VERSION ""

NS_ :

BS_:

BU_: BCM BSM DIAG_TEST ECM EPS IPC MTA ORC PAM

BO_ 2654339098 PDC_INFO_ORC: 3 ORC
 SG_ CurrentFailSts_ORC : 6|1@0+ (1,0) [0|1] ""  BCM
 SG_ DES_ORC : 4|1@0+ (1,0) [0|1] "" Vector__XXX
 SG_ EOL_ORC : 7|1@0+ (1,0) [0|1] "-"  BCM
 SG_ GenericFailSts_ORC : 5|1@0+ (1,0) [0|1] ""  BCM
 SG_ Reserved_for_PDC_ORC : 3|4@0+ (1,0) [0|0] "" Vector__XXX
 SG_ StayActiveSource_ORC_0 : 15|1@0+ (1,0) [0|1] "" Vector__XXX
 SG_ StayActiveSource_ORC_1 : 14|1@0+ (1,0) [0|1] "" Vector__XXX
 SG_ StayActiveSource_ORC_10 : 21|1@0+ (1,0) [0|1] "" Vector__XXX
 SG_ StayActiveSource_ORC_11 : 20|1@0+ (1,0) [0|1] "" Vector__XXX
 SG_ StayActiveSource_ORC_12 : 19|1@0+ (1,0) [0|1] "" Vector__XXX
 SG_ StayActiveSource_ORC_13 : 18|1@0+ (1,0) [0|1] "" Vector__XXX
 SG_ StayActiveSource_ORC_14 : 17|1@0+ (1,0) [0|1] "" Vector__XXX
 SG_ StayActiveSource_ORC_15 : 16|1@0+ (1,0) [0|1] "" Vector__XXX
 SG_ StayActiveSource_ORC_2 : 13|1@0+ (1,0) [0|1] "" Vector__XXX
 SG_ StayActiveSource_ORC_3 : 12|1@0+ (1,0) [0|1] "" Vector__XXX
 SG_ StayActiveSource_ORC_4 : 11|1@0+ (1,0) [0|1] "" Vector__XXX
 SG_ StayActiveSource_ORC_5 : 10|1@0+ (1,0) [0|1] "" Vector__XXX
 SG_ StayActiveSource_ORC_6 : 9|1@0+ (1,0) [0|1] "" Vector__XXX
 SG_ StayActiveSource_ORC_7 : 8|1@0+ (1,0) [0|1] "" Vector__XXX
 SG_ StayActiveSource_ORC_8 : 23|1@0+ (1,0) [0|1] "" Vector__XXX
 SG_ StayActiveSource_ORC_9 : 22|1@0+ (1,0) [0|1] "" Vector__XXX

BO_ 2654339096 PDC_INFO_PAM: 3 PAM
 SG_ CurrentFailSts_PAM : 6|1@0+ (1,0) [0|1] ""  BCM
 SG_ DES_PAM : 4|1@0+ (1,0) [0|1] "" Vector__XXX
 SG_ EOL_PAM : 7|1@0+ (1,0) [0|1] "-"  BCM
 SG_ GenericFailSts_PAM : 5|1@0+ (1,0) [0|1] ""  BCM
 SG_ Reserved_for_PDC_PAM : 3|4@0+ (1,0) [0|0] "" Vector__XXX
 SG_ StayActiveSource_PAM_0 : 15|1@0+ (1,0) [0|1] "" Vector__XXX
 SG_ StayActiveSource_PAM_1 : 14|1@0+ (1,0) [0|1] "" Vector__XXX
 SG_ StayActiveSource_PAM_10 : 21|1@0+ (1,0) [0|1] "" Vector__XXX
 SG_ StayActiveSource_PAM_11 : 20|1@0+ (1,0) [0|1] "" Vector__XXX
 SG_ StayActiveSource_PAM_12 : 19|1@0+ (1,0) [0|1] "" Vector__XXX
 SG_ StayActiveSource_PAM_13 : 18|1@0+ (1,0) [0|1] "" Vector__XXX
 SG_ StayActiveSource_PAM_14 : 17|1@0+ (1,0) [0|1] "" Vector__XXX
 SG_ StayActiveSource_PAM_15 : 16|1@0+ (1,0) [0|1] "" Vector__XXX
 SG_ StayActiveSource_PAM_2 : 13|1@0+ (1,0) [0|1] "" Vector__XXX
 SG_ StayActiveSource_PAM_3 : 12|1@0+ (1,0) [0|1] "" Vector__XXX
 SG_ StayActiveSource_PAM_4 : 11|1@0+ (1,0) [0|1] "" Vector__XXX
 SG_ StayActiveSource_PAM_5 : 10|1@0+ (1,0) [0|1] "" Vector__XXX
 SG_ StayActiveSource_PAM_6 : 9|1@0+ (1,0) [0|1] "" Vector__XXX
 SG_ StayActiveSource_PAM_7 : 8|1@0+ (1,0) [0|1] "" Vector__XXX
 SG_ StayActiveSource_PAM_8 : 23|1@0+ (1,0) [0|1] "" Vector__XXX
 SG_ StayActiveSource_PAM_9 : 22|1@0+ (1,0) [0|1] "" Vector__XXX

BO_ 2654339083 PDC_INFO_TRANSMISSION: 3 MTA
 SG_ CurrentFailSts_TRANSM : 6|1@0+ (1,0) [0|1] ""  BCM
 SG_ DES_TRANSM : 4|1@0+ (1,0) [0|1] "" Vector__XXX
 SG_ EOL_TRANSM : 7|1@0+ (1,0) [0|1] "-"  BCM
 SG_ GenericFailSts_TRANSM : 5|1@0+ (1,0) [0|1] ""  BCM
 SG_ Reserved_for_PDC_TRANSM : 3|4@0+ (1,0) [0|0] "" Vector__XXX
 SG_ StayActiveSource_TRANSM_0 : 15|1@0+ (1,0) [0|1] "" Vector__XXX
 SG_ StayActiveSource_TRANSM_1 : 14|1@0+ (1,0) [0|1] "" Vector__XXX
 SG_ StayActiveSource_TRANSM_10 : 21|1@0+ (1,0) [0|1] "" Vector__XXX
 SG_ StayActiveSource_TRANSM_11 : 20|1@0+ (1,0) [0|1] "" Vector__XXX
 SG_ StayActiveSource_TRANSM_12 : 19|1@0+ (1,0) [0|1] "" Vector__XXX
 SG_ StayActiveSource_TRANSM_13 : 18|1@0+ (1,0) [0|1] "" Vector__XXX
 SG_ StayActiveSource_TRANSM_14 : 17|1@0+ (1,0) [0|1] "" Vector__XXX
 SG_ StayActiveSource_TRANSM_15 : 16|1@0+ (1,0) [0|1] "" Vector__XXX
 SG_ StayActiveSource_TRANSM_2 : 13|1@0+ (1,0) [0|1] "" Vector__XXX
 SG_ StayActiveSource_TRANSM_3 : 12|1@0+ (1,0) [0|1] "" Vector__XXX
 SG_ StayActiveSource_TRANSM_4 : 11|1@0+ (1,0) [0|1] "" Vector__XXX
 SG_ StayActiveSource_TRANSM_5 : 10|1@0+ (1,0) [0|1] "" Vector__XXX
 SG_ StayActiveSource_TRANSM_6 : 9|1@0+ (1,0) [0|1] "" Vector__XXX
 SG_ StayActiveSource_TRANSM_7 : 8|1@0+ (1,0) [0|1] "" Vector__XXX
 SG_ StayActiveSource_TRANSM_8 : 23|1@0+ (1,0) [0|1] "" Vector__XXX
 SG_ StayActiveSource_TRANSM_9 : 22|1@0+ (1,0) [0|1] "" Vector__XXX

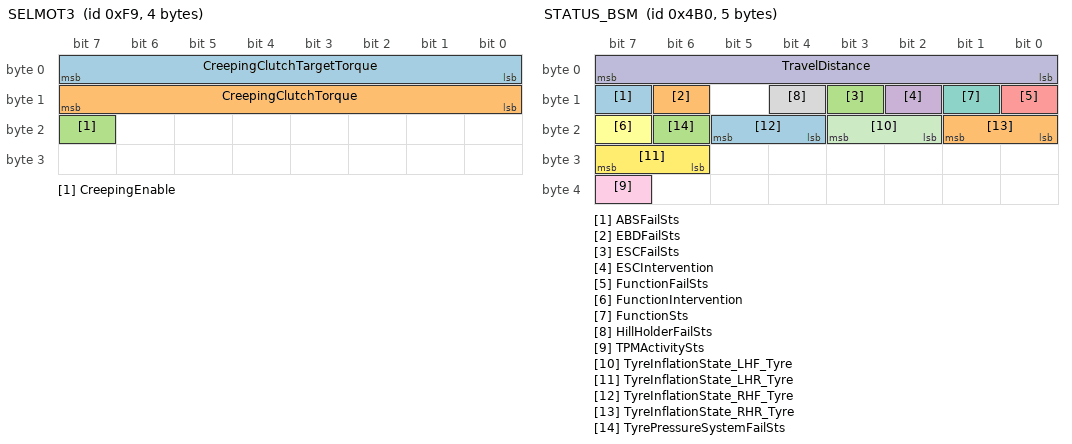
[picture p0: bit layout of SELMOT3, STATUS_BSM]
BO_ 249 SELMOT3: 4 MTA
 SG_ CreepingClutchTargetTorque : 7|8@0+ (1,0) [0|255] "Nm"  ECM
 SG_ CreepingClutchTorque : 15|8@0+ (1,0) [0|255] "Nm"  ECM
 SG_ CreepingEnable : 23|1@0+ (1,0) [0|1] ""  ECM

BO_ 1200 STATUS_BSM: 5 BSM
 SG_ ABSFailSts : 15|1@0+ (1,0) [0|1] "-"  IPC,MTA
 SG_ EBDFailSts : 14|1@0+ (1,0) [0|1] "-"  IPC
 SG_ ESCFailSts : 11|1@0+ (1,0) [0|1] "-"  IPC,MTA
 SG_ ESCIntervention : 10|1@0+ (1,0) [0|1] "-"  IPC,MTA
 SG_ FunctionFailSts : 8|1@0+ (1,0) [0|1] "-" Vector__XXX
 SG_ FunctionIntervention : 23|1@0+ (1,0) [0|1] "-" Vector__XXX
 SG_ FunctionSts : 9|1@0+ (1,0) [0|1] "-"  IPC
 SG_ HillHolderFailSts : 12|1@0+ (1,0) [0|1] "-"  ECM,IPC,MTA
 SG_ TPMActivitySts : 39|1@0+ (1,0) [0|1] ""  IPC
 SG_ TravelDistance : 7|8@0+ (9.8,0) [0|2489.2] "m"  BCM,ECM,IPC
 SG_ TyreInflationState_LHF_Tyre : 19|2@0+ (1,0) [0|3] ""  IPC
 SG_ TyreInflationState_LHR_Tyre : 31|2@0+ (1,0) [0|3] ""  IPC
 SG_ TyreInflationState_RHF_Tyre : 21|2@0+ (1,0) [0|3] ""  IPC
 SG_ TyreInflationState_RHR_Tyre : 17|2@0+ (1,0) [0|3] ""  IPC
 SG_ TyrePressureSystemFailSts : 22|1@0+ (1,0) [0|1] ""  IPC

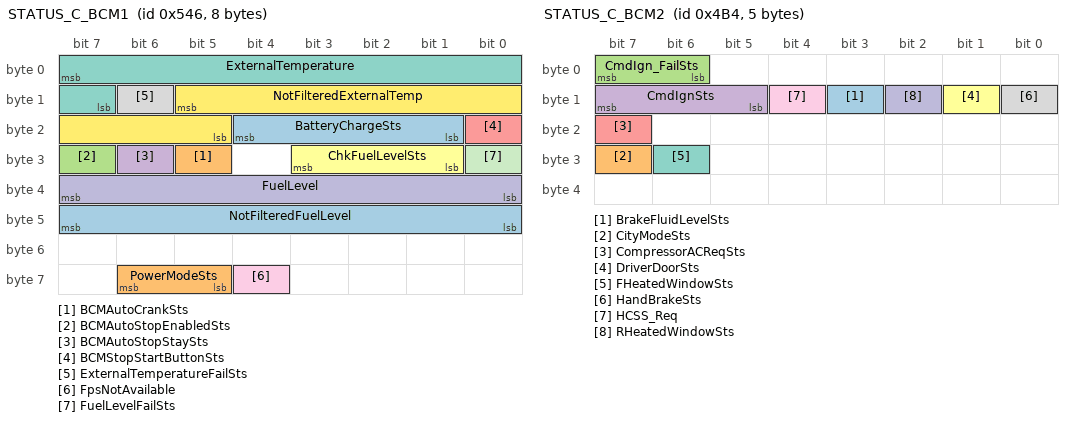
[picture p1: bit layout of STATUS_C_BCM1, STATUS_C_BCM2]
BO_ 1350 STATUS_C_BCM1: 8 BCM
 SG_ BatteryChargeSts : 20|4@0+ (5,40) [40|110] "%"  ECM
 SG_ BCMAutoCrankSts : 29|1@0+ (1,0) [0|1] "-"  ECM
 SG_ BCMAutoStopEnabledSts : 31|1@0+ (1,0) [0|1] "-"  ECM
 SG_ BCMAutoStopStaySts : 30|1@0+ (1,0) [0|1] "-"  ECM
 SG_ BCMStopStartButtonSts : 16|1@0+ (1,0) [0|1] "-"  ECM
 SG_ ChkFuelLevelSts : 27|3@0+ (1,0) [0|7] "-" Vector__XXX
 SG_ ExternalTemperature : 7|9@0+ (0.5,-85) [-85|170] "°C"  BSM,ECM,MTA
 SG_ ExternalTemperatureFailSts : 14|1@0+ (1,0) [0|1] ""  BSM,ECM,MTA
 SG_ FpsNotAvailable : 60|1@0+ (1,0) [0|1] ""  IPC
 SG_ FuelLevel : 39|8@0+ (1,0) [0|255] "%"  ECM,IPC
 SG_ FuelLevelFailSts : 24|1@0+ (1,0) [0|1] ""  ECM,IPC
 SG_ NotFilteredExternalTemp : 13|9@0+ (0.5,-85) [-85|170] "°C" Vector__XXX
 SG_ NotFilteredFuelLevel : 47|8@0+ (2,0) [0|508] "Ohm"  ECM
 SG_ PowerModeSts : 62|2@0+ (1,0) [0|3] "-"  IPC

BO_ 1204 STATUS_C_BCM2: 5 BCM
 SG_ BrakeFluidLevelSts : 11|1@0+ (1,0) [0|1] ""  IPC
 SG_ CityModeSts : 31|1@0+ (1,0) [0|1] "-"  EPS,IPC
 SG_ CmdIgn_FailSts : 7|2@0+ (1,0) [0|3] ""  BSM,ECM,EPS,IPC,MTA,PAM
 SG_ CmdIgnSts : 15|3@0+ (1,0) [0|7] ""  BSM,ECM,EPS,IPC,MTA,ORC,PAM
 SG_ CompressorACReqSts : 23|1@0+ (1,0) [0|1] "-"  ECM
 SG_ DriverDoorSts : 9|1@0+ (1,0) [0|1] ""  MTA
 SG_ FHeatedWindowSts : 30|1@0+ (1,0) [0|1] ""  ECM
 SG_ HandBrakeSts : 8|1@0+ (1,0) [0|1] "-"  BSM,ECM,IPC,MTA
 SG_ HCSS_Req : 12|1@0+ (1,0) [0|1] ""  ECM
 SG_ RHeatedWindowSts : 10|1@0+ (1,0) [0|1] "" Vector__XXX

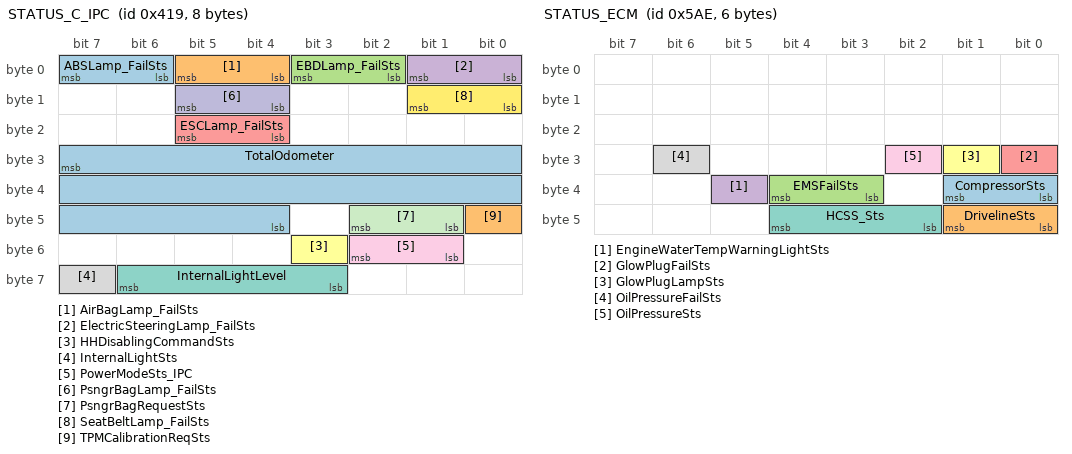
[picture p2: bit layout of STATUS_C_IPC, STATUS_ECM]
BO_ 1049 STATUS_C_IPC: 8 IPC
 SG_ ABSLamp_FailSts : 7|2@0+ (1,0) [0|3] "-"  BSM
 SG_ AirBagLamp_FailSts : 5|2@0+ (1,0) [0|3] "-"  ORC
 SG_ EBDLamp_FailSts : 3|2@0+ (1,0) [0|3] "-"  BSM
 SG_ ElectricSteeringLamp_FailSts : 1|2@0+ (1,0) [0|3] "-"  EPS
 SG_ ESCLamp_FailSts : 21|2@0+ (1,0) [0|0] "-"  BSM
 SG_ HHDisablingCommandSts : 51|1@0+ (1,0) [0|1] ""  BSM
 SG_ InternalLightLevel : 62|4@0+ (1,0) [0|15] "" Vector__XXX
 SG_ InternalLightSts : 63|1@0+ (1,0) [0|1] ""  BCM
 SG_ PowerModeSts_IPC : 50|2@0+ (1,0) [0|3] ""  BCM
 SG_ PsngrBagLamp_FailSts : 13|2@0+ (1,0) [0|3] "-"  ORC
 SG_ PsngrBagRequestSts : 42|2@0+ (1,0) [0|3] "-"  ORC
 SG_ SeatBeltLamp_FailSts : 9|2@0+ (1,0) [0|3] "-"  ORC
 SG_ TotalOdometer : 31|20@0+ (1,0) [0|1048575] "km"  EPS,BSM,ECM,MTA,ORC,PAM
 SG_ TPMCalibrationReqSts : 40|1@0+ (1,0) [0|1] ""  BSM

BO_ 1454 STATUS_ECM: 6 ECM
 SG_ CompressorSts : 33|2@0+ (1,0) [0|3] "-"  BCM,MTA
 SG_ DrivelineSts : 41|2@0+ (1,0) [0|3] ""  IPC
 SG_ EMSFailSts : 36|2@0+ (1,0) [0|3] "-"  IPC
 SG_ EngineWaterTempWarningLightSts : 37|1@0+ (1,0) [0|1] "-"  IPC
 SG_ GlowPlugFailSts : 24|1@0+ (1,0) [0|1] "-"  IPC
 SG_ GlowPlugLampSts : 25|1@0+ (1,0) [0|1] "-"  IPC
 SG_ HCSS_Sts : 44|3@0+ (1,0) [0|7] "-"  BCM
 SG_ OilPressureFailSts : 30|1@0+ (1,0) [0|1] "-"  IPC
 SG_ OilPressureSts : 26|1@0+ (1,0) [0|1] "-"  IPC

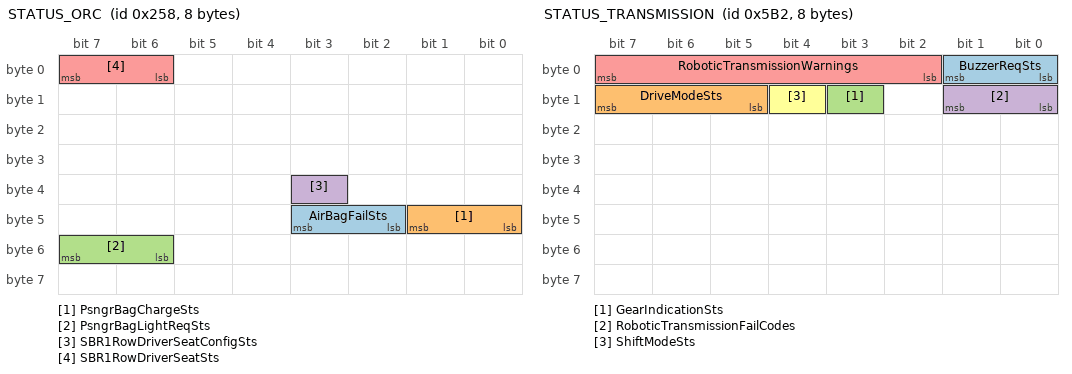
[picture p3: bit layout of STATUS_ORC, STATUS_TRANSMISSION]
BO_ 600 STATUS_ORC: 8 ORC
 SG_ AirBagFailSts : 43|2@0+ (1,0) [0|3] "-"  IPC
 SG_ PsngrBagChargeSts : 41|2@0+ (1,0) [0|3] "-"  IPC
 SG_ PsngrBagLightReqSts : 55|2@0+ (1,0) [0|3] ""  IPC
 SG_ SBR1RowDriverSeatConfigSts : 35|1@0+ (1,0) [0|1] "-"  IPC
 SG_ SBR1RowDriverSeatSts : 7|2@0+ (1,0) [0|3] "-"  BCM,IPC

BO_ 1354 STATUS_PAM: 4 PAM
 SG_ PAMSystemFault : 13|2@0+ (1,0) [0|3] "-"  IPC
 SG_ PAMSystemSts : 9|2@0+ (1,0) [0|3] ""  IPC

BO_ 1458 STATUS_TRANSMISSION: 8 MTA
 SG_ BuzzerReqSts : 1|2@0+ (1,0) [0|2] "-"  IPC
 SG_ DriveModeSts : 15|3@0+ (1,0) [0|4] "-"  ECM,IPC
 SG_ GearIndicationSts : 11|1@0+ (1,0) [0|1] "-"  IPC
 SG_ RoboticTransmissionFailCodes : 9|2@0+ (1,0) [0|3] "-"  IPC
 SG_ RoboticTransmissionWarnings : 7|6@0+ (1,0) [0|10] "-"  IPC
 SG_ ShiftModeSts : 12|1@0+ (1,0) [0|1] "-"  BCM,IPC

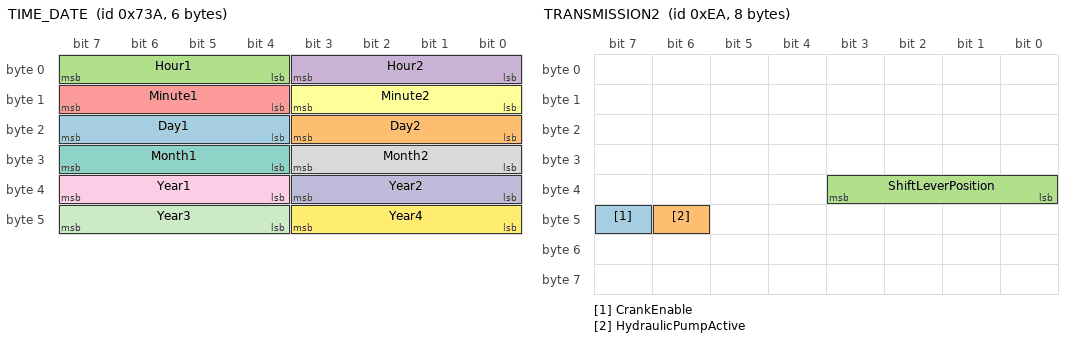
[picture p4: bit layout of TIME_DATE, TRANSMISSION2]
BO_ 1850 TIME_DATE: 6 IPC
 SG_ Day1 : 23|4@0+ (1,0) [0|9] "-"  BSM,ECM
 SG_ Day2 : 19|4@0+ (1,0) [0|9] "-"  BSM,ECM
 SG_ Hour1 : 7|4@0+ (1,0) [0|9] "-"  BSM,ECM
 SG_ Hour2 : 3|4@0+ (1,0) [0|9] "-"  BSM,ECM
 SG_ Minute1 : 15|4@0+ (1,0) [0|9] "-"  BSM,ECM
 SG_ Minute2 : 11|4@0+ (1,0) [0|9] "-"  BSM,ECM
 SG_ Month1 : 31|4@0+ (1,0) [0|9] "-"  BSM,ECM
 SG_ Month2 : 27|4@0+ (1,0) [0|9] "-"  BSM,ECM
 SG_ Year1 : 39|4@0+ (1,0) [0|9] "-"  BSM,ECM
 SG_ Year2 : 35|4@0+ (1,0) [0|9] "-"  BSM,ECM
 SG_ Year3 : 47|4@0+ (1,0) [0|9] "-"  BSM,ECM
 SG_ Year4 : 43|4@0+ (1,0) [0|9] "-"  BSM,ECM

BO_ 1000 TPM_CAL: 1 BSM
 SG_ CalibrationAck : 5|2@0+ (1,0) [0|3] "-"  IPC

BO_ 246 TRANSMISSION1: 8 MTA
 SG_ ClutchEngaged : 7|2@0+ (1,0) [0|3] "-"  ECM
 SG_ CRC_T1 : 63|8@0+ (1,0) [0|255] "-"  ECM
 SG_ DriveOff : 5|1@0+ (1,0) [0|1] "-"  ECM
 SG_ EngineStopSignal : 4|1@0+ (1,0) [0|1] "-"  ECM
 SG_ GearBoxAutomaticMode : 15|1@0+ (1,0) [0|1] "-"  ECM
 SG_ GearEngaged : 3|4@0+ (1,0) [0|15] "-"  BSM,ECM,IPC
 SG_ LeverPosition : 35|4@0+ (1,0) [0|15] "-"  ECM
 SG_ LimpHomeSts : 14|1@0+ (1,0) [0|1] "-"  ECM
 SG_ MessageCounter_T1 : 51|4@0+ (1,0) [0|15] ""  ECM
 SG_ ReqTorqueValue : 47|11@0+ (1,-500) [-500|1547] "Nm"  ECM
 SG_ ReqTorqueValueCost : 11|1@0+ (1,0) [0|1] "-"  ECM
 SG_ ReqTorqueValueDown : 10|1@0+ (1,0) [0|1] "-"  ECM
 SG_ ReqTorqueValueUp : 9|1@0+ (1,0) [0|1] "-"  ECM
 SG_ TakeOffModeReq : 13|2@0+ (1,0) [0|3] "-"  ECM
 SG_ TakeOffRPMValueReq : 31|10@0+ (10,0) [0|0] "rpm"  ECM
 SG_ TorqueControl : 8|1@0+ (1,0) [0|1] "-"  ECM
 SG_ UpDownShiftSel : 37|1@0+ (1,0) [0|1] "-"  ECM

BO_ 234 TRANSMISSION2: 8 MTA
 SG_ CrankEnable : 47|1@0+ (1,0) [0|1] ""  BCM,ECM
 SG_ HydraulicPumpActive : 46|1@0+ (1,0) [0|1] ""  ECM
 SG_ ShiftLeverPosition : 35|4@0+ (1,0) [0|15] "-"  BCM,BSM,ECM

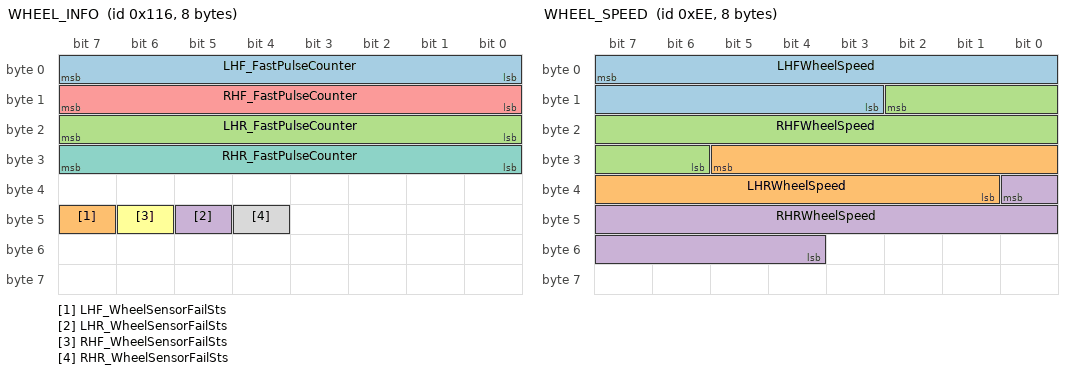
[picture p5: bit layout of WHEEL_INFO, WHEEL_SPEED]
BO_ 278 WHEEL_INFO: 8 BSM
 SG_ LHF_FastPulseCounter : 7|8@0+ (1,0) [0|255] "pulse"  BCM
 SG_ LHF_WheelSensorFailSts : 47|1@0+ (1,0) [0|1] "-"  BCM
 SG_ LHR_FastPulseCounter : 23|8@0+ (1,0) [0|255] "pulse"  BCM
 SG_ LHR_WheelSensorFailSts : 45|1@0+ (1,0) [0|1] "-"  BCM
 SG_ RHF_FastPulseCounter : 15|8@0+ (1,0) [0|255] "pulse"  BCM
 SG_ RHF_WheelSensorFailSts : 46|1@0+ (1,0) [0|1] "-"  BCM
 SG_ RHR_FastPulseCounter : 31|8@0+ (1,0) [0|255] "pulse"  BCM
 SG_ RHR_WheelSensorFailSts : 44|1@0+ (1,0) [0|1] "-"  BCM

BO_ 238 WHEEL_SPEED: 8 BSM
 SG_ LHFWheelSpeed : 7|13@0+ (0.0625,0) [0|512] "Km/h"  ECM,MTA
 SG_ LHRWheelSpeed : 29|13@0+ (0.0625,0) [0|512] "Km/h"  ECM,MTA
 SG_ RHFWheelSpeed : 10|13@0+ (0.0625,0) [0|512] "Km/h"  ECM,MTA
 SG_ RHRWheelSpeed : 32|13@0+ (0.0625,0) [0|512] "Km/h"  ECM,MTA

CM_ SG_ 249 CreepingClutchTargetTorque "Clutch torque reference in creeping phase";
CM_ SG_ 249 CreepingClutchTorque "Clutch torque saturation actuted in creeping phase";
CM_ SG_ 249 CreepingEnable "TCU Creeping phase active";
CM_ SG_ 1200 ABSFailSts "This signal indicates when ABS functionality is in fail";
CM_ SG_ 1200 EBDFailSts "This signal indicates when EBD functionality is in fail";
CM_ SG_ 1200 ESCFailSts "This signal indicates when ESC functionality is in fail.";
CM_ SG_ 1200 ESCIntervention "This signal indicates when the ESC functionality is acting.";
CM_ SG_ 1200 FunctionFailSts "This signal indicates when ASR/TC functionality is in fail.";
CM_ SG_ 1200 FunctionIntervention "This signal indicates when the TC or ASR or ELD (where present) functionality are acting.";
CM_ SG_ 1200 FunctionSts "This signal is set to ?Pressed? when the BSM Button is pressed for the first time inside an ignition cycle . This signal is available only on ESC variants with BSM Button.";
CM_ SG_ 1200 HillHolderFailSts "This signal indicates when Hill Holder functionality is in fail";
CM_ SG_ 1200 TPMActivitySts "It indicates if the module is enabled or disabled.";
CM_ SG_ 1200 TravelDistance "This signal indicates the travel distance value.";
CM_ SG_ 1200 TyreInflationState_LHF_Tyre "It indicates the inflation state of the tyre.";
CM_ SG_ 1200 TyreInflationState_LHR_Tyre "It indicates the inflation state of the tyre.";
CM_ SG_ 1200 TyreInflationState_RHF_Tyre "It indicates the inflation state of the tyre.";
CM_ SG_ 1200 TyreInflationState_RHR_Tyre "It indicates the inflation state of the tyre.";
CM_ SG_ 1200 TyrePressureSystemFailSts "It indicates the presence of the failure.";
CM_ SG_ 1350 BatteryChargeSts "Signal the battery state of charge, as measured by the battery sensor";
CM_ SG_ 1350 BCMAutoCrankSts "This signal indicates to ECM the possibility for ECM, when the engine is in automatic stop, to allow an automatic engine recranking or to allow a recranking of the engine only by a transition keyoff/keyon.";
CM_ SG_ 1350 BCMAutoStopEnabledSts "This signal indicates to the ECM the conditions managed by BCM needed for enabling the automatic stop.";
CM_ SG_ 1350 BCMAutoStopStaySts "This signal indicates the possibility for the ECM, when the engine is in automatic stop, to remain in Automatic Engine Stop condition or automatically recrank the engine.";
CM_ SG_ 1350 BCMStopStartButtonSts "BCM request to the ECM for the Stop&Start management";
CM_ SG_ 1350 ChkFuelLevelSts "This signal gives indication about diagnostic of CILC.";
CM_ SG_ 1350 ExternalTemperature "The ExternalTemperature signal is a External Temperature value acquired by the External Temperature Sensor. This value is \"filtered\" with the purpose to return reliable values.";
CM_ SG_ 1350 ExternalTemperatureFailSts "The ExternalTemperatureFailSts signal is a Fail Status Bit for the ExternalTemperature signal.";
CM_ SG_ 1350 FpsNotAvailable "It's used by BCM to inform IPC that Safety Fuel Shut Off function is not available";
CM_ SG_ 1350 FuelLevel "The signal represents fuel level and it is expressed in percentage with respect to the tank nominal capacity.";
CM_ SG_ 1350 FuelLevelFailSts "It is the Fail Status bit of FuelLevel signal.";
CM_ SG_ 1350 NotFilteredExternalTemp "This signal represents External Temperature value measured by related sensor. Its value is not filtered by BCM internal strategies.";
CM_ SG_ 1350 NotFilteredFuelLevel "This signal represents Fuel Level value measured by related sensor. Its value is not filtered by BCM internal strategies.";
CM_ SG_ 1350 PowerModeSts "This signal indicates if the vehicle is in Logistic Mode status or in Standard Mode status.";
CM_ SG_ 1204 BrakeFluidLevelSts "This signal indicates when the brake fluid level is low or normal.";
CM_ SG_ 1204 CityModeSts "It is the information about city/eco/power/sport mode";
CM_ SG_ 1204 CmdIgnSts "Used to give information about the key selector position";
CM_ SG_ 1204 CompressorACReqSts "This signal is sent from BCM to ECM to inform of Compressor AC activation request";
CM_ SG_ 1204 DriverDoorSts "This signal indicates the driver door status";
CM_ SG_ 1204 FHeatedWindowSts "The signal indicates the effective activation of heated front window.";
CM_ SG_ 1204 HandBrakeSts "This signal indicates the hand brake status (inserted or not).";
CM_ SG_ 1204 HCSS_Req "The signal is used to request the HCSS activation.";
CM_ SG_ 1204 RHeatedWindowSts "The signal indicates the effective activation of heated rear window.";
CM_ SG_ 1049 ABSLamp_FailSts "This signal communicates the status of the related lamp.";
CM_ SG_ 1049 AirBagLamp_FailSts "This signal is used to inform about the airbag warning light status";
CM_ SG_ 1049 EBDLamp_FailSts "This signal communicates the status of the related lamp.";
CM_ SG_ 1049 ElectricSteeringLamp_FailSts "This signal communicates the status of the related lamp.";
CM_ SG_ 1049 ESCLamp_FailSts "This signal communicates the status of the related lamp.";
CM_ SG_ 1049 HHDisablingCommandSts "This signal requires the disabling of Hill Holder functionality.";
CM_ SG_ 1049 InternalLightLevel "This signal is used to modulate the Internal Light Level";
CM_ SG_ 1049 InternalLightSts "This signal is used to manage the Internal Lights";
CM_ SG_ 1049 PsngrBagLamp_FailSts "This signal communicates the status of the related lamp.";
CM_ SG_ 1049 PsngrBagRequestSts "This signal is used by IPC to send the request of the customer to change the current status of Front Passenger Protection";
CM_ SG_ 1049 SeatBeltLamp_FailSts "This signal is used to inform about the SBR main lamp status";
CM_ SG_ 1049 TPMCalibrationReqSts "It indicates that the user requires to start the calibration procedure of TPI";
CM_ SG_ 1454 CompressorSts "This signal gives information about the present status of A/C external request and actual A/C activation by ECM.";
CM_ SG_ 1454 DrivelineSts "Gives the status of the driveline, based on clutch and/or neutral sensors";
CM_ SG_ 1454 EMSFailSts "This signal is used  to switch on and off the engine control system warning lamp (called MI for EOBD applications)";
CM_ SG_ 1454 EngineWaterTempWarningLightSts "It is the information about water overtemperature light status.";
CM_ SG_ 1454 GlowPlugFailSts "It is the information that a fault is detected by glow plug control unit.";
CM_ SG_ 1454 GlowPlugLampSts "It is the glow plug light command.";
CM_ SG_ 1454 HCSS_Sts "The signal indicates the HCSS phase.";
CM_ SG_ 1454 OilPressureFailSts "It is the Fail Status bit of OilPressure signal.";
CM_ SG_ 1454 OilPressureSts "This signal  indicates oil pressure status (High or low).";
CM_ SG_ 600 AirBagFailSts "This signal is used to require the activation/deactivation of airbag warning light";
CM_ SG_ 600 PsngrBagChargeSts "This signal is used to communicate the status of Front Passenger Protection Pyrotechnical charges";
CM_ SG_ 600 PsngrBagLightReqSts "This signal indicates the status of the Front Passenger Airbag Warning Lamp";
CM_ SG_ 600 SBR1RowDriverSeatConfigSts "Signal used to show if the first row driver seatbelt is under check";
CM_ SG_ 600 SBR1RowDriverSeatSts "First row driver seatbelt switch status";
CM_ SG_ 1354 PAMSystemFault "This signal indicates if the PAM is in a faulted condition";
CM_ SG_ 1354 PAMSystemSts "This signal indicates the activation state of the PAM";
CM_ SG_ 1458 BuzzerReqSts "It is used to activate the acoustic indicator.";
CM_ SG_ 1458 DriveModeSts "This signal indicates the mode selector switch condition selected by driver (Normal, Economy, Sport, Ice,...).";
CM_ SG_ 1458 GearIndicationSts "This signal is related to the displayed gear indication (if it is blinking or not)";
CM_ SG_ 1458 RoboticTransmissionFailCodes "This signal indicates if the MTA currently detects the failure or not (for MTA)";
CM_ SG_ 1458 RoboticTransmissionWarnings "This signal gives some instruction to the driver in case of malfunctioning (for MTA)";
CM_ SG_ 1458 ShiftModeSts "This signal indicates the gear selector modality selected by driver (Manual or Automatic).";
CM_ SG_ 1850 Day1 "It is the first digit of the day for the date visualization";
CM_ SG_ 1850 Day2 "It is the second digit of the day for the date visualization";
CM_ SG_ 1850 Hour1 "It is the first digit of the hours for the clock visualization";
CM_ SG_ 1850 Hour2 "It is the second digit of the hours for the clock visualization";
CM_ SG_ 1850 Minute1 "It is  the first digit of the minutes for the clock visualization";
CM_ SG_ 1850 Minute2 "It is the second digit of the minutes for the clock visualization";
CM_ SG_ 1850 Month1 "It is the first digit of the month for the date visualization";
CM_ SG_ 1850 Month2 "It is the second digit of the month for the date visualization";
CM_ SG_ 1850 Year1 "It is the first digit of the year for the date visualization";
CM_ SG_ 1850 Year2 "It is the second digit of the year for the date visualization";
CM_ SG_ 1850 Year3 "It is the third digit of the year for the date visualization";
CM_ SG_ 1850 Year4 "It is the fourth digit of the year for the date visualization";
CM_ SG_ 1000 CalibrationAck "It indicates the acknoledgment of calibration procedure request.";
CM_ SG_ 246 ClutchEngaged "It can be used to prevent engine stall by improving the idle condition entering strategy, in case of sudden engine speed drops (due, for instance, to hard braking action)";
CM_ SG_ 246 CRC_T1 "CRC according to SAE J1850 standard that has to be calculated from bit 63 to bit 8 at each frame transmission.";
CM_ SG_ 246 DriveOff "When the bit is switching from ON to OFF, the clutch is engaging and the vehicle is driving away from stop condition.";
CM_ SG_ 246 EngineStopSignal "This signal is used to stop the engine, when very critical failures occur to the gearbox.";
CM_ SG_ 246 GearBoxAutomaticMode "It indicates the gearbox operating mode (this is automatic when the signal value is 'Active' ).";
CM_ SG_ 246 GearEngaged "Current engaged gear.";
CM_ SG_ 246 LeverPosition "This signal indicates the position of the lever.";
CM_ SG_ 246 LimpHomeSts "This signal is used in case of those gearbox faults that limit the higher usable gear.";
CM_ SG_ 246 MessageCounter_T1 "This signal is a counter used for safety checks strategies. This counter is incremented of 1 (one) unit at each frame transmission.";
CM_ SG_ 246 ReqTorqueValue "This is the total indicated torque target requested from the gearbox  during gear shifts.";
CM_ SG_ 246 ReqTorqueValueCost "It indicates the 2nd phase of the torque request from the gearbox , i.e.: it is 'Active'  during the 2nd phase of a gear shift.
In this phase (new gear engagement) the clutch is open.";
CM_ SG_ 246 ReqTorqueValueDown "It indicates the 1st phase of the torque request from the gearbox , i.e.: it is 'Active' during the 1st phase of a gear shift.
In this phase (engine disconnection) the gearbox  is disengaging the clutch.";
CM_ SG_ 246 ReqTorqueValueUp "It indicates the 3rd phase of the torque request from the gearbox , i.e.: it is 'Active' during the 3rd phase of a gear shift.
In this phase (engine re-connection) the gearbox is re-engaging the clutch.";
CM_ SG_ 246 TakeOffModeReq "This signal indicates if either the torque control request or the torque/rpm control request are active during the take-off phase";
CM_ SG_ 246 TakeOffRPMValueReq "RPM set-point requested by gearbox during take-off phase. This signal is required and managed on Turbo Gasoline Engines only.";
CM_ SG_ 246 TorqueControl "It indicates a torque request from the gearbox , i.e.: it is 'Active' during all the three phases of a gear shift.";
CM_ SG_ 246 UpDownShiftSel "It is mainly foreseen for gasoline applications. This bit is set to ' Up'  during an up-shift and to ' Down'  during a down-shift.";
CM_ SG_ 234 CrankEnable "This signal is used to enable the cranking in safety condition";
CM_ SG_ 234 HydraulicPumpActive "This bit is  'Active'  when the electro-hydraulic pump is ON.
It can be used for engine idle control.";
CM_ SG_ 234 ShiftLeverPosition "This signal indicates the executed shift lever position.";
CM_ SG_ 278 LHF_FastPulseCounter "This signal is the left front wheel pulse counter.";
CM_ SG_ 278 LHF_WheelSensorFailSts "This signal indicates the fail status of LHF sensor";
CM_ SG_ 278 LHR_FastPulseCounter "This signal is the left rear wheel pulse counter.";
CM_ SG_ 278 LHR_WheelSensorFailSts "This signal indicates the fail status of LHR sensor";
CM_ SG_ 278 RHF_FastPulseCounter "This signal is the right front wheel pulse counter.";
CM_ SG_ 278 RHF_WheelSensorFailSts "This signal indicates the fail status of RHF sensor";
CM_ SG_ 278 RHR_FastPulseCounter "This signal is the right rear wheel pulse counter.";
CM_ SG_ 278 RHR_WheelSensorFailSts "This signal indicates the fail status of RHR sensor";
CM_ SG_ 238 LHFWheelSpeed "This is the value of the left front wheel speed";
CM_ SG_ 238 LHRWheelSpeed "This is the value of the left rear wheel speed";
CM_ SG_ 238 RHFWheelSpeed "This is the value of the right front wheel speed";
CM_ SG_ 238 RHRWheelSpeed "This is the value of the right rear wheel speed";
BA_DEF_ SG_  "GenSigStartValue" INT 0 2147483647;
BA_DEF_ SG_  "GenSigInactiveValue" INT 0 2147483647;
BA_DEF_ SG_  "GenSigSendType" ENUM  "NotUsed","OnWrite","OnWriteWithRepetition","OnChange","OnChangeWithRepetition","IfActive","IfActiveWithRepetition","NoSigSendType";
BA_DEF_ SG_  "GenSigTimeoutTime_BCM" INT 0 65535;
BA_DEF_ SG_  "GenSigTimeoutTime_BSM" INT 0 65535;
BA_DEF_ SG_  "GenSigTimeoutTime_DIAG_TEST" INT 0 65535;
BA_DEF_ SG_  "GenSigTimeoutTime_ECM" INT 0 65535;
BA_DEF_ SG_  "GenSigTimeoutTime_EPS" INT 0 65535;
BA_DEF_ SG_  "GenSigTimeoutTime_IPC" INT 0 65535;
BA_DEF_ SG_  "GenSigTimeoutTime_MTA" INT 0 65535;
BA_DEF_ SG_  "GenSigTimeoutTime_ORC" INT 0 65535;
BA_DEF_ SG_  "GenSigTimeoutTime_PAM" INT 0 65535;
BA_DEF_ BO_  "DiagRequest" ENUM  "No","Yes";
BA_DEF_ BO_  "Type" ENUM  "P","C","PE","COC","PE_Cntrl","E","E_Cntrl","OC","S","BAF","DC","EM","MM","-";
BA_DEF_ BO_  "DiagResponse" ENUM  "No","Yes";
BA_DEF_ BO_  "NmMessage" ENUM  "No","Yes";
BA_DEF_ BO_  "GenMsgSendType" ENUM  "Cyclic","NotUsed","NotUsed","NotUsed","NotUsed","NotUsed","NotUsed","NotUsed","NoMsgSendType";
BA_DEF_ BO_  "GenMsgNrOfRepetition" INT 0 255;
BA_DEF_ BO_  "GenMsgILSupport" ENUM  "No","Yes";
BA_DEF_ BO_  "GenMsgStartDelayTime" INT 0 65535;
BA_DEF_ BO_  "GenMsgCycleTimeFast" INT 0 65535;
BA_DEF_ BO_  "GenMsgCycleTime" INT 0 65535;
BA_DEF_ BO_  "GenMsgDelayTime" INT 0 65535;
BA_DEF_ BO_  "NmAsrMessage" ENUM  "No","Yes";
BA_DEF_ BO_  "DiagState" ENUM  "No","Yes";
BA_DEF_ BO_  "DiagConnection" HEX 0 65535;
BA_DEF_DEF_  "GenSigStartValue" 0;
BA_DEF_DEF_  "GenSigInactiveValue" 0;
BA_DEF_DEF_  "GenSigSendType" "NoSigSendType";
BA_DEF_DEF_  "GenSigTimeoutTime_BCM" 2500;
BA_DEF_DEF_  "GenSigTimeoutTime_BSM" 2500;
BA_DEF_DEF_  "GenSigTimeoutTime_DIAG_TEST" 2500;
BA_DEF_DEF_  "GenSigTimeoutTime_ECM" 2500;
BA_DEF_DEF_  "GenSigTimeoutTime_EPS" 2500;
BA_DEF_DEF_  "GenSigTimeoutTime_IPC" 2500;
BA_DEF_DEF_  "GenSigTimeoutTime_MTA" 2500;
BA_DEF_DEF_  "GenSigTimeoutTime_ORC" 2500;
BA_DEF_DEF_  "GenSigTimeoutTime_PAM" 2500;
BA_DEF_DEF_  "DiagRequest" "No";
BA_DEF_DEF_  "Type" "-";
BA_DEF_DEF_  "DiagResponse" "No";
BA_DEF_DEF_  "NmMessage" "No";
BA_DEF_DEF_  "GenMsgSendType" "NoMsgSendType";
BA_DEF_DEF_  "GenMsgNrOfRepetition" 0;
BA_DEF_DEF_  "GenMsgILSupport" "No";
BA_DEF_DEF_  "GenMsgStartDelayTime" 0;
BA_DEF_DEF_  "GenMsgCycleTimeFast" 0;
BA_DEF_DEF_  "GenMsgCycleTime" 0;
BA_DEF_DEF_  "GenMsgDelayTime" 0;
BA_DEF_DEF_  "NmAsrMessage" "No";
BA_DEF_DEF_  "DiagState" "No";
BA_DEF_DEF_  "DiagConnection" 0;
BA_ "Type" BO_ 2654339098 1;
BA_ "GenMsgSendType" BO_ 2654339098 0;
BA_ "GenMsgILSupport" BO_ 2654339098 1;
BA_ "GenMsgStartDelayTime" BO_ 2654339098 460;
BA_ "GenMsgCycleTime" BO_ 2654339098 1000;
BA_ "Type" BO_ 2654339096 1;
BA_ "GenMsgSendType" BO_ 2654339096 0;
BA_ "GenMsgILSupport" BO_ 2654339096 1;
BA_ "GenMsgStartDelayTime" BO_ 2654339096 440;
BA_ "GenMsgCycleTime" BO_ 2654339096 1000;
BA_ "Type" BO_ 2654339083 1;
BA_ "GenMsgSendType" BO_ 2654339083 0;
BA_ "GenMsgILSupport" BO_ 2654339083 1;
BA_ "GenMsgStartDelayTime" BO_ 2654339083 270;
BA_ "GenMsgCycleTime" BO_ 2654339083 1000;
BA_ "Type" BO_ 249 1;
BA_ "GenMsgSendType" BO_ 249 0;
BA_ "GenMsgILSupport" BO_ 249 1;
BA_ "GenMsgStartDelayTime" BO_ 249 8;
BA_ "GenMsgCycleTime" BO_ 249 10;
BA_ "Type" BO_ 1200 3;
BA_ "GenMsgSendType" BO_ 1200 0;
BA_ "GenMsgNrOfRepetition" BO_ 1200 2;
BA_ "GenMsgILSupport" BO_ 1200 1;
BA_ "GenMsgStartDelayTime" BO_ 1200 255;
BA_ "GenMsgCycleTimeFast" BO_ 1200 10;
BA_ "GenMsgCycleTime" BO_ 1200 500;
BA_ "GenMsgDelayTime" BO_ 1200 10;
BA_ "Type" BO_ 1350 1;
BA_ "GenMsgSendType" BO_ 1350 0;
BA_ "GenMsgILSupport" BO_ 1350 1;
BA_ "GenMsgStartDelayTime" BO_ 1350 125;
BA_ "GenMsgCycleTime" BO_ 1350 250;
BA_ "Type" BO_ 1204 3;
BA_ "GenMsgSendType" BO_ 1204 0;
BA_ "GenMsgNrOfRepetition" BO_ 1204 2;
BA_ "GenMsgILSupport" BO_ 1204 1;
BA_ "GenMsgStartDelayTime" BO_ 1204 250;
BA_ "GenMsgCycleTimeFast" BO_ 1204 10;
BA_ "GenMsgCycleTime" BO_ 1204 500;
BA_ "GenMsgDelayTime" BO_ 1204 10;
BA_ "Type" BO_ 1049 3;
BA_ "GenMsgSendType" BO_ 1049 0;
BA_ "GenMsgILSupport" BO_ 1049 1;
BA_ "GenMsgStartDelayTime" BO_ 1049 55;
BA_ "GenMsgCycleTime" BO_ 1049 100;
BA_ "GenMsgDelayTime" BO_ 1049 10;
BA_ "Type" BO_ 1454 3;
BA_ "GenMsgSendType" BO_ 1454 0;
BA_ "GenMsgNrOfRepetition" BO_ 1454 2;
BA_ "GenMsgILSupport" BO_ 1454 1;
BA_ "GenMsgStartDelayTime" BO_ 1454 760;
BA_ "GenMsgCycleTimeFast" BO_ 1454 10;
BA_ "GenMsgCycleTime" BO_ 1454 1000;
BA_ "GenMsgDelayTime" BO_ 1454 10;
BA_ "Type" BO_ 600 3;
BA_ "GenMsgSendType" BO_ 600 0;
BA_ "GenMsgNrOfRepetition" BO_ 600 2;
BA_ "GenMsgILSupport" BO_ 600 1;
BA_ "GenMsgCycleTimeFast" BO_ 600 10;
BA_ "GenMsgCycleTime" BO_ 600 100;
BA_ "GenMsgDelayTime" BO_ 600 10;
BA_ "Type" BO_ 1354 1;
BA_ "GenMsgSendType" BO_ 1354 0;
BA_ "GenMsgILSupport" BO_ 1354 1;
BA_ "GenMsgStartDelayTime" BO_ 1354 110;
BA_ "GenMsgCycleTime" BO_ 1354 250;
BA_ "Type" BO_ 1458 3;
BA_ "GenMsgSendType" BO_ 1458 0;
BA_ "GenMsgNrOfRepetition" BO_ 1458 2;
BA_ "GenMsgILSupport" BO_ 1458 1;
BA_ "GenMsgStartDelayTime" BO_ 1458 770;
BA_ "GenMsgCycleTimeFast" BO_ 1458 10;
BA_ "GenMsgCycleTime" BO_ 1458 1000;
BA_ "GenMsgDelayTime" BO_ 1458 10;
BA_ "Type" BO_ 1850 1;
BA_ "GenMsgSendType" BO_ 1850 0;
BA_ "GenMsgILSupport" BO_ 1850 1;
BA_ "GenMsgStartDelayTime" BO_ 1850 765;
BA_ "GenMsgCycleTime" BO_ 1850 1000;
BA_ "Type" BO_ 1000 9;
BA_ "GenMsgNrOfRepetition" BO_ 1000 3;
BA_ "GenMsgILSupport" BO_ 1000 1;
BA_ "GenMsgCycleTimeFast" BO_ 1000 500;
BA_ "Type" BO_ 246 1;
BA_ "GenMsgSendType" BO_ 246 0;
BA_ "GenMsgILSupport" BO_ 246 1;
BA_ "GenMsgStartDelayTime" BO_ 246 6;
BA_ "GenMsgCycleTime" BO_ 246 10;
BA_ "Type" BO_ 234 1;
BA_ "GenMsgSendType" BO_ 234 0;
BA_ "GenMsgILSupport" BO_ 234 1;
BA_ "GenMsgStartDelayTime" BO_ 234 2;
BA_ "GenMsgCycleTime" BO_ 234 10;
BA_ "Type" BO_ 278 1;
BA_ "GenMsgSendType" BO_ 278 0;
BA_ "GenMsgILSupport" BO_ 278 1;
BA_ "GenMsgCycleTime" BO_ 278 10;
BA_ "Type" BO_ 238 1;
BA_ "GenMsgSendType" BO_ 238 0;
BA_ "GenMsgILSupport" BO_ 238 1;
BA_ "GenMsgCycleTime" BO_ 238 10;
BA_ "GenSigTimeoutTime_BSM" SG_ 2654339098 CurrentFailSts_ORC 0;
BA_ "GenSigTimeoutTime_DIAG_TEST" SG_ 2654339098 CurrentFailSts_ORC 0;
BA_ "GenSigTimeoutTime_ECM" SG_ 2654339098 CurrentFailSts_ORC 0;
BA_ "GenSigTimeoutTime_EPS" SG_ 2654339098 CurrentFailSts_ORC 0;
BA_ "GenSigTimeoutTime_IPC" SG_ 2654339098 CurrentFailSts_ORC 0;
BA_ "GenSigTimeoutTime_MTA" SG_ 2654339098 CurrentFailSts_ORC 0;
BA_ "GenSigTimeoutTime_ORC" SG_ 2654339098 CurrentFailSts_ORC 0;
BA_ "GenSigTimeoutTime_PAM" SG_ 2654339098 CurrentFailSts_ORC 0;
BA_ "GenSigTimeoutTime_BCM" SG_ 2654339098 DES_ORC 0;
BA_ "GenSigTimeoutTime_BSM" SG_ 2654339098 DES_ORC 0;
BA_ "GenSigTimeoutTime_DIAG_TEST" SG_ 2654339098 DES_ORC 0;
BA_ "GenSigTimeoutTime_ECM" SG_ 2654339098 DES_ORC 0;
BA_ "GenSigTimeoutTime_EPS" SG_ 2654339098 DES_ORC 0;
BA_ "GenSigTimeoutTime_IPC" SG_ 2654339098 DES_ORC 0;
BA_ "GenSigTimeoutTime_MTA" SG_ 2654339098 DES_ORC 0;
BA_ "GenSigTimeoutTime_ORC" SG_ 2654339098 DES_ORC 0;
BA_ "GenSigTimeoutTime_PAM" SG_ 2654339098 DES_ORC 0;
BA_ "GenSigTimeoutTime_BSM" SG_ 2654339098 EOL_ORC 0;
BA_ "GenSigTimeoutTime_DIAG_TEST" SG_ 2654339098 EOL_ORC 0;
BA_ "GenSigTimeoutTime_ECM" SG_ 2654339098 EOL_ORC 0;
BA_ "GenSigTimeoutTime_EPS" SG_ 2654339098 EOL_ORC 0;
BA_ "GenSigTimeoutTime_IPC" SG_ 2654339098 EOL_ORC 0;
BA_ "GenSigTimeoutTime_MTA" SG_ 2654339098 EOL_ORC 0;
BA_ "GenSigTimeoutTime_ORC" SG_ 2654339098 EOL_ORC 0;
BA_ "GenSigTimeoutTime_PAM" SG_ 2654339098 EOL_ORC 0;
BA_ "GenSigTimeoutTime_BSM" SG_ 2654339098 GenericFailSts_ORC 0;
BA_ "GenSigTimeoutTime_DIAG_TEST" SG_ 2654339098 GenericFailSts_ORC 0;
BA_ "GenSigTimeoutTime_ECM" SG_ 2654339098 GenericFailSts_ORC 0;
BA_ "GenSigTimeoutTime_EPS" SG_ 2654339098 GenericFailSts_ORC 0;
BA_ "GenSigTimeoutTime_IPC" SG_ 2654339098 GenericFailSts_ORC 0;
BA_ "GenSigTimeoutTime_MTA" SG_ 2654339098 GenericFailSts_ORC 0;
BA_ "GenSigTimeoutTime_ORC" SG_ 2654339098 GenericFailSts_ORC 0;
BA_ "GenSigTimeoutTime_PAM" SG_ 2654339098 GenericFailSts_ORC 0;
BA_ "GenSigTimeoutTime_BCM" SG_ 2654339098 Reserved_for_PDC_ORC 0;
BA_ "GenSigTimeoutTime_BSM" SG_ 2654339098 Reserved_for_PDC_ORC 0;
BA_ "GenSigTimeoutTime_DIAG_TEST" SG_ 2654339098 Reserved_for_PDC_ORC 0;
BA_ "GenSigTimeoutTime_ECM" SG_ 2654339098 Reserved_for_PDC_ORC 0;
BA_ "GenSigTimeoutTime_EPS" SG_ 2654339098 Reserved_for_PDC_ORC 0;
BA_ "GenSigTimeoutTime_IPC" SG_ 2654339098 Reserved_for_PDC_ORC 0;
BA_ "GenSigTimeoutTime_MTA" SG_ 2654339098 Reserved_for_PDC_ORC 0;
BA_ "GenSigTimeoutTime_ORC" SG_ 2654339098 Reserved_for_PDC_ORC 0;
BA_ "GenSigTimeoutTime_PAM" SG_ 2654339098 Reserved_for_PDC_ORC 0;
BA_ "GenSigTimeoutTime_BCM" SG_ 2654339098 StayActiveSource_ORC_0 0;
BA_ "GenSigTimeoutTime_BSM" SG_ 2654339098 StayActiveSource_ORC_0 0;
BA_ "GenSigTimeoutTime_DIAG_TEST" SG_ 2654339098 StayActiveSource_ORC_0 0;
BA_ "GenSigTimeoutTime_ECM" SG_ 2654339098 StayActiveSource_ORC_0 0;
BA_ "GenSigTimeoutTime_EPS" SG_ 2654339098 StayActiveSource_ORC_0 0;
BA_ "GenSigTimeoutTime_IPC" SG_ 2654339098 StayActiveSource_ORC_0 0;
BA_ "GenSigTimeoutTime_MTA" SG_ 2654339098 StayActiveSource_ORC_0 0;
BA_ "GenSigTimeoutTime_ORC" SG_ 2654339098 StayActiveSource_ORC_0 0;
BA_ "GenSigTimeoutTime_PAM" SG_ 2654339098 StayActiveSource_ORC_0 0;
BA_ "GenSigTimeoutTime_BCM" SG_ 2654339098 StayActiveSource_ORC_1 0;
BA_ "GenSigTimeoutTime_BSM" SG_ 2654339098 StayActiveSource_ORC_1 0;
BA_ "GenSigTimeoutTime_DIAG_TEST" SG_ 2654339098 StayActiveSource_ORC_1 0;
BA_ "GenSigTimeoutTime_ECM" SG_ 2654339098 StayActiveSource_ORC_1 0;
BA_ "GenSigTimeoutTime_EPS" SG_ 2654339098 StayActiveSource_ORC_1 0;
BA_ "GenSigTimeoutTime_IPC" SG_ 2654339098 StayActiveSource_ORC_1 0;
BA_ "GenSigTimeoutTime_MTA" SG_ 2654339098 StayActiveSource_ORC_1 0;
BA_ "GenSigTimeoutTime_ORC" SG_ 2654339098 StayActiveSource_ORC_1 0;
BA_ "GenSigTimeoutTime_PAM" SG_ 2654339098 StayActiveSource_ORC_1 0;
BA_ "GenSigTimeoutTime_BCM" SG_ 2654339098 StayActiveSource_ORC_10 0;
BA_ "GenSigTimeoutTime_BSM" SG_ 2654339098 StayActiveSource_ORC_10 0;
BA_ "GenSigTimeoutTime_DIAG_TEST" SG_ 2654339098 StayActiveSource_ORC_10 0;
BA_ "GenSigTimeoutTime_ECM" SG_ 2654339098 StayActiveSource_ORC_10 0;
BA_ "GenSigTimeoutTime_EPS" SG_ 2654339098 StayActiveSource_ORC_10 0;
BA_ "GenSigTimeoutTime_IPC" SG_ 2654339098 StayActiveSource_ORC_10 0;
BA_ "GenSigTimeoutTime_MTA" SG_ 2654339098 StayActiveSource_ORC_10 0;
BA_ "GenSigTimeoutTime_ORC" SG_ 2654339098 StayActiveSource_ORC_10 0;
BA_ "GenSigTimeoutTime_PAM" SG_ 2654339098 StayActiveSource_ORC_10 0;
BA_ "GenSigTimeoutTime_BCM" SG_ 2654339098 StayActiveSource_ORC_11 0;
BA_ "GenSigTimeoutTime_BSM" SG_ 2654339098 StayActiveSource_ORC_11 0;
BA_ "GenSigTimeoutTime_DIAG_TEST" SG_ 2654339098 StayActiveSource_ORC_11 0;
BA_ "GenSigTimeoutTime_ECM" SG_ 2654339098 StayActiveSource_ORC_11 0;
BA_ "GenSigTimeoutTime_EPS" SG_ 2654339098 StayActiveSource_ORC_11 0;
BA_ "GenSigTimeoutTime_IPC" SG_ 2654339098 StayActiveSource_ORC_11 0;
BA_ "GenSigTimeoutTime_MTA" SG_ 2654339098 StayActiveSource_ORC_11 0;
BA_ "GenSigTimeoutTime_ORC" SG_ 2654339098 StayActiveSource_ORC_11 0;
BA_ "GenSigTimeoutTime_PAM" SG_ 2654339098 StayActiveSource_ORC_11 0;
BA_ "GenSigTimeoutTime_BCM" SG_ 2654339098 StayActiveSource_ORC_12 0;
BA_ "GenSigTimeoutTime_BSM" SG_ 2654339098 StayActiveSource_ORC_12 0;
BA_ "GenSigTimeoutTime_DIAG_TEST" SG_ 2654339098 StayActiveSource_ORC_12 0;
BA_ "GenSigTimeoutTime_ECM" SG_ 2654339098 StayActiveSource_ORC_12 0;
BA_ "GenSigTimeoutTime_EPS" SG_ 2654339098 StayActiveSource_ORC_12 0;
BA_ "GenSigTimeoutTime_IPC" SG_ 2654339098 StayActiveSource_ORC_12 0;
BA_ "GenSigTimeoutTime_MTA" SG_ 2654339098 StayActiveSource_ORC_12 0;
BA_ "GenSigTimeoutTime_ORC" SG_ 2654339098 StayActiveSource_ORC_12 0;
BA_ "GenSigTimeoutTime_PAM" SG_ 2654339098 StayActiveSource_ORC_12 0;
BA_ "GenSigTimeoutTime_BCM" SG_ 2654339098 StayActiveSource_ORC_13 0;
BA_ "GenSigTimeoutTime_BSM" SG_ 2654339098 StayActiveSource_ORC_13 0;
BA_ "GenSigTimeoutTime_DIAG_TEST" SG_ 2654339098 StayActiveSource_ORC_13 0;
BA_ "GenSigTimeoutTime_ECM" SG_ 2654339098 StayActiveSource_ORC_13 0;
BA_ "GenSigTimeoutTime_EPS" SG_ 2654339098 StayActiveSource_ORC_13 0;
BA_ "GenSigTimeoutTime_IPC" SG_ 2654339098 StayActiveSource_ORC_13 0;
BA_ "GenSigTimeoutTime_MTA" SG_ 2654339098 StayActiveSource_ORC_13 0;
BA_ "GenSigTimeoutTime_ORC" SG_ 2654339098 StayActiveSource_ORC_13 0;
BA_ "GenSigTimeoutTime_PAM" SG_ 2654339098 StayActiveSource_ORC_13 0;
BA_ "GenSigTimeoutTime_BCM" SG_ 2654339098 StayActiveSource_ORC_14 0;
BA_ "GenSigTimeoutTime_BSM" SG_ 2654339098 StayActiveSource_ORC_14 0;
BA_ "GenSigTimeoutTime_DIAG_TEST" SG_ 2654339098 StayActiveSource_ORC_14 0;
BA_ "GenSigTimeoutTime_ECM" SG_ 2654339098 StayActiveSource_ORC_14 0;
BA_ "GenSigTimeoutTime_EPS" SG_ 2654339098 StayActiveSource_ORC_14 0;
BA_ "GenSigTimeoutTime_IPC" SG_ 2654339098 StayActiveSource_ORC_14 0;
BA_ "GenSigTimeoutTime_MTA" SG_ 2654339098 StayActiveSource_ORC_14 0;
BA_ "GenSigTimeoutTime_ORC" SG_ 2654339098 StayActiveSource_ORC_14 0;
BA_ "GenSigTimeoutTime_PAM" SG_ 2654339098 StayActiveSource_ORC_14 0;
BA_ "GenSigTimeoutTime_BCM" SG_ 2654339098 StayActiveSource_ORC_15 0;
BA_ "GenSigTimeoutTime_BSM" SG_ 2654339098 StayActiveSource_ORC_15 0;
BA_ "GenSigTimeoutTime_DIAG_TEST" SG_ 2654339098 StayActiveSource_ORC_15 0;
BA_ "GenSigTimeoutTime_ECM" SG_ 2654339098 StayActiveSource_ORC_15 0;
BA_ "GenSigTimeoutTime_EPS" SG_ 2654339098 StayActiveSource_ORC_15 0;
BA_ "GenSigTimeoutTime_IPC" SG_ 2654339098 StayActiveSource_ORC_15 0;
BA_ "GenSigTimeoutTime_MTA" SG_ 2654339098 StayActiveSource_ORC_15 0;
BA_ "GenSigTimeoutTime_ORC" SG_ 2654339098 StayActiveSource_ORC_15 0;
BA_ "GenSigTimeoutTime_PAM" SG_ 2654339098 StayActiveSource_ORC_15 0;
BA_ "GenSigTimeoutTime_BCM" SG_ 2654339098 StayActiveSource_ORC_2 0;
BA_ "GenSigTimeoutTime_BSM" SG_ 2654339098 StayActiveSource_ORC_2 0;
BA_ "GenSigTimeoutTime_DIAG_TEST" SG_ 2654339098 StayActiveSource_ORC_2 0;
BA_ "GenSigTimeoutTime_ECM" SG_ 2654339098 StayActiveSource_ORC_2 0;
BA_ "GenSigTimeoutTime_EPS" SG_ 2654339098 StayActiveSource_ORC_2 0;
BA_ "GenSigTimeoutTime_IPC" SG_ 2654339098 StayActiveSource_ORC_2 0;
BA_ "GenSigTimeoutTime_MTA" SG_ 2654339098 StayActiveSource_ORC_2 0;
BA_ "GenSigTimeoutTime_ORC" SG_ 2654339098 StayActiveSource_ORC_2 0;
BA_ "GenSigTimeoutTime_PAM" SG_ 2654339098 StayActiveSource_ORC_2 0;
BA_ "GenSigTimeoutTime_BCM" SG_ 2654339098 StayActiveSource_ORC_3 0;
BA_ "GenSigTimeoutTime_BSM" SG_ 2654339098 StayActiveSource_ORC_3 0;
BA_ "GenSigTimeoutTime_DIAG_TEST" SG_ 2654339098 StayActiveSource_ORC_3 0;
BA_ "GenSigTimeoutTime_ECM" SG_ 2654339098 StayActiveSource_ORC_3 0;
BA_ "GenSigTimeoutTime_EPS" SG_ 2654339098 StayActiveSource_ORC_3 0;
BA_ "GenSigTimeoutTime_IPC" SG_ 2654339098 StayActiveSource_ORC_3 0;
BA_ "GenSigTimeoutTime_MTA" SG_ 2654339098 StayActiveSource_ORC_3 0;
BA_ "GenSigTimeoutTime_ORC" SG_ 2654339098 StayActiveSource_ORC_3 0;
BA_ "GenSigTimeoutTime_PAM" SG_ 2654339098 StayActiveSource_ORC_3 0;
BA_ "GenSigTimeoutTime_BCM" SG_ 2654339098 StayActiveSource_ORC_4 0;
BA_ "GenSigTimeoutTime_BSM" SG_ 2654339098 StayActiveSource_ORC_4 0;
BA_ "GenSigTimeoutTime_DIAG_TEST" SG_ 2654339098 StayActiveSource_ORC_4 0;
BA_ "GenSigTimeoutTime_ECM" SG_ 2654339098 StayActiveSource_ORC_4 0;
BA_ "GenSigTimeoutTime_EPS" SG_ 2654339098 StayActiveSource_ORC_4 0;
BA_ "GenSigTimeoutTime_IPC" SG_ 2654339098 StayActiveSource_ORC_4 0;
BA_ "GenSigTimeoutTime_MTA" SG_ 2654339098 StayActiveSource_ORC_4 0;
BA_ "GenSigTimeoutTime_ORC" SG_ 2654339098 StayActiveSource_ORC_4 0;
BA_ "GenSigTimeoutTime_PAM" SG_ 2654339098 StayActiveSource_ORC_4 0;
BA_ "GenSigTimeoutTime_BCM" SG_ 2654339098 StayActiveSource_ORC_5 0;
BA_ "GenSigTimeoutTime_BSM" SG_ 2654339098 StayActiveSource_ORC_5 0;
BA_ "GenSigTimeoutTime_DIAG_TEST" SG_ 2654339098 StayActiveSource_ORC_5 0;
BA_ "GenSigTimeoutTime_ECM" SG_ 2654339098 StayActiveSource_ORC_5 0;
BA_ "GenSigTimeoutTime_EPS" SG_ 2654339098 StayActiveSource_ORC_5 0;
BA_ "GenSigTimeoutTime_IPC" SG_ 2654339098 StayActiveSource_ORC_5 0;
BA_ "GenSigTimeoutTime_MTA" SG_ 2654339098 StayActiveSource_ORC_5 0;
BA_ "GenSigTimeoutTime_ORC" SG_ 2654339098 StayActiveSource_ORC_5 0;
BA_ "GenSigTimeoutTime_PAM" SG_ 2654339098 StayActiveSource_ORC_5 0;
BA_ "GenSigTimeoutTime_BCM" SG_ 2654339098 StayActiveSource_ORC_6 0;
BA_ "GenSigTimeoutTime_BSM" SG_ 2654339098 StayActiveSource_ORC_6 0;
BA_ "GenSigTimeoutTime_DIAG_TEST" SG_ 2654339098 StayActiveSource_ORC_6 0;
BA_ "GenSigTimeoutTime_ECM" SG_ 2654339098 StayActiveSource_ORC_6 0;
BA_ "GenSigTimeoutTime_EPS" SG_ 2654339098 StayActiveSource_ORC_6 0;
BA_ "GenSigTimeoutTime_IPC" SG_ 2654339098 StayActiveSource_ORC_6 0;
BA_ "GenSigTimeoutTime_MTA" SG_ 2654339098 StayActiveSource_ORC_6 0;
BA_ "GenSigTimeoutTime_ORC" SG_ 2654339098 StayActiveSource_ORC_6 0;
BA_ "GenSigTimeoutTime_PAM" SG_ 2654339098 StayActiveSource_ORC_6 0;
BA_ "GenSigTimeoutTime_BCM" SG_ 2654339098 StayActiveSource_ORC_7 0;
BA_ "GenSigTimeoutTime_BSM" SG_ 2654339098 StayActiveSource_ORC_7 0;
BA_ "GenSigTimeoutTime_DIAG_TEST" SG_ 2654339098 StayActiveSource_ORC_7 0;
BA_ "GenSigTimeoutTime_ECM" SG_ 2654339098 StayActiveSource_ORC_7 0;
BA_ "GenSigTimeoutTime_EPS" SG_ 2654339098 StayActiveSource_ORC_7 0;
BA_ "GenSigTimeoutTime_IPC" SG_ 2654339098 StayActiveSource_ORC_7 0;
BA_ "GenSigTimeoutTime_MTA" SG_ 2654339098 StayActiveSource_ORC_7 0;
BA_ "GenSigTimeoutTime_ORC" SG_ 2654339098 StayActiveSource_ORC_7 0;
BA_ "GenSigTimeoutTime_PAM" SG_ 2654339098 StayActiveSource_ORC_7 0;
BA_ "GenSigTimeoutTime_BCM" SG_ 2654339098 StayActiveSource_ORC_8 0;
BA_ "GenSigTimeoutTime_BSM" SG_ 2654339098 StayActiveSource_ORC_8 0;
BA_ "GenSigTimeoutTime_DIAG_TEST" SG_ 2654339098 StayActiveSource_ORC_8 0;
BA_ "GenSigTimeoutTime_ECM" SG_ 2654339098 StayActiveSource_ORC_8 0;
BA_ "GenSigTimeoutTime_EPS" SG_ 2654339098 StayActiveSource_ORC_8 0;
BA_ "GenSigTimeoutTime_IPC" SG_ 2654339098 StayActiveSource_ORC_8 0;
BA_ "GenSigTimeoutTime_MTA" SG_ 2654339098 StayActiveSource_ORC_8 0;
BA_ "GenSigTimeoutTime_ORC" SG_ 2654339098 StayActiveSource_ORC_8 0;
BA_ "GenSigTimeoutTime_PAM" SG_ 2654339098 StayActiveSource_ORC_8 0;
BA_ "GenSigTimeoutTime_BCM" SG_ 2654339098 StayActiveSource_ORC_9 0;
BA_ "GenSigTimeoutTime_BSM" SG_ 2654339098 StayActiveSource_ORC_9 0;
BA_ "GenSigTimeoutTime_DIAG_TEST" SG_ 2654339098 StayActiveSource_ORC_9 0;
BA_ "GenSigTimeoutTime_ECM" SG_ 2654339098 StayActiveSource_ORC_9 0;
BA_ "GenSigTimeoutTime_EPS" SG_ 2654339098 StayActiveSource_ORC_9 0;
BA_ "GenSigTimeoutTime_IPC" SG_ 2654339098 StayActiveSource_ORC_9 0;
BA_ "GenSigTimeoutTime_MTA" SG_ 2654339098 StayActiveSource_ORC_9 0;
BA_ "GenSigTimeoutTime_ORC" SG_ 2654339098 StayActiveSource_ORC_9 0;
BA_ "GenSigTimeoutTime_PAM" SG_ 2654339098 StayActiveSource_ORC_9 0;
BA_ "GenSigTimeoutTime_BSM" SG_ 2654339096 CurrentFailSts_PAM 0;
BA_ "GenSigTimeoutTime_DIAG_TEST" SG_ 2654339096 CurrentFailSts_PAM 0;
BA_ "GenSigTimeoutTime_ECM" SG_ 2654339096 CurrentFailSts_PAM 0;
BA_ "GenSigTimeoutTime_EPS" SG_ 2654339096 CurrentFailSts_PAM 0;
BA_ "GenSigTimeoutTime_IPC" SG_ 2654339096 CurrentFailSts_PAM 0;
BA_ "GenSigTimeoutTime_MTA" SG_ 2654339096 CurrentFailSts_PAM 0;
BA_ "GenSigTimeoutTime_ORC" SG_ 2654339096 CurrentFailSts_PAM 0;
BA_ "GenSigTimeoutTime_PAM" SG_ 2654339096 CurrentFailSts_PAM 0;
BA_ "GenSigTimeoutTime_BCM" SG_ 2654339096 DES_PAM 0;
BA_ "GenSigTimeoutTime_BSM" SG_ 2654339096 DES_PAM 0;
BA_ "GenSigTimeoutTime_DIAG_TEST" SG_ 2654339096 DES_PAM 0;
BA_ "GenSigTimeoutTime_ECM" SG_ 2654339096 DES_PAM 0;
BA_ "GenSigTimeoutTime_EPS" SG_ 2654339096 DES_PAM 0;
BA_ "GenSigTimeoutTime_IPC" SG_ 2654339096 DES_PAM 0;
BA_ "GenSigTimeoutTime_MTA" SG_ 2654339096 DES_PAM 0;
BA_ "GenSigTimeoutTime_ORC" SG_ 2654339096 DES_PAM 0;
BA_ "GenSigTimeoutTime_PAM" SG_ 2654339096 DES_PAM 0;
BA_ "GenSigTimeoutTime_BSM" SG_ 2654339096 EOL_PAM 0;
BA_ "GenSigTimeoutTime_DIAG_TEST" SG_ 2654339096 EOL_PAM 0;
BA_ "GenSigTimeoutTime_ECM" SG_ 2654339096 EOL_PAM 0;
BA_ "GenSigTimeoutTime_EPS" SG_ 2654339096 EOL_PAM 0;
BA_ "GenSigTimeoutTime_IPC" SG_ 2654339096 EOL_PAM 0;
BA_ "GenSigTimeoutTime_MTA" SG_ 2654339096 EOL_PAM 0;
BA_ "GenSigTimeoutTime_ORC" SG_ 2654339096 EOL_PAM 0;
BA_ "GenSigTimeoutTime_PAM" SG_ 2654339096 EOL_PAM 0;
BA_ "GenSigTimeoutTime_BSM" SG_ 2654339096 GenericFailSts_PAM 0;
BA_ "GenSigTimeoutTime_DIAG_TEST" SG_ 2654339096 GenericFailSts_PAM 0;
BA_ "GenSigTimeoutTime_ECM" SG_ 2654339096 GenericFailSts_PAM 0;
BA_ "GenSigTimeoutTime_EPS" SG_ 2654339096 GenericFailSts_PAM 0;
BA_ "GenSigTimeoutTime_IPC" SG_ 2654339096 GenericFailSts_PAM 0;
BA_ "GenSigTimeoutTime_MTA" SG_ 2654339096 GenericFailSts_PAM 0;
BA_ "GenSigTimeoutTime_ORC" SG_ 2654339096 GenericFailSts_PAM 0;
BA_ "GenSigTimeoutTime_PAM" SG_ 2654339096 GenericFailSts_PAM 0;
BA_ "GenSigTimeoutTime_BCM" SG_ 2654339096 Reserved_for_PDC_PAM 0;
BA_ "GenSigTimeoutTime_BSM" SG_ 2654339096 Reserved_for_PDC_PAM 0;
BA_ "GenSigTimeoutTime_DIAG_TEST" SG_ 2654339096 Reserved_for_PDC_PAM 0;
BA_ "GenSigTimeoutTime_ECM" SG_ 2654339096 Reserved_for_PDC_PAM 0;
BA_ "GenSigTimeoutTime_EPS" SG_ 2654339096 Reserved_for_PDC_PAM 0;
BA_ "GenSigTimeoutTime_IPC" SG_ 2654339096 Reserved_for_PDC_PAM 0;
BA_ "GenSigTimeoutTime_MTA" SG_ 2654339096 Reserved_for_PDC_PAM 0;
BA_ "GenSigTimeoutTime_ORC" SG_ 2654339096 Reserved_for_PDC_PAM 0;
BA_ "GenSigTimeoutTime_PAM" SG_ 2654339096 Reserved_for_PDC_PAM 0;
BA_ "GenSigTimeoutTime_BCM" SG_ 2654339096 StayActiveSource_PAM_0 0;
BA_ "GenSigTimeoutTime_BSM" SG_ 2654339096 StayActiveSource_PAM_0 0;
BA_ "GenSigTimeoutTime_DIAG_TEST" SG_ 2654339096 StayActiveSource_PAM_0 0;
BA_ "GenSigTimeoutTime_ECM" SG_ 2654339096 StayActiveSource_PAM_0 0;
BA_ "GenSigTimeoutTime_EPS" SG_ 2654339096 StayActiveSource_PAM_0 0;
BA_ "GenSigTimeoutTime_IPC" SG_ 2654339096 StayActiveSource_PAM_0 0;
BA_ "GenSigTimeoutTime_MTA" SG_ 2654339096 StayActiveSource_PAM_0 0;
BA_ "GenSigTimeoutTime_ORC" SG_ 2654339096 StayActiveSource_PAM_0 0;
BA_ "GenSigTimeoutTime_PAM" SG_ 2654339096 StayActiveSource_PAM_0 0;
BA_ "GenSigTimeoutTime_BCM" SG_ 2654339096 StayActiveSource_PAM_1 0;
BA_ "GenSigTimeoutTime_BSM" SG_ 2654339096 StayActiveSource_PAM_1 0;
BA_ "GenSigTimeoutTime_DIAG_TEST" SG_ 2654339096 StayActiveSource_PAM_1 0;
BA_ "GenSigTimeoutTime_ECM" SG_ 2654339096 StayActiveSource_PAM_1 0;
BA_ "GenSigTimeoutTime_EPS" SG_ 2654339096 StayActiveSource_PAM_1 0;
BA_ "GenSigTimeoutTime_IPC" SG_ 2654339096 StayActiveSource_PAM_1 0;
BA_ "GenSigTimeoutTime_MTA" SG_ 2654339096 StayActiveSource_PAM_1 0;
BA_ "GenSigTimeoutTime_ORC" SG_ 2654339096 StayActiveSource_PAM_1 0;
BA_ "GenSigTimeoutTime_PAM" SG_ 2654339096 StayActiveSource_PAM_1 0;
BA_ "GenSigTimeoutTime_BCM" SG_ 2654339096 StayActiveSource_PAM_10 0;
BA_ "GenSigTimeoutTime_BSM" SG_ 2654339096 StayActiveSource_PAM_10 0;
BA_ "GenSigTimeoutTime_DIAG_TEST" SG_ 2654339096 StayActiveSource_PAM_10 0;
BA_ "GenSigTimeoutTime_ECM" SG_ 2654339096 StayActiveSource_PAM_10 0;
BA_ "GenSigTimeoutTime_EPS" SG_ 2654339096 StayActiveSource_PAM_10 0;
BA_ "GenSigTimeoutTime_IPC" SG_ 2654339096 StayActiveSource_PAM_10 0;
BA_ "GenSigTimeoutTime_MTA" SG_ 2654339096 StayActiveSource_PAM_10 0;
BA_ "GenSigTimeoutTime_ORC" SG_ 2654339096 StayActiveSource_PAM_10 0;
BA_ "GenSigTimeoutTime_PAM" SG_ 2654339096 StayActiveSource_PAM_10 0;
BA_ "GenSigTimeoutTime_BCM" SG_ 2654339096 StayActiveSource_PAM_11 0;
BA_ "GenSigTimeoutTime_BSM" SG_ 2654339096 StayActiveSource_PAM_11 0;
BA_ "GenSigTimeoutTime_DIAG_TEST" SG_ 2654339096 StayActiveSource_PAM_11 0;
BA_ "GenSigTimeoutTime_ECM" SG_ 2654339096 StayActiveSource_PAM_11 0;
BA_ "GenSigTimeoutTime_EPS" SG_ 2654339096 StayActiveSource_PAM_11 0;
BA_ "GenSigTimeoutTime_IPC" SG_ 2654339096 StayActiveSource_PAM_11 0;
BA_ "GenSigTimeoutTime_MTA" SG_ 2654339096 StayActiveSource_PAM_11 0;
BA_ "GenSigTimeoutTime_ORC" SG_ 2654339096 StayActiveSource_PAM_11 0;
BA_ "GenSigTimeoutTime_PAM" SG_ 2654339096 StayActiveSource_PAM_11 0;
BA_ "GenSigTimeoutTime_BCM" SG_ 2654339096 StayActiveSource_PAM_12 0;
BA_ "GenSigTimeoutTime_BSM" SG_ 2654339096 StayActiveSource_PAM_12 0;
BA_ "GenSigTimeoutTime_DIAG_TEST" SG_ 2654339096 StayActiveSource_PAM_12 0;
BA_ "GenSigTimeoutTime_ECM" SG_ 2654339096 StayActiveSource_PAM_12 0;
BA_ "GenSigTimeoutTime_EPS" SG_ 2654339096 StayActiveSource_PAM_12 0;
BA_ "GenSigTimeoutTime_IPC" SG_ 2654339096 StayActiveSource_PAM_12 0;
BA_ "GenSigTimeoutTime_MTA" SG_ 2654339096 StayActiveSource_PAM_12 0;
BA_ "GenSigTimeoutTime_ORC" SG_ 2654339096 StayActiveSource_PAM_12 0;
BA_ "GenSigTimeoutTime_PAM" SG_ 2654339096 StayActiveSource_PAM_12 0;
BA_ "GenSigTimeoutTime_BCM" SG_ 2654339096 StayActiveSource_PAM_13 0;
BA_ "GenSigTimeoutTime_BSM" SG_ 2654339096 StayActiveSource_PAM_13 0;
BA_ "GenSigTimeoutTime_DIAG_TEST" SG_ 2654339096 StayActiveSource_PAM_13 0;
BA_ "GenSigTimeoutTime_ECM" SG_ 2654339096 StayActiveSource_PAM_13 0;
BA_ "GenSigTimeoutTime_EPS" SG_ 2654339096 StayActiveSource_PAM_13 0;
BA_ "GenSigTimeoutTime_IPC" SG_ 2654339096 StayActiveSource_PAM_13 0;
BA_ "GenSigTimeoutTime_MTA" SG_ 2654339096 StayActiveSource_PAM_13 0;
BA_ "GenSigTimeoutTime_ORC" SG_ 2654339096 StayActiveSource_PAM_13 0;
BA_ "GenSigTimeoutTime_PAM" SG_ 2654339096 StayActiveSource_PAM_13 0;
BA_ "GenSigTimeoutTime_BCM" SG_ 2654339096 StayActiveSource_PAM_14 0;
BA_ "GenSigTimeoutTime_BSM" SG_ 2654339096 StayActiveSource_PAM_14 0;
BA_ "GenSigTimeoutTime_DIAG_TEST" SG_ 2654339096 StayActiveSource_PAM_14 0;
BA_ "GenSigTimeoutTime_ECM" SG_ 2654339096 StayActiveSource_PAM_14 0;
BA_ "GenSigTimeoutTime_EPS" SG_ 2654339096 StayActiveSource_PAM_14 0;
BA_ "GenSigTimeoutTime_IPC" SG_ 2654339096 StayActiveSource_PAM_14 0;
BA_ "GenSigTimeoutTime_MTA" SG_ 2654339096 StayActiveSource_PAM_14 0;
BA_ "GenSigTimeoutTime_ORC" SG_ 2654339096 StayActiveSource_PAM_14 0;
BA_ "GenSigTimeoutTime_PAM" SG_ 2654339096 StayActiveSource_PAM_14 0;
BA_ "GenSigTimeoutTime_BCM" SG_ 2654339096 StayActiveSource_PAM_15 0;
BA_ "GenSigTimeoutTime_BSM" SG_ 2654339096 StayActiveSource_PAM_15 0;
BA_ "GenSigTimeoutTime_DIAG_TEST" SG_ 2654339096 StayActiveSource_PAM_15 0;
BA_ "GenSigTimeoutTime_ECM" SG_ 2654339096 StayActiveSource_PAM_15 0;
BA_ "GenSigTimeoutTime_EPS" SG_ 2654339096 StayActiveSource_PAM_15 0;
BA_ "GenSigTimeoutTime_IPC" SG_ 2654339096 StayActiveSource_PAM_15 0;
BA_ "GenSigTimeoutTime_MTA" SG_ 2654339096 StayActiveSource_PAM_15 0;
BA_ "GenSigTimeoutTime_ORC" SG_ 2654339096 StayActiveSource_PAM_15 0;
BA_ "GenSigTimeoutTime_PAM" SG_ 2654339096 StayActiveSource_PAM_15 0;
BA_ "GenSigTimeoutTime_BCM" SG_ 2654339096 StayActiveSource_PAM_2 0;
BA_ "GenSigTimeoutTime_BSM" SG_ 2654339096 StayActiveSource_PAM_2 0;
BA_ "GenSigTimeoutTime_DIAG_TEST" SG_ 2654339096 StayActiveSource_PAM_2 0;
BA_ "GenSigTimeoutTime_ECM" SG_ 2654339096 StayActiveSource_PAM_2 0;
BA_ "GenSigTimeoutTime_EPS" SG_ 2654339096 StayActiveSource_PAM_2 0;
BA_ "GenSigTimeoutTime_IPC" SG_ 2654339096 StayActiveSource_PAM_2 0;
BA_ "GenSigTimeoutTime_MTA" SG_ 2654339096 StayActiveSource_PAM_2 0;
BA_ "GenSigTimeoutTime_ORC" SG_ 2654339096 StayActiveSource_PAM_2 0;
BA_ "GenSigTimeoutTime_PAM" SG_ 2654339096 StayActiveSource_PAM_2 0;
BA_ "GenSigTimeoutTime_BCM" SG_ 2654339096 StayActiveSource_PAM_3 0;
BA_ "GenSigTimeoutTime_BSM" SG_ 2654339096 StayActiveSource_PAM_3 0;
BA_ "GenSigTimeoutTime_DIAG_TEST" SG_ 2654339096 StayActiveSource_PAM_3 0;
BA_ "GenSigTimeoutTime_ECM" SG_ 2654339096 StayActiveSource_PAM_3 0;
BA_ "GenSigTimeoutTime_EPS" SG_ 2654339096 StayActiveSource_PAM_3 0;
BA_ "GenSigTimeoutTime_IPC" SG_ 2654339096 StayActiveSource_PAM_3 0;
BA_ "GenSigTimeoutTime_MTA" SG_ 2654339096 StayActiveSource_PAM_3 0;
BA_ "GenSigTimeoutTime_ORC" SG_ 2654339096 StayActiveSource_PAM_3 0;
BA_ "GenSigTimeoutTime_PAM" SG_ 2654339096 StayActiveSource_PAM_3 0;
BA_ "GenSigTimeoutTime_BCM" SG_ 2654339096 StayActiveSource_PAM_4 0;
BA_ "GenSigTimeoutTime_BSM" SG_ 2654339096 StayActiveSource_PAM_4 0;
BA_ "GenSigTimeoutTime_DIAG_TEST" SG_ 2654339096 StayActiveSource_PAM_4 0;
BA_ "GenSigTimeoutTime_ECM" SG_ 2654339096 StayActiveSource_PAM_4 0;
BA_ "GenSigTimeoutTime_EPS" SG_ 2654339096 StayActiveSource_PAM_4 0;
BA_ "GenSigTimeoutTime_IPC" SG_ 2654339096 StayActiveSource_PAM_4 0;
BA_ "GenSigTimeoutTime_MTA" SG_ 2654339096 StayActiveSource_PAM_4 0;
BA_ "GenSigTimeoutTime_ORC" SG_ 2654339096 StayActiveSource_PAM_4 0;
BA_ "GenSigTimeoutTime_PAM" SG_ 2654339096 StayActiveSource_PAM_4 0;
BA_ "GenSigTimeoutTime_BCM" SG_ 2654339096 StayActiveSource_PAM_5 0;
BA_ "GenSigTimeoutTime_BSM" SG_ 2654339096 StayActiveSource_PAM_5 0;
BA_ "GenSigTimeoutTime_DIAG_TEST" SG_ 2654339096 StayActiveSource_PAM_5 0;
BA_ "GenSigTimeoutTime_ECM" SG_ 2654339096 StayActiveSource_PAM_5 0;
BA_ "GenSigTimeoutTime_EPS" SG_ 2654339096 StayActiveSource_PAM_5 0;
BA_ "GenSigTimeoutTime_IPC" SG_ 2654339096 StayActiveSource_PAM_5 0;
BA_ "GenSigTimeoutTime_MTA" SG_ 2654339096 StayActiveSource_PAM_5 0;
BA_ "GenSigTimeoutTime_ORC" SG_ 2654339096 StayActiveSource_PAM_5 0;
BA_ "GenSigTimeoutTime_PAM" SG_ 2654339096 StayActiveSource_PAM_5 0;
BA_ "GenSigTimeoutTime_BCM" SG_ 2654339096 StayActiveSource_PAM_6 0;
BA_ "GenSigTimeoutTime_BSM" SG_ 2654339096 StayActiveSource_PAM_6 0;
BA_ "GenSigTimeoutTime_DIAG_TEST" SG_ 2654339096 StayActiveSource_PAM_6 0;
BA_ "GenSigTimeoutTime_ECM" SG_ 2654339096 StayActiveSource_PAM_6 0;
BA_ "GenSigTimeoutTime_EPS" SG_ 2654339096 StayActiveSource_PAM_6 0;
BA_ "GenSigTimeoutTime_IPC" SG_ 2654339096 StayActiveSource_PAM_6 0;
BA_ "GenSigTimeoutTime_MTA" SG_ 2654339096 StayActiveSource_PAM_6 0;
BA_ "GenSigTimeoutTime_ORC" SG_ 2654339096 StayActiveSource_PAM_6 0;
BA_ "GenSigTimeoutTime_PAM" SG_ 2654339096 StayActiveSource_PAM_6 0;
BA_ "GenSigTimeoutTime_BCM" SG_ 2654339096 StayActiveSource_PAM_7 0;
BA_ "GenSigTimeoutTime_BSM" SG_ 2654339096 StayActiveSource_PAM_7 0;
BA_ "GenSigTimeoutTime_DIAG_TEST" SG_ 2654339096 StayActiveSource_PAM_7 0;
BA_ "GenSigTimeoutTime_ECM" SG_ 2654339096 StayActiveSource_PAM_7 0;
BA_ "GenSigTimeoutTime_EPS" SG_ 2654339096 StayActiveSource_PAM_7 0;
BA_ "GenSigTimeoutTime_IPC" SG_ 2654339096 StayActiveSource_PAM_7 0;
BA_ "GenSigTimeoutTime_MTA" SG_ 2654339096 StayActiveSource_PAM_7 0;
BA_ "GenSigTimeoutTime_ORC" SG_ 2654339096 StayActiveSource_PAM_7 0;
BA_ "GenSigTimeoutTime_PAM" SG_ 2654339096 StayActiveSource_PAM_7 0;
BA_ "GenSigTimeoutTime_BCM" SG_ 2654339096 StayActiveSource_PAM_8 0;
BA_ "GenSigTimeoutTime_BSM" SG_ 2654339096 StayActiveSource_PAM_8 0;
BA_ "GenSigTimeoutTime_DIAG_TEST" SG_ 2654339096 StayActiveSource_PAM_8 0;
BA_ "GenSigTimeoutTime_ECM" SG_ 2654339096 StayActiveSource_PAM_8 0;
BA_ "GenSigTimeoutTime_EPS" SG_ 2654339096 StayActiveSource_PAM_8 0;
BA_ "GenSigTimeoutTime_IPC" SG_ 2654339096 StayActiveSource_PAM_8 0;
BA_ "GenSigTimeoutTime_MTA" SG_ 2654339096 StayActiveSource_PAM_8 0;
BA_ "GenSigTimeoutTime_ORC" SG_ 2654339096 StayActiveSource_PAM_8 0;
BA_ "GenSigTimeoutTime_PAM" SG_ 2654339096 StayActiveSource_PAM_8 0;
BA_ "GenSigTimeoutTime_BCM" SG_ 2654339096 StayActiveSource_PAM_9 0;
BA_ "GenSigTimeoutTime_BSM" SG_ 2654339096 StayActiveSource_PAM_9 0;
BA_ "GenSigTimeoutTime_DIAG_TEST" SG_ 2654339096 StayActiveSource_PAM_9 0;
BA_ "GenSigTimeoutTime_ECM" SG_ 2654339096 StayActiveSource_PAM_9 0;
BA_ "GenSigTimeoutTime_EPS" SG_ 2654339096 StayActiveSource_PAM_9 0;
BA_ "GenSigTimeoutTime_IPC" SG_ 2654339096 StayActiveSource_PAM_9 0;
BA_ "GenSigTimeoutTime_MTA" SG_ 2654339096 StayActiveSource_PAM_9 0;
BA_ "GenSigTimeoutTime_ORC" SG_ 2654339096 StayActiveSource_PAM_9 0;
BA_ "GenSigTimeoutTime_PAM" SG_ 2654339096 StayActiveSource_PAM_9 0;
BA_ "GenSigTimeoutTime_BSM" SG_ 2654339083 CurrentFailSts_TRANSM 0;
BA_ "GenSigTimeoutTime_DIAG_TEST" SG_ 2654339083 CurrentFailSts_TRANSM 0;
BA_ "GenSigTimeoutTime_ECM" SG_ 2654339083 CurrentFailSts_TRANSM 0;
BA_ "GenSigTimeoutTime_EPS" SG_ 2654339083 CurrentFailSts_TRANSM 0;
BA_ "GenSigTimeoutTime_IPC" SG_ 2654339083 CurrentFailSts_TRANSM 0;
BA_ "GenSigTimeoutTime_MTA" SG_ 2654339083 CurrentFailSts_TRANSM 0;
BA_ "GenSigTimeoutTime_ORC" SG_ 2654339083 CurrentFailSts_TRANSM 0;
BA_ "GenSigTimeoutTime_PAM" SG_ 2654339083 CurrentFailSts_TRANSM 0;
BA_ "GenSigTimeoutTime_BCM" SG_ 2654339083 DES_TRANSM 0;
BA_ "GenSigTimeoutTime_BSM" SG_ 2654339083 DES_TRANSM 0;
BA_ "GenSigTimeoutTime_DIAG_TEST" SG_ 2654339083 DES_TRANSM 0;
BA_ "GenSigTimeoutTime_ECM" SG_ 2654339083 DES_TRANSM 0;
BA_ "GenSigTimeoutTime_EPS" SG_ 2654339083 DES_TRANSM 0;
BA_ "GenSigTimeoutTime_IPC" SG_ 2654339083 DES_TRANSM 0;
BA_ "GenSigTimeoutTime_MTA" SG_ 2654339083 DES_TRANSM 0;
BA_ "GenSigTimeoutTime_ORC" SG_ 2654339083 DES_TRANSM 0;
BA_ "GenSigTimeoutTime_PAM" SG_ 2654339083 DES_TRANSM 0;
BA_ "GenSigTimeoutTime_BSM" SG_ 2654339083 EOL_TRANSM 0;
BA_ "GenSigTimeoutTime_DIAG_TEST" SG_ 2654339083 EOL_TRANSM 0;
BA_ "GenSigTimeoutTime_ECM" SG_ 2654339083 EOL_TRANSM 0;
BA_ "GenSigTimeoutTime_EPS" SG_ 2654339083 EOL_TRANSM 0;
BA_ "GenSigTimeoutTime_IPC" SG_ 2654339083 EOL_TRANSM 0;
BA_ "GenSigTimeoutTime_MTA" SG_ 2654339083 EOL_TRANSM 0;
BA_ "GenSigTimeoutTime_ORC" SG_ 2654339083 EOL_TRANSM 0;
BA_ "GenSigTimeoutTime_PAM" SG_ 2654339083 EOL_TRANSM 0;
BA_ "GenSigTimeoutTime_BSM" SG_ 2654339083 GenericFailSts_TRANSM 0;
BA_ "GenSigTimeoutTime_DIAG_TEST" SG_ 2654339083 GenericFailSts_TRANSM 0;
BA_ "GenSigTimeoutTime_ECM" SG_ 2654339083 GenericFailSts_TRANSM 0;
BA_ "GenSigTimeoutTime_EPS" SG_ 2654339083 GenericFailSts_TRANSM 0;
BA_ "GenSigTimeoutTime_IPC" SG_ 2654339083 GenericFailSts_TRANSM 0;
BA_ "GenSigTimeoutTime_MTA" SG_ 2654339083 GenericFailSts_TRANSM 0;
BA_ "GenSigTimeoutTime_ORC" SG_ 2654339083 GenericFailSts_TRANSM 0;
BA_ "GenSigTimeoutTime_PAM" SG_ 2654339083 GenericFailSts_TRANSM 0;
BA_ "GenSigTimeoutTime_BCM" SG_ 2654339083 Reserved_for_PDC_TRANSM 0;
BA_ "GenSigTimeoutTime_BSM" SG_ 2654339083 Reserved_for_PDC_TRANSM 0;
BA_ "GenSigTimeoutTime_DIAG_TEST" SG_ 2654339083 Reserved_for_PDC_TRANSM 0;
BA_ "GenSigTimeoutTime_ECM" SG_ 2654339083 Reserved_for_PDC_TRANSM 0;
BA_ "GenSigTimeoutTime_EPS" SG_ 2654339083 Reserved_for_PDC_TRANSM 0;
BA_ "GenSigTimeoutTime_IPC" SG_ 2654339083 Reserved_for_PDC_TRANSM 0;
BA_ "GenSigTimeoutTime_MTA" SG_ 2654339083 Reserved_for_PDC_TRANSM 0;
BA_ "GenSigTimeoutTime_ORC" SG_ 2654339083 Reserved_for_PDC_TRANSM 0;
BA_ "GenSigTimeoutTime_PAM" SG_ 2654339083 Reserved_for_PDC_TRANSM 0;
BA_ "GenSigTimeoutTime_BCM" SG_ 2654339083 StayActiveSource_TRANSM_0 0;
BA_ "GenSigTimeoutTime_BSM" SG_ 2654339083 StayActiveSource_TRANSM_0 0;
BA_ "GenSigTimeoutTime_DIAG_TEST" SG_ 2654339083 StayActiveSource_TRANSM_0 0;
BA_ "GenSigTimeoutTime_ECM" SG_ 2654339083 StayActiveSource_TRANSM_0 0;
BA_ "GenSigTimeoutTime_EPS" SG_ 2654339083 StayActiveSource_TRANSM_0 0;
BA_ "GenSigTimeoutTime_IPC" SG_ 2654339083 StayActiveSource_TRANSM_0 0;
BA_ "GenSigTimeoutTime_MTA" SG_ 2654339083 StayActiveSource_TRANSM_0 0;
BA_ "GenSigTimeoutTime_ORC" SG_ 2654339083 StayActiveSource_TRANSM_0 0;
BA_ "GenSigTimeoutTime_PAM" SG_ 2654339083 StayActiveSource_TRANSM_0 0;
BA_ "GenSigTimeoutTime_BCM" SG_ 2654339083 StayActiveSource_TRANSM_1 0;
BA_ "GenSigTimeoutTime_BSM" SG_ 2654339083 StayActiveSource_TRANSM_1 0;
BA_ "GenSigTimeoutTime_DIAG_TEST" SG_ 2654339083 StayActiveSource_TRANSM_1 0;
BA_ "GenSigTimeoutTime_ECM" SG_ 2654339083 StayActiveSource_TRANSM_1 0;
BA_ "GenSigTimeoutTime_EPS" SG_ 2654339083 StayActiveSource_TRANSM_1 0;
BA_ "GenSigTimeoutTime_IPC" SG_ 2654339083 StayActiveSource_TRANSM_1 0;
BA_ "GenSigTimeoutTime_MTA" SG_ 2654339083 StayActiveSource_TRANSM_1 0;
BA_ "GenSigTimeoutTime_ORC" SG_ 2654339083 StayActiveSource_TRANSM_1 0;
BA_ "GenSigTimeoutTime_PAM" SG_ 2654339083 StayActiveSource_TRANSM_1 0;
BA_ "GenSigTimeoutTime_BCM" SG_ 2654339083 StayActiveSource_TRANSM_10 0;
BA_ "GenSigTimeoutTime_BSM" SG_ 2654339083 StayActiveSource_TRANSM_10 0;
BA_ "GenSigTimeoutTime_DIAG_TEST" SG_ 2654339083 StayActiveSource_TRANSM_10 0;
BA_ "GenSigTimeoutTime_ECM" SG_ 2654339083 StayActiveSource_TRANSM_10 0;
BA_ "GenSigTimeoutTime_EPS" SG_ 2654339083 StayActiveSource_TRANSM_10 0;
BA_ "GenSigTimeoutTime_IPC" SG_ 2654339083 StayActiveSource_TRANSM_10 0;
BA_ "GenSigTimeoutTime_MTA" SG_ 2654339083 StayActiveSource_TRANSM_10 0;
BA_ "GenSigTimeoutTime_ORC" SG_ 2654339083 StayActiveSource_TRANSM_10 0;
BA_ "GenSigTimeoutTime_PAM" SG_ 2654339083 StayActiveSource_TRANSM_10 0;
BA_ "GenSigTimeoutTime_BCM" SG_ 2654339083 StayActiveSource_TRANSM_11 0;
BA_ "GenSigTimeoutTime_BSM" SG_ 2654339083 StayActiveSource_TRANSM_11 0;
BA_ "GenSigTimeoutTime_DIAG_TEST" SG_ 2654339083 StayActiveSource_TRANSM_11 0;
BA_ "GenSigTimeoutTime_ECM" SG_ 2654339083 StayActiveSource_TRANSM_11 0;
BA_ "GenSigTimeoutTime_EPS" SG_ 2654339083 StayActiveSource_TRANSM_11 0;
BA_ "GenSigTimeoutTime_IPC" SG_ 2654339083 StayActiveSource_TRANSM_11 0;
BA_ "GenSigTimeoutTime_MTA" SG_ 2654339083 StayActiveSource_TRANSM_11 0;
BA_ "GenSigTimeoutTime_ORC" SG_ 2654339083 StayActiveSource_TRANSM_11 0;
BA_ "GenSigTimeoutTime_PAM" SG_ 2654339083 StayActiveSource_TRANSM_11 0;
BA_ "GenSigTimeoutTime_BCM" SG_ 2654339083 StayActiveSource_TRANSM_12 0;
BA_ "GenSigTimeoutTime_BSM" SG_ 2654339083 StayActiveSource_TRANSM_12 0;
BA_ "GenSigTimeoutTime_DIAG_TEST" SG_ 2654339083 StayActiveSource_TRANSM_12 0;
BA_ "GenSigTimeoutTime_ECM" SG_ 2654339083 StayActiveSource_TRANSM_12 0;
BA_ "GenSigTimeoutTime_EPS" SG_ 2654339083 StayActiveSource_TRANSM_12 0;
BA_ "GenSigTimeoutTime_IPC" SG_ 2654339083 StayActiveSource_TRANSM_12 0;
BA_ "GenSigTimeoutTime_MTA" SG_ 2654339083 StayActiveSource_TRANSM_12 0;
BA_ "GenSigTimeoutTime_ORC" SG_ 2654339083 StayActiveSource_TRANSM_12 0;
BA_ "GenSigTimeoutTime_PAM" SG_ 2654339083 StayActiveSource_TRANSM_12 0;
BA_ "GenSigTimeoutTime_BCM" SG_ 2654339083 StayActiveSource_TRANSM_13 0;
BA_ "GenSigTimeoutTime_BSM" SG_ 2654339083 StayActiveSource_TRANSM_13 0;
BA_ "GenSigTimeoutTime_DIAG_TEST" SG_ 2654339083 StayActiveSource_TRANSM_13 0;
BA_ "GenSigTimeoutTime_ECM" SG_ 2654339083 StayActiveSource_TRANSM_13 0;
BA_ "GenSigTimeoutTime_EPS" SG_ 2654339083 StayActiveSource_TRANSM_13 0;
BA_ "GenSigTimeoutTime_IPC" SG_ 2654339083 StayActiveSource_TRANSM_13 0;
BA_ "GenSigTimeoutTime_MTA" SG_ 2654339083 StayActiveSource_TRANSM_13 0;
BA_ "GenSigTimeoutTime_ORC" SG_ 2654339083 StayActiveSource_TRANSM_13 0;
BA_ "GenSigTimeoutTime_PAM" SG_ 2654339083 StayActiveSource_TRANSM_13 0;
BA_ "GenSigTimeoutTime_BCM" SG_ 2654339083 StayActiveSource_TRANSM_14 0;
BA_ "GenSigTimeoutTime_BSM" SG_ 2654339083 StayActiveSource_TRANSM_14 0;
BA_ "GenSigTimeoutTime_DIAG_TEST" SG_ 2654339083 StayActiveSource_TRANSM_14 0;
BA_ "GenSigTimeoutTime_ECM" SG_ 2654339083 StayActiveSource_TRANSM_14 0;
BA_ "GenSigTimeoutTime_EPS" SG_ 2654339083 StayActiveSource_TRANSM_14 0;
BA_ "GenSigTimeoutTime_IPC" SG_ 2654339083 StayActiveSource_TRANSM_14 0;
BA_ "GenSigTimeoutTime_MTA" SG_ 2654339083 StayActiveSource_TRANSM_14 0;
BA_ "GenSigTimeoutTime_ORC" SG_ 2654339083 StayActiveSource_TRANSM_14 0;
BA_ "GenSigTimeoutTime_PAM" SG_ 2654339083 StayActiveSource_TRANSM_14 0;
BA_ "GenSigTimeoutTime_BCM" SG_ 2654339083 StayActiveSource_TRANSM_15 0;
BA_ "GenSigTimeoutTime_BSM" SG_ 2654339083 StayActiveSource_TRANSM_15 0;
BA_ "GenSigTimeoutTime_DIAG_TEST" SG_ 2654339083 StayActiveSource_TRANSM_15 0;
BA_ "GenSigTimeoutTime_ECM" SG_ 2654339083 StayActiveSource_TRANSM_15 0;
BA_ "GenSigTimeoutTime_EPS" SG_ 2654339083 StayActiveSource_TRANSM_15 0;
BA_ "GenSigTimeoutTime_IPC" SG_ 2654339083 StayActiveSource_TRANSM_15 0;
BA_ "GenSigTimeoutTime_MTA" SG_ 2654339083 StayActiveSource_TRANSM_15 0;
BA_ "GenSigTimeoutTime_ORC" SG_ 2654339083 StayActiveSource_TRANSM_15 0;
BA_ "GenSigTimeoutTime_PAM" SG_ 2654339083 StayActiveSource_TRANSM_15 0;
BA_ "GenSigTimeoutTime_BCM" SG_ 2654339083 StayActiveSource_TRANSM_2 0;
BA_ "GenSigTimeoutTime_BSM" SG_ 2654339083 StayActiveSource_TRANSM_2 0;
BA_ "GenSigTimeoutTime_DIAG_TEST" SG_ 2654339083 StayActiveSource_TRANSM_2 0;
BA_ "GenSigTimeoutTime_ECM" SG_ 2654339083 StayActiveSource_TRANSM_2 0;
BA_ "GenSigTimeoutTime_EPS" SG_ 2654339083 StayActiveSource_TRANSM_2 0;
BA_ "GenSigTimeoutTime_IPC" SG_ 2654339083 StayActiveSource_TRANSM_2 0;
BA_ "GenSigTimeoutTime_MTA" SG_ 2654339083 StayActiveSource_TRANSM_2 0;
BA_ "GenSigTimeoutTime_ORC" SG_ 2654339083 StayActiveSource_TRANSM_2 0;
BA_ "GenSigTimeoutTime_PAM" SG_ 2654339083 StayActiveSource_TRANSM_2 0;
BA_ "GenSigTimeoutTime_BCM" SG_ 2654339083 StayActiveSource_TRANSM_3 0;
BA_ "GenSigTimeoutTime_BSM" SG_ 2654339083 StayActiveSource_TRANSM_3 0;
BA_ "GenSigTimeoutTime_DIAG_TEST" SG_ 2654339083 StayActiveSource_TRANSM_3 0;
BA_ "GenSigTimeoutTime_ECM" SG_ 2654339083 StayActiveSource_TRANSM_3 0;
BA_ "GenSigTimeoutTime_EPS" SG_ 2654339083 StayActiveSource_TRANSM_3 0;
BA_ "GenSigTimeoutTime_IPC" SG_ 2654339083 StayActiveSource_TRANSM_3 0;
BA_ "GenSigTimeoutTime_MTA" SG_ 2654339083 StayActiveSource_TRANSM_3 0;
BA_ "GenSigTimeoutTime_ORC" SG_ 2654339083 StayActiveSource_TRANSM_3 0;
BA_ "GenSigTimeoutTime_PAM" SG_ 2654339083 StayActiveSource_TRANSM_3 0;
BA_ "GenSigTimeoutTime_BCM" SG_ 2654339083 StayActiveSource_TRANSM_4 0;
BA_ "GenSigTimeoutTime_BSM" SG_ 2654339083 StayActiveSource_TRANSM_4 0;
BA_ "GenSigTimeoutTime_DIAG_TEST" SG_ 2654339083 StayActiveSource_TRANSM_4 0;
BA_ "GenSigTimeoutTime_ECM" SG_ 2654339083 StayActiveSource_TRANSM_4 0;
BA_ "GenSigTimeoutTime_EPS" SG_ 2654339083 StayActiveSource_TRANSM_4 0;
BA_ "GenSigTimeoutTime_IPC" SG_ 2654339083 StayActiveSource_TRANSM_4 0;
BA_ "GenSigTimeoutTime_MTA" SG_ 2654339083 StayActiveSource_TRANSM_4 0;
BA_ "GenSigTimeoutTime_ORC" SG_ 2654339083 StayActiveSource_TRANSM_4 0;
BA_ "GenSigTimeoutTime_PAM" SG_ 2654339083 StayActiveSource_TRANSM_4 0;
BA_ "GenSigTimeoutTime_BCM" SG_ 2654339083 StayActiveSource_TRANSM_5 0;
BA_ "GenSigTimeoutTime_BSM" SG_ 2654339083 StayActiveSource_TRANSM_5 0;
BA_ "GenSigTimeoutTime_DIAG_TEST" SG_ 2654339083 StayActiveSource_TRANSM_5 0;
BA_ "GenSigTimeoutTime_ECM" SG_ 2654339083 StayActiveSource_TRANSM_5 0;
BA_ "GenSigTimeoutTime_EPS" SG_ 2654339083 StayActiveSource_TRANSM_5 0;
BA_ "GenSigTimeoutTime_IPC" SG_ 2654339083 StayActiveSource_TRANSM_5 0;
BA_ "GenSigTimeoutTime_MTA" SG_ 2654339083 StayActiveSource_TRANSM_5 0;
BA_ "GenSigTimeoutTime_ORC" SG_ 2654339083 StayActiveSource_TRANSM_5 0;
BA_ "GenSigTimeoutTime_PAM" SG_ 2654339083 StayActiveSource_TRANSM_5 0;
BA_ "GenSigTimeoutTime_BCM" SG_ 2654339083 StayActiveSource_TRANSM_6 0;
BA_ "GenSigTimeoutTime_BSM" SG_ 2654339083 StayActiveSource_TRANSM_6 0;
BA_ "GenSigTimeoutTime_DIAG_TEST" SG_ 2654339083 StayActiveSource_TRANSM_6 0;
BA_ "GenSigTimeoutTime_ECM" SG_ 2654339083 StayActiveSource_TRANSM_6 0;
BA_ "GenSigTimeoutTime_EPS" SG_ 2654339083 StayActiveSource_TRANSM_6 0;
BA_ "GenSigTimeoutTime_IPC" SG_ 2654339083 StayActiveSource_TRANSM_6 0;
BA_ "GenSigTimeoutTime_MTA" SG_ 2654339083 StayActiveSource_TRANSM_6 0;
BA_ "GenSigTimeoutTime_ORC" SG_ 2654339083 StayActiveSource_TRANSM_6 0;
BA_ "GenSigTimeoutTime_PAM" SG_ 2654339083 StayActiveSource_TRANSM_6 0;
BA_ "GenSigTimeoutTime_BCM" SG_ 2654339083 StayActiveSource_TRANSM_7 0;
BA_ "GenSigTimeoutTime_BSM" SG_ 2654339083 StayActiveSource_TRANSM_7 0;
BA_ "GenSigTimeoutTime_DIAG_TEST" SG_ 2654339083 StayActiveSource_TRANSM_7 0;
BA_ "GenSigTimeoutTime_ECM" SG_ 2654339083 StayActiveSource_TRANSM_7 0;
BA_ "GenSigTimeoutTime_EPS" SG_ 2654339083 StayActiveSource_TRANSM_7 0;
BA_ "GenSigTimeoutTime_IPC" SG_ 2654339083 StayActiveSource_TRANSM_7 0;
BA_ "GenSigTimeoutTime_MTA" SG_ 2654339083 StayActiveSource_TRANSM_7 0;
BA_ "GenSigTimeoutTime_ORC" SG_ 2654339083 StayActiveSource_TRANSM_7 0;
BA_ "GenSigTimeoutTime_PAM" SG_ 2654339083 StayActiveSource_TRANSM_7 0;
BA_ "GenSigTimeoutTime_BCM" SG_ 2654339083 StayActiveSource_TRANSM_8 0;
BA_ "GenSigTimeoutTime_BSM" SG_ 2654339083 StayActiveSource_TRANSM_8 0;
BA_ "GenSigTimeoutTime_DIAG_TEST" SG_ 2654339083 StayActiveSource_TRANSM_8 0;
BA_ "GenSigTimeoutTime_ECM" SG_ 2654339083 StayActiveSource_TRANSM_8 0;
BA_ "GenSigTimeoutTime_EPS" SG_ 2654339083 StayActiveSource_TRANSM_8 0;
BA_ "GenSigTimeoutTime_IPC" SG_ 2654339083 StayActiveSource_TRANSM_8 0;
BA_ "GenSigTimeoutTime_MTA" SG_ 2654339083 StayActiveSource_TRANSM_8 0;
BA_ "GenSigTimeoutTime_ORC" SG_ 2654339083 StayActiveSource_TRANSM_8 0;
BA_ "GenSigTimeoutTime_PAM" SG_ 2654339083 StayActiveSource_TRANSM_8 0;
BA_ "GenSigTimeoutTime_BCM" SG_ 2654339083 StayActiveSource_TRANSM_9 0;
BA_ "GenSigTimeoutTime_BSM" SG_ 2654339083 StayActiveSource_TRANSM_9 0;
BA_ "GenSigTimeoutTime_DIAG_TEST" SG_ 2654339083 StayActiveSource_TRANSM_9 0;
BA_ "GenSigTimeoutTime_ECM" SG_ 2654339083 StayActiveSource_TRANSM_9 0;
BA_ "GenSigTimeoutTime_EPS" SG_ 2654339083 StayActiveSource_TRANSM_9 0;
BA_ "GenSigTimeoutTime_IPC" SG_ 2654339083 StayActiveSource_TRANSM_9 0;
BA_ "GenSigTimeoutTime_MTA" SG_ 2654339083 StayActiveSource_TRANSM_9 0;
BA_ "GenSigTimeoutTime_ORC" SG_ 2654339083 StayActiveSource_TRANSM_9 0;
BA_ "GenSigTimeoutTime_PAM" SG_ 2654339083 StayActiveSource_TRANSM_9 0;
BA_ "GenSigTimeoutTime_BCM" SG_ 249 CreepingClutchTargetTorque 0;
BA_ "GenSigTimeoutTime_BSM" SG_ 249 CreepingClutchTargetTorque 0;
BA_ "GenSigTimeoutTime_DIAG_TEST" SG_ 249 CreepingClutchTargetTorque 0;
BA_ "GenSigTimeoutTime_EPS" SG_ 249 CreepingClutchTargetTorque 0;
BA_ "GenSigTimeoutTime_IPC" SG_ 249 CreepingClutchTargetTorque 0;
BA_ "GenSigTimeoutTime_MTA" SG_ 249 CreepingClutchTargetTorque 0;
BA_ "GenSigTimeoutTime_ORC" SG_ 249 CreepingClutchTargetTorque 0;
BA_ "GenSigTimeoutTime_PAM" SG_ 249 CreepingClutchTargetTorque 0;
BA_ "GenSigTimeoutTime_BCM" SG_ 249 CreepingClutchTorque 0;
BA_ "GenSigTimeoutTime_BSM" SG_ 249 CreepingClutchTorque 0;
BA_ "GenSigTimeoutTime_DIAG_TEST" SG_ 249 CreepingClutchTorque 0;
BA_ "GenSigTimeoutTime_EPS" SG_ 249 CreepingClutchTorque 0;
BA_ "GenSigTimeoutTime_IPC" SG_ 249 CreepingClutchTorque 0;
BA_ "GenSigTimeoutTime_MTA" SG_ 249 CreepingClutchTorque 0;
BA_ "GenSigTimeoutTime_ORC" SG_ 249 CreepingClutchTorque 0;
BA_ "GenSigTimeoutTime_PAM" SG_ 249 CreepingClutchTorque 0;
BA_ "GenSigTimeoutTime_BCM" SG_ 249 CreepingEnable 0;
BA_ "GenSigTimeoutTime_BSM" SG_ 249 CreepingEnable 0;
BA_ "GenSigTimeoutTime_DIAG_TEST" SG_ 249 CreepingEnable 0;
BA_ "GenSigTimeoutTime_EPS" SG_ 249 CreepingEnable 0;
BA_ "GenSigTimeoutTime_IPC" SG_ 249 CreepingEnable 0;
BA_ "GenSigTimeoutTime_MTA" SG_ 249 CreepingEnable 0;
BA_ "GenSigTimeoutTime_ORC" SG_ 249 CreepingEnable 0;
BA_ "GenSigTimeoutTime_PAM" SG_ 249 CreepingEnable 0;
BA_ "GenSigSendType" SG_ 1200 ABSFailSts 3;
BA_ "GenSigTimeoutTime_BCM" SG_ 1200 ABSFailSts 0;
BA_ "GenSigTimeoutTime_BSM" SG_ 1200 ABSFailSts 0;
BA_ "GenSigTimeoutTime_DIAG_TEST" SG_ 1200 ABSFailSts 0;
BA_ "GenSigTimeoutTime_ECM" SG_ 1200 ABSFailSts 0;
BA_ "GenSigTimeoutTime_EPS" SG_ 1200 ABSFailSts 0;
BA_ "GenSigTimeoutTime_ORC" SG_ 1200 ABSFailSts 0;
BA_ "GenSigTimeoutTime_PAM" SG_ 1200 ABSFailSts 0;
BA_ "GenSigSendType" SG_ 1200 EBDFailSts 3;
BA_ "GenSigTimeoutTime_BCM" SG_ 1200 EBDFailSts 0;
BA_ "GenSigTimeoutTime_BSM" SG_ 1200 EBDFailSts 0;
BA_ "GenSigTimeoutTime_DIAG_TEST" SG_ 1200 EBDFailSts 0;
BA_ "GenSigTimeoutTime_ECM" SG_ 1200 EBDFailSts 0;
BA_ "GenSigTimeoutTime_EPS" SG_ 1200 EBDFailSts 0;
BA_ "GenSigTimeoutTime_MTA" SG_ 1200 EBDFailSts 0;
BA_ "GenSigTimeoutTime_ORC" SG_ 1200 EBDFailSts 0;
BA_ "GenSigTimeoutTime_PAM" SG_ 1200 EBDFailSts 0;
BA_ "GenSigSendType" SG_ 1200 ESCFailSts 3;
BA_ "GenSigTimeoutTime_BCM" SG_ 1200 ESCFailSts 0;
BA_ "GenSigTimeoutTime_BSM" SG_ 1200 ESCFailSts 0;
BA_ "GenSigTimeoutTime_DIAG_TEST" SG_ 1200 ESCFailSts 0;
BA_ "GenSigTimeoutTime_ECM" SG_ 1200 ESCFailSts 0;
BA_ "GenSigTimeoutTime_EPS" SG_ 1200 ESCFailSts 0;
BA_ "GenSigTimeoutTime_ORC" SG_ 1200 ESCFailSts 0;
BA_ "GenSigTimeoutTime_PAM" SG_ 1200 ESCFailSts 0;
BA_ "GenSigSendType" SG_ 1200 ESCIntervention 3;
BA_ "GenSigTimeoutTime_BCM" SG_ 1200 ESCIntervention 0;
BA_ "GenSigTimeoutTime_BSM" SG_ 1200 ESCIntervention 0;
BA_ "GenSigTimeoutTime_DIAG_TEST" SG_ 1200 ESCIntervention 0;
BA_ "GenSigTimeoutTime_ECM" SG_ 1200 ESCIntervention 0;
BA_ "GenSigTimeoutTime_EPS" SG_ 1200 ESCIntervention 0;
BA_ "GenSigTimeoutTime_ORC" SG_ 1200 ESCIntervention 0;
BA_ "GenSigTimeoutTime_PAM" SG_ 1200 ESCIntervention 0;
BA_ "GenSigSendType" SG_ 1200 FunctionFailSts 3;
BA_ "GenSigTimeoutTime_BCM" SG_ 1200 FunctionFailSts 0;
BA_ "GenSigTimeoutTime_BSM" SG_ 1200 FunctionFailSts 0;
BA_ "GenSigTimeoutTime_DIAG_TEST" SG_ 1200 FunctionFailSts 0;
BA_ "GenSigTimeoutTime_ECM" SG_ 1200 FunctionFailSts 0;
BA_ "GenSigTimeoutTime_EPS" SG_ 1200 FunctionFailSts 0;
BA_ "GenSigTimeoutTime_IPC" SG_ 1200 FunctionFailSts 0;
BA_ "GenSigTimeoutTime_MTA" SG_ 1200 FunctionFailSts 0;
BA_ "GenSigTimeoutTime_ORC" SG_ 1200 FunctionFailSts 0;
BA_ "GenSigTimeoutTime_PAM" SG_ 1200 FunctionFailSts 0;
BA_ "GenSigSendType" SG_ 1200 FunctionIntervention 3;
BA_ "GenSigTimeoutTime_BCM" SG_ 1200 FunctionIntervention 0;
BA_ "GenSigTimeoutTime_BSM" SG_ 1200 FunctionIntervention 0;
BA_ "GenSigTimeoutTime_DIAG_TEST" SG_ 1200 FunctionIntervention 0;
BA_ "GenSigTimeoutTime_ECM" SG_ 1200 FunctionIntervention 0;
BA_ "GenSigTimeoutTime_EPS" SG_ 1200 FunctionIntervention 0;
BA_ "GenSigTimeoutTime_IPC" SG_ 1200 FunctionIntervention 0;
BA_ "GenSigTimeoutTime_MTA" SG_ 1200 FunctionIntervention 0;
BA_ "GenSigTimeoutTime_ORC" SG_ 1200 FunctionIntervention 0;
BA_ "GenSigTimeoutTime_PAM" SG_ 1200 FunctionIntervention 0;
BA_ "GenSigSendType" SG_ 1200 FunctionSts 3;
BA_ "GenSigTimeoutTime_BCM" SG_ 1200 FunctionSts 0;
BA_ "GenSigTimeoutTime_BSM" SG_ 1200 FunctionSts 0;
BA_ "GenSigTimeoutTime_DIAG_TEST" SG_ 1200 FunctionSts 0;
BA_ "GenSigTimeoutTime_ECM" SG_ 1200 FunctionSts 0;
BA_ "GenSigTimeoutTime_EPS" SG_ 1200 FunctionSts 0;
BA_ "GenSigTimeoutTime_MTA" SG_ 1200 FunctionSts 0;
BA_ "GenSigTimeoutTime_ORC" SG_ 1200 FunctionSts 0;
BA_ "GenSigTimeoutTime_PAM" SG_ 1200 FunctionSts 0;
BA_ "GenSigSendType" SG_ 1200 HillHolderFailSts 3;
BA_ "GenSigTimeoutTime_BCM" SG_ 1200 HillHolderFailSts 0;
BA_ "GenSigTimeoutTime_BSM" SG_ 1200 HillHolderFailSts 0;
BA_ "GenSigTimeoutTime_DIAG_TEST" SG_ 1200 HillHolderFailSts 0;
BA_ "GenSigTimeoutTime_EPS" SG_ 1200 HillHolderFailSts 0;
BA_ "GenSigTimeoutTime_ORC" SG_ 1200 HillHolderFailSts 0;
BA_ "GenSigTimeoutTime_PAM" SG_ 1200 HillHolderFailSts 0;
BA_ "GenSigTimeoutTime_BCM" SG_ 1200 TPMActivitySts 0;
BA_ "GenSigTimeoutTime_BSM" SG_ 1200 TPMActivitySts 0;
BA_ "GenSigTimeoutTime_DIAG_TEST" SG_ 1200 TPMActivitySts 0;
BA_ "GenSigTimeoutTime_ECM" SG_ 1200 TPMActivitySts 0;
BA_ "GenSigTimeoutTime_EPS" SG_ 1200 TPMActivitySts 0;
BA_ "GenSigTimeoutTime_MTA" SG_ 1200 TPMActivitySts 0;
BA_ "GenSigTimeoutTime_ORC" SG_ 1200 TPMActivitySts 0;
BA_ "GenSigTimeoutTime_PAM" SG_ 1200 TPMActivitySts 0;
BA_ "GenSigTimeoutTime_BSM" SG_ 1200 TravelDistance 0;
BA_ "GenSigTimeoutTime_DIAG_TEST" SG_ 1200 TravelDistance 0;
BA_ "GenSigTimeoutTime_EPS" SG_ 1200 TravelDistance 0;
BA_ "GenSigTimeoutTime_MTA" SG_ 1200 TravelDistance 0;
BA_ "GenSigTimeoutTime_ORC" SG_ 1200 TravelDistance 0;
BA_ "GenSigTimeoutTime_PAM" SG_ 1200 TravelDistance 0;
BA_ "GenSigSendType" SG_ 1200 TyreInflationState_LHF_Tyre 4;
BA_ "GenSigTimeoutTime_BCM" SG_ 1200 TyreInflationState_LHF_Tyre 0;
BA_ "GenSigTimeoutTime_BSM" SG_ 1200 TyreInflationState_LHF_Tyre 0;
BA_ "GenSigTimeoutTime_DIAG_TEST" SG_ 1200 TyreInflationState_LHF_Tyre 0;
BA_ "GenSigTimeoutTime_ECM" SG_ 1200 TyreInflationState_LHF_Tyre 0;
BA_ "GenSigTimeoutTime_EPS" SG_ 1200 TyreInflationState_LHF_Tyre 0;
BA_ "GenSigTimeoutTime_MTA" SG_ 1200 TyreInflationState_LHF_Tyre 0;
BA_ "GenSigTimeoutTime_ORC" SG_ 1200 TyreInflationState_LHF_Tyre 0;
BA_ "GenSigTimeoutTime_PAM" SG_ 1200 TyreInflationState_LHF_Tyre 0;
BA_ "GenSigSendType" SG_ 1200 TyreInflationState_LHR_Tyre 4;
BA_ "GenSigTimeoutTime_BCM" SG_ 1200 TyreInflationState_LHR_Tyre 0;
BA_ "GenSigTimeoutTime_BSM" SG_ 1200 TyreInflationState_LHR_Tyre 0;
BA_ "GenSigTimeoutTime_DIAG_TEST" SG_ 1200 TyreInflationState_LHR_Tyre 0;
BA_ "GenSigTimeoutTime_ECM" SG_ 1200 TyreInflationState_LHR_Tyre 0;
BA_ "GenSigTimeoutTime_EPS" SG_ 1200 TyreInflationState_LHR_Tyre 0;
BA_ "GenSigTimeoutTime_MTA" SG_ 1200 TyreInflationState_LHR_Tyre 0;
BA_ "GenSigTimeoutTime_ORC" SG_ 1200 TyreInflationState_LHR_Tyre 0;
BA_ "GenSigTimeoutTime_PAM" SG_ 1200 TyreInflationState_LHR_Tyre 0;
BA_ "GenSigSendType" SG_ 1200 TyreInflationState_RHF_Tyre 4;
BA_ "GenSigTimeoutTime_BCM" SG_ 1200 TyreInflationState_RHF_Tyre 0;
BA_ "GenSigTimeoutTime_BSM" SG_ 1200 TyreInflationState_RHF_Tyre 0;
BA_ "GenSigTimeoutTime_DIAG_TEST" SG_ 1200 TyreInflationState_RHF_Tyre 0;
BA_ "GenSigTimeoutTime_ECM" SG_ 1200 TyreInflationState_RHF_Tyre 0;
BA_ "GenSigTimeoutTime_EPS" SG_ 1200 TyreInflationState_RHF_Tyre 0;
BA_ "GenSigTimeoutTime_MTA" SG_ 1200 TyreInflationState_RHF_Tyre 0;
BA_ "GenSigTimeoutTime_ORC" SG_ 1200 TyreInflationState_RHF_Tyre 0;
BA_ "GenSigTimeoutTime_PAM" SG_ 1200 TyreInflationState_RHF_Tyre 0;
BA_ "GenSigSendType" SG_ 1200 TyreInflationState_RHR_Tyre 4;
BA_ "GenSigTimeoutTime_BCM" SG_ 1200 TyreInflationState_RHR_Tyre 0;
BA_ "GenSigTimeoutTime_BSM" SG_ 1200 TyreInflationState_RHR_Tyre 0;
BA_ "GenSigTimeoutTime_DIAG_TEST" SG_ 1200 TyreInflationState_RHR_Tyre 0;
BA_ "GenSigTimeoutTime_ECM" SG_ 1200 TyreInflationState_RHR_Tyre 0;
BA_ "GenSigTimeoutTime_EPS" SG_ 1200 TyreInflationState_RHR_Tyre 0;
BA_ "GenSigTimeoutTime_MTA" SG_ 1200 TyreInflationState_RHR_Tyre 0;
BA_ "GenSigTimeoutTime_ORC" SG_ 1200 TyreInflationState_RHR_Tyre 0;
BA_ "GenSigTimeoutTime_PAM" SG_ 1200 TyreInflationState_RHR_Tyre 0;
BA_ "GenSigSendType" SG_ 1200 TyrePressureSystemFailSts 4;
BA_ "GenSigTimeoutTime_BCM" SG_ 1200 TyrePressureSystemFailSts 0;
BA_ "GenSigTimeoutTime_BSM" SG_ 1200 TyrePressureSystemFailSts 0;
BA_ "GenSigTimeoutTime_DIAG_TEST" SG_ 1200 TyrePressureSystemFailSts 0;
BA_ "GenSigTimeoutTime_ECM" SG_ 1200 TyrePressureSystemFailSts 0;
BA_ "GenSigTimeoutTime_EPS" SG_ 1200 TyrePressureSystemFailSts 0;
BA_ "GenSigTimeoutTime_MTA" SG_ 1200 TyrePressureSystemFailSts 0;
BA_ "GenSigTimeoutTime_ORC" SG_ 1200 TyrePressureSystemFailSts 0;
BA_ "GenSigTimeoutTime_PAM" SG_ 1200 TyrePressureSystemFailSts 0;
BA_ "GenSigTimeoutTime_BCM" SG_ 1350 BatteryChargeSts 0;
BA_ "GenSigTimeoutTime_BSM" SG_ 1350 BatteryChargeSts 0;
BA_ "GenSigTimeoutTime_DIAG_TEST" SG_ 1350 BatteryChargeSts 0;
BA_ "GenSigTimeoutTime_EPS" SG_ 1350 BatteryChargeSts 0;
BA_ "GenSigTimeoutTime_IPC" SG_ 1350 BatteryChargeSts 0;
BA_ "GenSigTimeoutTime_MTA" SG_ 1350 BatteryChargeSts 0;
BA_ "GenSigTimeoutTime_ORC" SG_ 1350 BatteryChargeSts 0;
BA_ "GenSigTimeoutTime_PAM" SG_ 1350 BatteryChargeSts 0;
BA_ "GenSigTimeoutTime_BCM" SG_ 1350 BCMAutoCrankSts 0;
BA_ "GenSigTimeoutTime_BSM" SG_ 1350 BCMAutoCrankSts 0;
BA_ "GenSigTimeoutTime_DIAG_TEST" SG_ 1350 BCMAutoCrankSts 0;
BA_ "GenSigTimeoutTime_EPS" SG_ 1350 BCMAutoCrankSts 0;
BA_ "GenSigTimeoutTime_IPC" SG_ 1350 BCMAutoCrankSts 0;
BA_ "GenSigTimeoutTime_MTA" SG_ 1350 BCMAutoCrankSts 0;
BA_ "GenSigTimeoutTime_ORC" SG_ 1350 BCMAutoCrankSts 0;
BA_ "GenSigTimeoutTime_PAM" SG_ 1350 BCMAutoCrankSts 0;
BA_ "GenSigTimeoutTime_BCM" SG_ 1350 BCMAutoStopEnabledSts 0;
BA_ "GenSigTimeoutTime_BSM" SG_ 1350 BCMAutoStopEnabledSts 0;
BA_ "GenSigTimeoutTime_DIAG_TEST" SG_ 1350 BCMAutoStopEnabledSts 0;
BA_ "GenSigTimeoutTime_EPS" SG_ 1350 BCMAutoStopEnabledSts 0;
BA_ "GenSigTimeoutTime_IPC" SG_ 1350 BCMAutoStopEnabledSts 0;
BA_ "GenSigTimeoutTime_MTA" SG_ 1350 BCMAutoStopEnabledSts 0;
BA_ "GenSigTimeoutTime_ORC" SG_ 1350 BCMAutoStopEnabledSts 0;
BA_ "GenSigTimeoutTime_PAM" SG_ 1350 BCMAutoStopEnabledSts 0;
BA_ "GenSigTimeoutTime_BCM" SG_ 1350 BCMAutoStopStaySts 0;
BA_ "GenSigTimeoutTime_BSM" SG_ 1350 BCMAutoStopStaySts 0;
BA_ "GenSigTimeoutTime_DIAG_TEST" SG_ 1350 BCMAutoStopStaySts 0;
BA_ "GenSigTimeoutTime_EPS" SG_ 1350 BCMAutoStopStaySts 0;
BA_ "GenSigTimeoutTime_IPC" SG_ 1350 BCMAutoStopStaySts 0;
BA_ "GenSigTimeoutTime_MTA" SG_ 1350 BCMAutoStopStaySts 0;
BA_ "GenSigTimeoutTime_ORC" SG_ 1350 BCMAutoStopStaySts 0;
BA_ "GenSigTimeoutTime_PAM" SG_ 1350 BCMAutoStopStaySts 0;
BA_ "GenSigStartValue" SG_ 1350 BCMStopStartButtonSts 1;
BA_ "GenSigTimeoutTime_BCM" SG_ 1350 BCMStopStartButtonSts 0;
BA_ "GenSigTimeoutTime_BSM" SG_ 1350 BCMStopStartButtonSts 0;
BA_ "GenSigTimeoutTime_DIAG_TEST" SG_ 1350 BCMStopStartButtonSts 0;
BA_ "GenSigTimeoutTime_EPS" SG_ 1350 BCMStopStartButtonSts 0;
BA_ "GenSigTimeoutTime_IPC" SG_ 1350 BCMStopStartButtonSts 0;
BA_ "GenSigTimeoutTime_MTA" SG_ 1350 BCMStopStartButtonSts 0;
BA_ "GenSigTimeoutTime_ORC" SG_ 1350 BCMStopStartButtonSts 0;
BA_ "GenSigTimeoutTime_PAM" SG_ 1350 BCMStopStartButtonSts 0;
BA_ "GenSigTimeoutTime_BCM" SG_ 1350 ChkFuelLevelSts 0;
BA_ "GenSigTimeoutTime_BSM" SG_ 1350 ChkFuelLevelSts 0;
BA_ "GenSigTimeoutTime_DIAG_TEST" SG_ 1350 ChkFuelLevelSts 0;
BA_ "GenSigTimeoutTime_ECM" SG_ 1350 ChkFuelLevelSts 0;
BA_ "GenSigTimeoutTime_EPS" SG_ 1350 ChkFuelLevelSts 0;
BA_ "GenSigTimeoutTime_IPC" SG_ 1350 ChkFuelLevelSts 0;
BA_ "GenSigTimeoutTime_MTA" SG_ 1350 ChkFuelLevelSts 0;
BA_ "GenSigTimeoutTime_ORC" SG_ 1350 ChkFuelLevelSts 0;
BA_ "GenSigTimeoutTime_PAM" SG_ 1350 ChkFuelLevelSts 0;
BA_ "GenSigStartValue" SG_ 1350 ExternalTemperature 511;
BA_ "GenSigTimeoutTime_BCM" SG_ 1350 ExternalTemperature 0;
BA_ "GenSigTimeoutTime_DIAG_TEST" SG_ 1350 ExternalTemperature 0;
BA_ "GenSigTimeoutTime_EPS" SG_ 1350 ExternalTemperature 0;
BA_ "GenSigTimeoutTime_IPC" SG_ 1350 ExternalTemperature 0;
BA_ "GenSigTimeoutTime_ORC" SG_ 1350 ExternalTemperature 0;
BA_ "GenSigTimeoutTime_PAM" SG_ 1350 ExternalTemperature 0;
BA_ "GenSigTimeoutTime_BCM" SG_ 1350 ExternalTemperatureFailSts 0;
BA_ "GenSigTimeoutTime_DIAG_TEST" SG_ 1350 ExternalTemperatureFailSts 0;
BA_ "GenSigTimeoutTime_EPS" SG_ 1350 ExternalTemperatureFailSts 0;
BA_ "GenSigTimeoutTime_IPC" SG_ 1350 ExternalTemperatureFailSts 0;
BA_ "GenSigTimeoutTime_ORC" SG_ 1350 ExternalTemperatureFailSts 0;
BA_ "GenSigTimeoutTime_PAM" SG_ 1350 ExternalTemperatureFailSts 0;
BA_ "GenSigTimeoutTime_BCM" SG_ 1350 FpsNotAvailable 0;
BA_ "GenSigTimeoutTime_BSM" SG_ 1350 FpsNotAvailable 0;
BA_ "GenSigTimeoutTime_DIAG_TEST" SG_ 1350 FpsNotAvailable 0;
BA_ "GenSigTimeoutTime_ECM" SG_ 1350 FpsNotAvailable 0;
BA_ "GenSigTimeoutTime_EPS" SG_ 1350 FpsNotAvailable 0;
BA_ "GenSigTimeoutTime_MTA" SG_ 1350 FpsNotAvailable 0;
BA_ "GenSigTimeoutTime_ORC" SG_ 1350 FpsNotAvailable 0;
BA_ "GenSigTimeoutTime_PAM" SG_ 1350 FpsNotAvailable 0;
BA_ "GenSigTimeoutTime_BCM" SG_ 1350 FuelLevel 0;
BA_ "GenSigTimeoutTime_BSM" SG_ 1350 FuelLevel 0;
BA_ "GenSigTimeoutTime_DIAG_TEST" SG_ 1350 FuelLevel 0;
BA_ "GenSigTimeoutTime_EPS" SG_ 1350 FuelLevel 0;
BA_ "GenSigTimeoutTime_MTA" SG_ 1350 FuelLevel 0;
BA_ "GenSigTimeoutTime_ORC" SG_ 1350 FuelLevel 0;
BA_ "GenSigTimeoutTime_PAM" SG_ 1350 FuelLevel 0;
BA_ "GenSigTimeoutTime_BCM" SG_ 1350 FuelLevelFailSts 0;
BA_ "GenSigTimeoutTime_BSM" SG_ 1350 FuelLevelFailSts 0;
BA_ "GenSigTimeoutTime_DIAG_TEST" SG_ 1350 FuelLevelFailSts 0;
BA_ "GenSigTimeoutTime_EPS" SG_ 1350 FuelLevelFailSts 0;
BA_ "GenSigTimeoutTime_MTA" SG_ 1350 FuelLevelFailSts 0;
BA_ "GenSigTimeoutTime_ORC" SG_ 1350 FuelLevelFailSts 0;
BA_ "GenSigTimeoutTime_PAM" SG_ 1350 FuelLevelFailSts 0;
BA_ "GenSigStartValue" SG_ 1350 NotFilteredExternalTemp 511;
BA_ "GenSigTimeoutTime_BCM" SG_ 1350 NotFilteredExternalTemp 0;
BA_ "GenSigTimeoutTime_BSM" SG_ 1350 NotFilteredExternalTemp 0;
BA_ "GenSigTimeoutTime_DIAG_TEST" SG_ 1350 NotFilteredExternalTemp 0;
BA_ "GenSigTimeoutTime_ECM" SG_ 1350 NotFilteredExternalTemp 0;
BA_ "GenSigTimeoutTime_EPS" SG_ 1350 NotFilteredExternalTemp 0;
BA_ "GenSigTimeoutTime_IPC" SG_ 1350 NotFilteredExternalTemp 0;
BA_ "GenSigTimeoutTime_MTA" SG_ 1350 NotFilteredExternalTemp 0;
BA_ "GenSigTimeoutTime_ORC" SG_ 1350 NotFilteredExternalTemp 0;
BA_ "GenSigTimeoutTime_PAM" SG_ 1350 NotFilteredExternalTemp 0;
BA_ "GenSigStartValue" SG_ 1350 NotFilteredFuelLevel 255;
BA_ "GenSigTimeoutTime_BCM" SG_ 1350 NotFilteredFuelLevel 0;
BA_ "GenSigTimeoutTime_BSM" SG_ 1350 NotFilteredFuelLevel 0;
BA_ "GenSigTimeoutTime_DIAG_TEST" SG_ 1350 NotFilteredFuelLevel 0;
BA_ "GenSigTimeoutTime_EPS" SG_ 1350 NotFilteredFuelLevel 0;
BA_ "GenSigTimeoutTime_IPC" SG_ 1350 NotFilteredFuelLevel 0;
BA_ "GenSigTimeoutTime_MTA" SG_ 1350 NotFilteredFuelLevel 0;
BA_ "GenSigTimeoutTime_ORC" SG_ 1350 NotFilteredFuelLevel 0;
BA_ "GenSigTimeoutTime_PAM" SG_ 1350 NotFilteredFuelLevel 0;
BA_ "GenSigTimeoutTime_BCM" SG_ 1350 PowerModeSts 0;
BA_ "GenSigTimeoutTime_BSM" SG_ 1350 PowerModeSts 0;
BA_ "GenSigTimeoutTime_DIAG_TEST" SG_ 1350 PowerModeSts 0;
BA_ "GenSigTimeoutTime_ECM" SG_ 1350 PowerModeSts 0;
BA_ "GenSigTimeoutTime_EPS" SG_ 1350 PowerModeSts 0;
BA_ "GenSigTimeoutTime_MTA" SG_ 1350 PowerModeSts 0;
BA_ "GenSigTimeoutTime_ORC" SG_ 1350 PowerModeSts 0;
BA_ "GenSigTimeoutTime_PAM" SG_ 1350 PowerModeSts 0;
BA_ "GenSigSendType" SG_ 1204 BrakeFluidLevelSts 4;
BA_ "GenSigTimeoutTime_BCM" SG_ 1204 BrakeFluidLevelSts 0;
BA_ "GenSigTimeoutTime_BSM" SG_ 1204 BrakeFluidLevelSts 0;
BA_ "GenSigTimeoutTime_DIAG_TEST" SG_ 1204 BrakeFluidLevelSts 0;
BA_ "GenSigTimeoutTime_ECM" SG_ 1204 BrakeFluidLevelSts 0;
BA_ "GenSigTimeoutTime_EPS" SG_ 1204 BrakeFluidLevelSts 0;
BA_ "GenSigTimeoutTime_MTA" SG_ 1204 BrakeFluidLevelSts 0;
BA_ "GenSigTimeoutTime_ORC" SG_ 1204 BrakeFluidLevelSts 0;
BA_ "GenSigTimeoutTime_PAM" SG_ 1204 BrakeFluidLevelSts 0;
BA_ "GenSigSendType" SG_ 1204 CityModeSts 4;
BA_ "GenSigTimeoutTime_BCM" SG_ 1204 CityModeSts 0;
BA_ "GenSigTimeoutTime_BSM" SG_ 1204 CityModeSts 0;
BA_ "GenSigTimeoutTime_DIAG_TEST" SG_ 1204 CityModeSts 0;
BA_ "GenSigTimeoutTime_ECM" SG_ 1204 CityModeSts 0;
BA_ "GenSigTimeoutTime_MTA" SG_ 1204 CityModeSts 0;
BA_ "GenSigTimeoutTime_ORC" SG_ 1204 CityModeSts 0;
BA_ "GenSigTimeoutTime_PAM" SG_ 1204 CityModeSts 0;
BA_ "GenSigSendType" SG_ 1204 CmdIgn_FailSts 4;
BA_ "GenSigTimeoutTime_BCM" SG_ 1204 CmdIgn_FailSts 0;
BA_ "GenSigTimeoutTime_DIAG_TEST" SG_ 1204 CmdIgn_FailSts 0;
BA_ "GenSigTimeoutTime_ORC" SG_ 1204 CmdIgn_FailSts 0;
BA_ "GenSigSendType" SG_ 1204 CmdIgnSts 4;
BA_ "GenSigTimeoutTime_BCM" SG_ 1204 CmdIgnSts 0;
BA_ "GenSigTimeoutTime_DIAG_TEST" SG_ 1204 CmdIgnSts 0;
BA_ "GenSigSendType" SG_ 1204 CompressorACReqSts 4;
BA_ "GenSigTimeoutTime_BCM" SG_ 1204 CompressorACReqSts 0;
BA_ "GenSigTimeoutTime_BSM" SG_ 1204 CompressorACReqSts 0;
BA_ "GenSigTimeoutTime_DIAG_TEST" SG_ 1204 CompressorACReqSts 0;
BA_ "GenSigTimeoutTime_EPS" SG_ 1204 CompressorACReqSts 0;
BA_ "GenSigTimeoutTime_IPC" SG_ 1204 CompressorACReqSts 0;
BA_ "GenSigTimeoutTime_MTA" SG_ 1204 CompressorACReqSts 0;
BA_ "GenSigTimeoutTime_ORC" SG_ 1204 CompressorACReqSts 0;
BA_ "GenSigTimeoutTime_PAM" SG_ 1204 CompressorACReqSts 0;
BA_ "GenSigSendType" SG_ 1204 DriverDoorSts 4;
BA_ "GenSigTimeoutTime_BCM" SG_ 1204 DriverDoorSts 0;
BA_ "GenSigTimeoutTime_BSM" SG_ 1204 DriverDoorSts 0;
BA_ "GenSigTimeoutTime_DIAG_TEST" SG_ 1204 DriverDoorSts 0;
BA_ "GenSigTimeoutTime_ECM" SG_ 1204 DriverDoorSts 0;
BA_ "GenSigTimeoutTime_EPS" SG_ 1204 DriverDoorSts 0;
BA_ "GenSigTimeoutTime_IPC" SG_ 1204 DriverDoorSts 0;
BA_ "GenSigTimeoutTime_ORC" SG_ 1204 DriverDoorSts 0;
BA_ "GenSigTimeoutTime_PAM" SG_ 1204 DriverDoorSts 0;
BA_ "GenSigTimeoutTime_BCM" SG_ 1204 FHeatedWindowSts 0;
BA_ "GenSigTimeoutTime_BSM" SG_ 1204 FHeatedWindowSts 0;
BA_ "GenSigTimeoutTime_DIAG_TEST" SG_ 1204 FHeatedWindowSts 0;
BA_ "GenSigTimeoutTime_EPS" SG_ 1204 FHeatedWindowSts 0;
BA_ "GenSigTimeoutTime_IPC" SG_ 1204 FHeatedWindowSts 0;
BA_ "GenSigTimeoutTime_MTA" SG_ 1204 FHeatedWindowSts 0;
BA_ "GenSigTimeoutTime_ORC" SG_ 1204 FHeatedWindowSts 0;
BA_ "GenSigTimeoutTime_PAM" SG_ 1204 FHeatedWindowSts 0;
BA_ "GenSigSendType" SG_ 1204 HandBrakeSts 4;
BA_ "GenSigTimeoutTime_BCM" SG_ 1204 HandBrakeSts 0;
BA_ "GenSigTimeoutTime_DIAG_TEST" SG_ 1204 HandBrakeSts 0;
BA_ "GenSigTimeoutTime_EPS" SG_ 1204 HandBrakeSts 0;
BA_ "GenSigTimeoutTime_ORC" SG_ 1204 HandBrakeSts 0;
BA_ "GenSigTimeoutTime_PAM" SG_ 1204 HandBrakeSts 0;
BA_ "GenSigSendType" SG_ 1204 HCSS_Req 4;
BA_ "GenSigTimeoutTime_BCM" SG_ 1204 HCSS_Req 0;
BA_ "GenSigTimeoutTime_BSM" SG_ 1204 HCSS_Req 0;
BA_ "GenSigTimeoutTime_DIAG_TEST" SG_ 1204 HCSS_Req 0;
BA_ "GenSigTimeoutTime_EPS" SG_ 1204 HCSS_Req 0;
BA_ "GenSigTimeoutTime_IPC" SG_ 1204 HCSS_Req 0;
BA_ "GenSigTimeoutTime_MTA" SG_ 1204 HCSS_Req 0;
BA_ "GenSigTimeoutTime_ORC" SG_ 1204 HCSS_Req 0;
BA_ "GenSigTimeoutTime_PAM" SG_ 1204 HCSS_Req 0;
BA_ "GenSigTimeoutTime_BCM" SG_ 1204 RHeatedWindowSts 0;
BA_ "GenSigTimeoutTime_BSM" SG_ 1204 RHeatedWindowSts 0;
BA_ "GenSigTimeoutTime_DIAG_TEST" SG_ 1204 RHeatedWindowSts 0;
BA_ "GenSigTimeoutTime_ECM" SG_ 1204 RHeatedWindowSts 0;
BA_ "GenSigTimeoutTime_EPS" SG_ 1204 RHeatedWindowSts 0;
BA_ "GenSigTimeoutTime_IPC" SG_ 1204 RHeatedWindowSts 0;
BA_ "GenSigTimeoutTime_MTA" SG_ 1204 RHeatedWindowSts 0;
BA_ "GenSigTimeoutTime_ORC" SG_ 1204 RHeatedWindowSts 0;
BA_ "GenSigTimeoutTime_PAM" SG_ 1204 RHeatedWindowSts 0;
BA_ "GenSigTimeoutTime_BCM" SG_ 1049 ABSLamp_FailSts 0;
BA_ "GenSigTimeoutTime_DIAG_TEST" SG_ 1049 ABSLamp_FailSts 0;
BA_ "GenSigTimeoutTime_ECM" SG_ 1049 ABSLamp_FailSts 0;
BA_ "GenSigTimeoutTime_EPS" SG_ 1049 ABSLamp_FailSts 0;
BA_ "GenSigTimeoutTime_IPC" SG_ 1049 ABSLamp_FailSts 0;
BA_ "GenSigTimeoutTime_MTA" SG_ 1049 ABSLamp_FailSts 0;
BA_ "GenSigTimeoutTime_ORC" SG_ 1049 ABSLamp_FailSts 0;
BA_ "GenSigTimeoutTime_PAM" SG_ 1049 ABSLamp_FailSts 0;
BA_ "GenSigTimeoutTime_BCM" SG_ 1049 AirBagLamp_FailSts 0;
BA_ "GenSigTimeoutTime_BSM" SG_ 1049 AirBagLamp_FailSts 0;
BA_ "GenSigTimeoutTime_DIAG_TEST" SG_ 1049 AirBagLamp_FailSts 0;
BA_ "GenSigTimeoutTime_ECM" SG_ 1049 AirBagLamp_FailSts 0;
BA_ "GenSigTimeoutTime_EPS" SG_ 1049 AirBagLamp_FailSts 0;
BA_ "GenSigTimeoutTime_IPC" SG_ 1049 AirBagLamp_FailSts 0;
BA_ "GenSigTimeoutTime_MTA" SG_ 1049 AirBagLamp_FailSts 0;
BA_ "GenSigTimeoutTime_PAM" SG_ 1049 AirBagLamp_FailSts 0;
BA_ "GenSigTimeoutTime_BCM" SG_ 1049 EBDLamp_FailSts 0;
BA_ "GenSigTimeoutTime_DIAG_TEST" SG_ 1049 EBDLamp_FailSts 0;
BA_ "GenSigTimeoutTime_ECM" SG_ 1049 EBDLamp_FailSts 0;
BA_ "GenSigTimeoutTime_EPS" SG_ 1049 EBDLamp_FailSts 0;
BA_ "GenSigTimeoutTime_IPC" SG_ 1049 EBDLamp_FailSts 0;
BA_ "GenSigTimeoutTime_MTA" SG_ 1049 EBDLamp_FailSts 0;
BA_ "GenSigTimeoutTime_ORC" SG_ 1049 EBDLamp_FailSts 0;
BA_ "GenSigTimeoutTime_PAM" SG_ 1049 EBDLamp_FailSts 0;
BA_ "GenSigTimeoutTime_BCM" SG_ 1049 ElectricSteeringLamp_FailSts 0;
BA_ "GenSigTimeoutTime_BSM" SG_ 1049 ElectricSteeringLamp_FailSts 0;
BA_ "GenSigTimeoutTime_DIAG_TEST" SG_ 1049 ElectricSteeringLamp_FailSts 0;
BA_ "GenSigTimeoutTime_ECM" SG_ 1049 ElectricSteeringLamp_FailSts 0;
BA_ "GenSigTimeoutTime_IPC" SG_ 1049 ElectricSteeringLamp_FailSts 0;
BA_ "GenSigTimeoutTime_MTA" SG_ 1049 ElectricSteeringLamp_FailSts 0;
BA_ "GenSigTimeoutTime_ORC" SG_ 1049 ElectricSteeringLamp_FailSts 0;
BA_ "GenSigTimeoutTime_PAM" SG_ 1049 ElectricSteeringLamp_FailSts 0;
BA_ "GenSigTimeoutTime_BCM" SG_ 1049 ESCLamp_FailSts 0;
BA_ "GenSigTimeoutTime_DIAG_TEST" SG_ 1049 ESCLamp_FailSts 0;
BA_ "GenSigTimeoutTime_ECM" SG_ 1049 ESCLamp_FailSts 0;
BA_ "GenSigTimeoutTime_EPS" SG_ 1049 ESCLamp_FailSts 0;
BA_ "GenSigTimeoutTime_IPC" SG_ 1049 ESCLamp_FailSts 0;
BA_ "GenSigTimeoutTime_MTA" SG_ 1049 ESCLamp_FailSts 0;
BA_ "GenSigTimeoutTime_ORC" SG_ 1049 ESCLamp_FailSts 0;
BA_ "GenSigTimeoutTime_PAM" SG_ 1049 ESCLamp_FailSts 0;
BA_ "GenSigTimeoutTime_BCM" SG_ 1049 HHDisablingCommandSts 0;
BA_ "GenSigTimeoutTime_DIAG_TEST" SG_ 1049 HHDisablingCommandSts 0;
BA_ "GenSigTimeoutTime_ECM" SG_ 1049 HHDisablingCommandSts 0;
BA_ "GenSigTimeoutTime_EPS" SG_ 1049 HHDisablingCommandSts 0;
BA_ "GenSigTimeoutTime_IPC" SG_ 1049 HHDisablingCommandSts 0;
BA_ "GenSigTimeoutTime_MTA" SG_ 1049 HHDisablingCommandSts 0;
BA_ "GenSigTimeoutTime_ORC" SG_ 1049 HHDisablingCommandSts 0;
BA_ "GenSigTimeoutTime_PAM" SG_ 1049 HHDisablingCommandSts 0;
BA_ "GenSigStartValue" SG_ 1049 InternalLightLevel 5;
BA_ "GenSigTimeoutTime_BCM" SG_ 1049 InternalLightLevel 0;
BA_ "GenSigTimeoutTime_BSM" SG_ 1049 InternalLightLevel 0;
BA_ "GenSigTimeoutTime_DIAG_TEST" SG_ 1049 InternalLightLevel 0;
BA_ "GenSigTimeoutTime_ECM" SG_ 1049 InternalLightLevel 0;
BA_ "GenSigTimeoutTime_EPS" SG_ 1049 InternalLightLevel 0;
BA_ "GenSigTimeoutTime_IPC" SG_ 1049 InternalLightLevel 0;
BA_ "GenSigTimeoutTime_MTA" SG_ 1049 InternalLightLevel 0;
BA_ "GenSigTimeoutTime_ORC" SG_ 1049 InternalLightLevel 0;
BA_ "GenSigTimeoutTime_PAM" SG_ 1049 InternalLightLevel 0;
BA_ "GenSigTimeoutTime_BSM" SG_ 1049 InternalLightSts 0;
BA_ "GenSigTimeoutTime_DIAG_TEST" SG_ 1049 InternalLightSts 0;
BA_ "GenSigTimeoutTime_ECM" SG_ 1049 InternalLightSts 0;
BA_ "GenSigTimeoutTime_EPS" SG_ 1049 InternalLightSts 0;
BA_ "GenSigTimeoutTime_IPC" SG_ 1049 InternalLightSts 0;
BA_ "GenSigTimeoutTime_MTA" SG_ 1049 InternalLightSts 0;
BA_ "GenSigTimeoutTime_ORC" SG_ 1049 InternalLightSts 0;
BA_ "GenSigTimeoutTime_PAM" SG_ 1049 InternalLightSts 0;
BA_ "GenSigSendType" SG_ 1049 PowerModeSts_IPC 3;
BA_ "GenSigTimeoutTime_BSM" SG_ 1049 PowerModeSts_IPC 0;
BA_ "GenSigTimeoutTime_DIAG_TEST" SG_ 1049 PowerModeSts_IPC 0;
BA_ "GenSigTimeoutTime_ECM" SG_ 1049 PowerModeSts_IPC 0;
BA_ "GenSigTimeoutTime_EPS" SG_ 1049 PowerModeSts_IPC 0;
BA_ "GenSigTimeoutTime_IPC" SG_ 1049 PowerModeSts_IPC 0;
BA_ "GenSigTimeoutTime_MTA" SG_ 1049 PowerModeSts_IPC 0;
BA_ "GenSigTimeoutTime_ORC" SG_ 1049 PowerModeSts_IPC 0;
BA_ "GenSigTimeoutTime_PAM" SG_ 1049 PowerModeSts_IPC 0;
BA_ "GenSigTimeoutTime_BCM" SG_ 1049 PsngrBagLamp_FailSts 0;
BA_ "GenSigTimeoutTime_BSM" SG_ 1049 PsngrBagLamp_FailSts 0;
BA_ "GenSigTimeoutTime_DIAG_TEST" SG_ 1049 PsngrBagLamp_FailSts 0;
BA_ "GenSigTimeoutTime_ECM" SG_ 1049 PsngrBagLamp_FailSts 0;
BA_ "GenSigTimeoutTime_EPS" SG_ 1049 PsngrBagLamp_FailSts 0;
BA_ "GenSigTimeoutTime_IPC" SG_ 1049 PsngrBagLamp_FailSts 0;
BA_ "GenSigTimeoutTime_MTA" SG_ 1049 PsngrBagLamp_FailSts 0;
BA_ "GenSigTimeoutTime_PAM" SG_ 1049 PsngrBagLamp_FailSts 0;
BA_ "GenSigSendType" SG_ 1049 PsngrBagRequestSts 3;
BA_ "GenSigTimeoutTime_BCM" SG_ 1049 PsngrBagRequestSts 0;
BA_ "GenSigTimeoutTime_BSM" SG_ 1049 PsngrBagRequestSts 0;
BA_ "GenSigTimeoutTime_DIAG_TEST" SG_ 1049 PsngrBagRequestSts 0;
BA_ "GenSigTimeoutTime_ECM" SG_ 1049 PsngrBagRequestSts 0;
BA_ "GenSigTimeoutTime_EPS" SG_ 1049 PsngrBagRequestSts 0;
BA_ "GenSigTimeoutTime_IPC" SG_ 1049 PsngrBagRequestSts 0;
BA_ "GenSigTimeoutTime_MTA" SG_ 1049 PsngrBagRequestSts 0;
BA_ "GenSigTimeoutTime_PAM" SG_ 1049 PsngrBagRequestSts 0;
BA_ "GenSigTimeoutTime_BCM" SG_ 1049 SeatBeltLamp_FailSts 0;
BA_ "GenSigTimeoutTime_BSM" SG_ 1049 SeatBeltLamp_FailSts 0;
BA_ "GenSigTimeoutTime_DIAG_TEST" SG_ 1049 SeatBeltLamp_FailSts 0;
BA_ "GenSigTimeoutTime_ECM" SG_ 1049 SeatBeltLamp_FailSts 0;
BA_ "GenSigTimeoutTime_EPS" SG_ 1049 SeatBeltLamp_FailSts 0;
BA_ "GenSigTimeoutTime_IPC" SG_ 1049 SeatBeltLamp_FailSts 0;
BA_ "GenSigTimeoutTime_MTA" SG_ 1049 SeatBeltLamp_FailSts 0;
BA_ "GenSigTimeoutTime_PAM" SG_ 1049 SeatBeltLamp_FailSts 0;
BA_ "GenSigTimeoutTime_BCM" SG_ 1049 TotalOdometer 0;
BA_ "GenSigTimeoutTime_DIAG_TEST" SG_ 1049 TotalOdometer 0;
BA_ "GenSigTimeoutTime_EPS" SG_ 1049 TotalOdometer 0;
BA_ "GenSigTimeoutTime_IPC" SG_ 1049 TotalOdometer 0;
BA_ "GenSigTimeoutTime_BCM" SG_ 1049 TPMCalibrationReqSts 0;
BA_ "GenSigTimeoutTime_DIAG_TEST" SG_ 1049 TPMCalibrationReqSts 0;
BA_ "GenSigTimeoutTime_ECM" SG_ 1049 TPMCalibrationReqSts 0;
BA_ "GenSigTimeoutTime_EPS" SG_ 1049 TPMCalibrationReqSts 0;
BA_ "GenSigTimeoutTime_IPC" SG_ 1049 TPMCalibrationReqSts 0;
BA_ "GenSigTimeoutTime_MTA" SG_ 1049 TPMCalibrationReqSts 0;
BA_ "GenSigTimeoutTime_ORC" SG_ 1049 TPMCalibrationReqSts 0;
BA_ "GenSigTimeoutTime_PAM" SG_ 1049 TPMCalibrationReqSts 0;
BA_ "GenSigStartValue" SG_ 1454 CompressorSts 2;
BA_ "GenSigSendType" SG_ 1454 CompressorSts 4;
BA_ "GenSigTimeoutTime_BSM" SG_ 1454 CompressorSts 0;
BA_ "GenSigTimeoutTime_DIAG_TEST" SG_ 1454 CompressorSts 0;
BA_ "GenSigTimeoutTime_ECM" SG_ 1454 CompressorSts 0;
BA_ "GenSigTimeoutTime_EPS" SG_ 1454 CompressorSts 0;
BA_ "GenSigTimeoutTime_IPC" SG_ 1454 CompressorSts 0;
BA_ "GenSigTimeoutTime_ORC" SG_ 1454 CompressorSts 0;
BA_ "GenSigTimeoutTime_PAM" SG_ 1454 CompressorSts 0;
BA_ "GenSigSendType" SG_ 1454 DrivelineSts 3;
BA_ "GenSigTimeoutTime_BCM" SG_ 1454 DrivelineSts 0;
BA_ "GenSigTimeoutTime_BSM" SG_ 1454 DrivelineSts 0;
BA_ "GenSigTimeoutTime_DIAG_TEST" SG_ 1454 DrivelineSts 0;
BA_ "GenSigTimeoutTime_ECM" SG_ 1454 DrivelineSts 0;
BA_ "GenSigTimeoutTime_EPS" SG_ 1454 DrivelineSts 0;
BA_ "GenSigTimeoutTime_MTA" SG_ 1454 DrivelineSts 0;
BA_ "GenSigTimeoutTime_ORC" SG_ 1454 DrivelineSts 0;
BA_ "GenSigTimeoutTime_PAM" SG_ 1454 DrivelineSts 0;
BA_ "GenSigStartValue" SG_ 1454 EMSFailSts 2;
BA_ "GenSigSendType" SG_ 1454 EMSFailSts 4;
BA_ "GenSigTimeoutTime_BCM" SG_ 1454 EMSFailSts 0;
BA_ "GenSigTimeoutTime_BSM" SG_ 1454 EMSFailSts 0;
BA_ "GenSigTimeoutTime_DIAG_TEST" SG_ 1454 EMSFailSts 0;
BA_ "GenSigTimeoutTime_ECM" SG_ 1454 EMSFailSts 0;
BA_ "GenSigTimeoutTime_EPS" SG_ 1454 EMSFailSts 0;
BA_ "GenSigTimeoutTime_MTA" SG_ 1454 EMSFailSts 0;
BA_ "GenSigTimeoutTime_ORC" SG_ 1454 EMSFailSts 0;
BA_ "GenSigTimeoutTime_PAM" SG_ 1454 EMSFailSts 0;
BA_ "GenSigSendType" SG_ 1454 EngineWaterTempWarningLightSts 4;
BA_ "GenSigTimeoutTime_BCM" SG_ 1454 EngineWaterTempWarningLightSts 0;
BA_ "GenSigTimeoutTime_BSM" SG_ 1454 EngineWaterTempWarningLightSts 0;
BA_ "GenSigTimeoutTime_DIAG_TEST" SG_ 1454 EngineWaterTempWarningLightSts 0;
BA_ "GenSigTimeoutTime_ECM" SG_ 1454 EngineWaterTempWarningLightSts 0;
BA_ "GenSigTimeoutTime_EPS" SG_ 1454 EngineWaterTempWarningLightSts 0;
BA_ "GenSigTimeoutTime_MTA" SG_ 1454 EngineWaterTempWarningLightSts 0;
BA_ "GenSigTimeoutTime_ORC" SG_ 1454 EngineWaterTempWarningLightSts 0;
BA_ "GenSigTimeoutTime_PAM" SG_ 1454 EngineWaterTempWarningLightSts 0;
BA_ "GenSigSendType" SG_ 1454 GlowPlugFailSts 4;
BA_ "GenSigTimeoutTime_BCM" SG_ 1454 GlowPlugFailSts 0;
BA_ "GenSigTimeoutTime_BSM" SG_ 1454 GlowPlugFailSts 0;
BA_ "GenSigTimeoutTime_DIAG_TEST" SG_ 1454 GlowPlugFailSts 0;
BA_ "GenSigTimeoutTime_ECM" SG_ 1454 GlowPlugFailSts 0;
BA_ "GenSigTimeoutTime_EPS" SG_ 1454 GlowPlugFailSts 0;
BA_ "GenSigTimeoutTime_MTA" SG_ 1454 GlowPlugFailSts 0;
BA_ "GenSigTimeoutTime_ORC" SG_ 1454 GlowPlugFailSts 0;
BA_ "GenSigTimeoutTime_PAM" SG_ 1454 GlowPlugFailSts 0;
BA_ "GenSigSendType" SG_ 1454 GlowPlugLampSts 4;
BA_ "GenSigTimeoutTime_BCM" SG_ 1454 GlowPlugLampSts 0;
BA_ "GenSigTimeoutTime_BSM" SG_ 1454 GlowPlugLampSts 0;
BA_ "GenSigTimeoutTime_DIAG_TEST" SG_ 1454 GlowPlugLampSts 0;
BA_ "GenSigTimeoutTime_ECM" SG_ 1454 GlowPlugLampSts 0;
BA_ "GenSigTimeoutTime_EPS" SG_ 1454 GlowPlugLampSts 0;
BA_ "GenSigTimeoutTime_MTA" SG_ 1454 GlowPlugLampSts 0;
BA_ "GenSigTimeoutTime_ORC" SG_ 1454 GlowPlugLampSts 0;
BA_ "GenSigTimeoutTime_PAM" SG_ 1454 GlowPlugLampSts 0;
BA_ "GenSigSendType" SG_ 1454 HCSS_Sts 3;
BA_ "GenSigTimeoutTime_BSM" SG_ 1454 HCSS_Sts 0;
BA_ "GenSigTimeoutTime_DIAG_TEST" SG_ 1454 HCSS_Sts 0;
BA_ "GenSigTimeoutTime_ECM" SG_ 1454 HCSS_Sts 0;
BA_ "GenSigTimeoutTime_EPS" SG_ 1454 HCSS_Sts 0;
BA_ "GenSigTimeoutTime_IPC" SG_ 1454 HCSS_Sts 0;
BA_ "GenSigTimeoutTime_MTA" SG_ 1454 HCSS_Sts 0;
BA_ "GenSigTimeoutTime_ORC" SG_ 1454 HCSS_Sts 0;
BA_ "GenSigTimeoutTime_PAM" SG_ 1454 HCSS_Sts 0;
BA_ "GenSigSendType" SG_ 1454 OilPressureFailSts 4;
BA_ "GenSigTimeoutTime_BCM" SG_ 1454 OilPressureFailSts 0;
BA_ "GenSigTimeoutTime_BSM" SG_ 1454 OilPressureFailSts 0;
BA_ "GenSigTimeoutTime_DIAG_TEST" SG_ 1454 OilPressureFailSts 0;
BA_ "GenSigTimeoutTime_ECM" SG_ 1454 OilPressureFailSts 0;
BA_ "GenSigTimeoutTime_EPS" SG_ 1454 OilPressureFailSts 0;
BA_ "GenSigTimeoutTime_MTA" SG_ 1454 OilPressureFailSts 0;
BA_ "GenSigTimeoutTime_ORC" SG_ 1454 OilPressureFailSts 0;
BA_ "GenSigTimeoutTime_PAM" SG_ 1454 OilPressureFailSts 0;
BA_ "GenSigStartValue" SG_ 1454 OilPressureSts 1;
BA_ "GenSigSendType" SG_ 1454 OilPressureSts 4;
BA_ "GenSigTimeoutTime_BCM" SG_ 1454 OilPressureSts 0;
BA_ "GenSigTimeoutTime_BSM" SG_ 1454 OilPressureSts 0;
BA_ "GenSigTimeoutTime_DIAG_TEST" SG_ 1454 OilPressureSts 0;
BA_ "GenSigTimeoutTime_ECM" SG_ 1454 OilPressureSts 0;
BA_ "GenSigTimeoutTime_EPS" SG_ 1454 OilPressureSts 0;
BA_ "GenSigTimeoutTime_MTA" SG_ 1454 OilPressureSts 0;
BA_ "GenSigTimeoutTime_ORC" SG_ 1454 OilPressureSts 0;
BA_ "GenSigTimeoutTime_PAM" SG_ 1454 OilPressureSts 0;
BA_ "GenSigStartValue" SG_ 600 AirBagFailSts 2;
BA_ "GenSigSendType" SG_ 600 AirBagFailSts 4;
BA_ "GenSigTimeoutTime_BCM" SG_ 600 AirBagFailSts 0;
BA_ "GenSigTimeoutTime_BSM" SG_ 600 AirBagFailSts 0;
BA_ "GenSigTimeoutTime_DIAG_TEST" SG_ 600 AirBagFailSts 0;
BA_ "GenSigTimeoutTime_ECM" SG_ 600 AirBagFailSts 0;
BA_ "GenSigTimeoutTime_EPS" SG_ 600 AirBagFailSts 0;
BA_ "GenSigTimeoutTime_MTA" SG_ 600 AirBagFailSts 0;
BA_ "GenSigTimeoutTime_ORC" SG_ 600 AirBagFailSts 0;
BA_ "GenSigTimeoutTime_PAM" SG_ 600 AirBagFailSts 0;
BA_ "GenSigStartValue" SG_ 600 PsngrBagChargeSts 3;
BA_ "GenSigSendType" SG_ 600 PsngrBagChargeSts 4;
BA_ "GenSigTimeoutTime_BCM" SG_ 600 PsngrBagChargeSts 0;
BA_ "GenSigTimeoutTime_BSM" SG_ 600 PsngrBagChargeSts 0;
BA_ "GenSigTimeoutTime_DIAG_TEST" SG_ 600 PsngrBagChargeSts 0;
BA_ "GenSigTimeoutTime_ECM" SG_ 600 PsngrBagChargeSts 0;
BA_ "GenSigTimeoutTime_EPS" SG_ 600 PsngrBagChargeSts 0;
BA_ "GenSigTimeoutTime_MTA" SG_ 600 PsngrBagChargeSts 0;
BA_ "GenSigTimeoutTime_ORC" SG_ 600 PsngrBagChargeSts 0;
BA_ "GenSigTimeoutTime_PAM" SG_ 600 PsngrBagChargeSts 0;
BA_ "GenSigStartValue" SG_ 600 PsngrBagLightReqSts 3;
BA_ "GenSigSendType" SG_ 600 PsngrBagLightReqSts 4;
BA_ "GenSigTimeoutTime_BCM" SG_ 600 PsngrBagLightReqSts 0;
BA_ "GenSigTimeoutTime_BSM" SG_ 600 PsngrBagLightReqSts 0;
BA_ "GenSigTimeoutTime_DIAG_TEST" SG_ 600 PsngrBagLightReqSts 0;
BA_ "GenSigTimeoutTime_ECM" SG_ 600 PsngrBagLightReqSts 0;
BA_ "GenSigTimeoutTime_EPS" SG_ 600 PsngrBagLightReqSts 0;
BA_ "GenSigTimeoutTime_MTA" SG_ 600 PsngrBagLightReqSts 0;
BA_ "GenSigTimeoutTime_ORC" SG_ 600 PsngrBagLightReqSts 0;
BA_ "GenSigTimeoutTime_PAM" SG_ 600 PsngrBagLightReqSts 0;
BA_ "GenSigTimeoutTime_BCM" SG_ 600 SBR1RowDriverSeatConfigSts 0;
BA_ "GenSigTimeoutTime_BSM" SG_ 600 SBR1RowDriverSeatConfigSts 0;
BA_ "GenSigTimeoutTime_DIAG_TEST" SG_ 600 SBR1RowDriverSeatConfigSts 0;
BA_ "GenSigTimeoutTime_ECM" SG_ 600 SBR1RowDriverSeatConfigSts 0;
BA_ "GenSigTimeoutTime_EPS" SG_ 600 SBR1RowDriverSeatConfigSts 0;
BA_ "GenSigTimeoutTime_MTA" SG_ 600 SBR1RowDriverSeatConfigSts 0;
BA_ "GenSigTimeoutTime_ORC" SG_ 600 SBR1RowDriverSeatConfigSts 0;
BA_ "GenSigTimeoutTime_PAM" SG_ 600 SBR1RowDriverSeatConfigSts 0;
BA_ "GenSigStartValue" SG_ 600 SBR1RowDriverSeatSts 3;
BA_ "GenSigSendType" SG_ 600 SBR1RowDriverSeatSts 4;
BA_ "GenSigTimeoutTime_BSM" SG_ 600 SBR1RowDriverSeatSts 0;
BA_ "GenSigTimeoutTime_DIAG_TEST" SG_ 600 SBR1RowDriverSeatSts 0;
BA_ "GenSigTimeoutTime_ECM" SG_ 600 SBR1RowDriverSeatSts 0;
BA_ "GenSigTimeoutTime_EPS" SG_ 600 SBR1RowDriverSeatSts 0;
BA_ "GenSigTimeoutTime_MTA" SG_ 600 SBR1RowDriverSeatSts 0;
BA_ "GenSigTimeoutTime_ORC" SG_ 600 SBR1RowDriverSeatSts 0;
BA_ "GenSigTimeoutTime_PAM" SG_ 600 SBR1RowDriverSeatSts 0;
BA_ "GenSigTimeoutTime_BCM" SG_ 1354 PAMSystemFault 0;
BA_ "GenSigTimeoutTime_BSM" SG_ 1354 PAMSystemFault 0;
BA_ "GenSigTimeoutTime_DIAG_TEST" SG_ 1354 PAMSystemFault 0;
BA_ "GenSigTimeoutTime_ECM" SG_ 1354 PAMSystemFault 0;
BA_ "GenSigTimeoutTime_EPS" SG_ 1354 PAMSystemFault 0;
BA_ "GenSigTimeoutTime_MTA" SG_ 1354 PAMSystemFault 0;
BA_ "GenSigTimeoutTime_ORC" SG_ 1354 PAMSystemFault 0;
BA_ "GenSigTimeoutTime_PAM" SG_ 1354 PAMSystemFault 0;
BA_ "GenSigTimeoutTime_BCM" SG_ 1354 PAMSystemSts 0;
BA_ "GenSigTimeoutTime_BSM" SG_ 1354 PAMSystemSts 0;
BA_ "GenSigTimeoutTime_DIAG_TEST" SG_ 1354 PAMSystemSts 0;
BA_ "GenSigTimeoutTime_ECM" SG_ 1354 PAMSystemSts 0;
BA_ "GenSigTimeoutTime_EPS" SG_ 1354 PAMSystemSts 0;
BA_ "GenSigTimeoutTime_MTA" SG_ 1354 PAMSystemSts 0;
BA_ "GenSigTimeoutTime_ORC" SG_ 1354 PAMSystemSts 0;
BA_ "GenSigTimeoutTime_PAM" SG_ 1354 PAMSystemSts 0;
BA_ "GenSigSendType" SG_ 1458 BuzzerReqSts 4;
BA_ "GenSigTimeoutTime_BCM" SG_ 1458 BuzzerReqSts 0;
BA_ "GenSigTimeoutTime_BSM" SG_ 1458 BuzzerReqSts 0;
BA_ "GenSigTimeoutTime_DIAG_TEST" SG_ 1458 BuzzerReqSts 0;
BA_ "GenSigTimeoutTime_ECM" SG_ 1458 BuzzerReqSts 0;
BA_ "GenSigTimeoutTime_EPS" SG_ 1458 BuzzerReqSts 0;
BA_ "GenSigTimeoutTime_MTA" SG_ 1458 BuzzerReqSts 0;
BA_ "GenSigTimeoutTime_ORC" SG_ 1458 BuzzerReqSts 0;
BA_ "GenSigTimeoutTime_PAM" SG_ 1458 BuzzerReqSts 0;
BA_ "GenSigSendType" SG_ 1458 DriveModeSts 4;
BA_ "GenSigTimeoutTime_BCM" SG_ 1458 DriveModeSts 0;
BA_ "GenSigTimeoutTime_BSM" SG_ 1458 DriveModeSts 0;
BA_ "GenSigTimeoutTime_DIAG_TEST" SG_ 1458 DriveModeSts 0;
BA_ "GenSigTimeoutTime_EPS" SG_ 1458 DriveModeSts 0;
BA_ "GenSigTimeoutTime_MTA" SG_ 1458 DriveModeSts 0;
BA_ "GenSigTimeoutTime_ORC" SG_ 1458 DriveModeSts 0;
BA_ "GenSigTimeoutTime_PAM" SG_ 1458 DriveModeSts 0;
BA_ "GenSigSendType" SG_ 1458 GearIndicationSts 4;
BA_ "GenSigTimeoutTime_BCM" SG_ 1458 GearIndicationSts 0;
BA_ "GenSigTimeoutTime_BSM" SG_ 1458 GearIndicationSts 0;
BA_ "GenSigTimeoutTime_DIAG_TEST" SG_ 1458 GearIndicationSts 0;
BA_ "GenSigTimeoutTime_ECM" SG_ 1458 GearIndicationSts 0;
BA_ "GenSigTimeoutTime_EPS" SG_ 1458 GearIndicationSts 0;
BA_ "GenSigTimeoutTime_MTA" SG_ 1458 GearIndicationSts 0;
BA_ "GenSigTimeoutTime_ORC" SG_ 1458 GearIndicationSts 0;
BA_ "GenSigTimeoutTime_PAM" SG_ 1458 GearIndicationSts 0;
BA_ "GenSigSendType" SG_ 1458 RoboticTransmissionFailCodes 4;
BA_ "GenSigTimeoutTime_BCM" SG_ 1458 RoboticTransmissionFailCodes 0;
BA_ "GenSigTimeoutTime_BSM" SG_ 1458 RoboticTransmissionFailCodes 0;
BA_ "GenSigTimeoutTime_DIAG_TEST" SG_ 1458 RoboticTransmissionFailCodes 0;
BA_ "GenSigTimeoutTime_ECM" SG_ 1458 RoboticTransmissionFailCodes 0;
BA_ "GenSigTimeoutTime_EPS" SG_ 1458 RoboticTransmissionFailCodes 0;
BA_ "GenSigTimeoutTime_MTA" SG_ 1458 RoboticTransmissionFailCodes 0;
BA_ "GenSigTimeoutTime_ORC" SG_ 1458 RoboticTransmissionFailCodes 0;
BA_ "GenSigTimeoutTime_PAM" SG_ 1458 RoboticTransmissionFailCodes 0;
BA_ "GenSigSendType" SG_ 1458 RoboticTransmissionWarnings 4;
BA_ "GenSigTimeoutTime_BCM" SG_ 1458 RoboticTransmissionWarnings 0;
BA_ "GenSigTimeoutTime_BSM" SG_ 1458 RoboticTransmissionWarnings 0;
BA_ "GenSigTimeoutTime_DIAG_TEST" SG_ 1458 RoboticTransmissionWarnings 0;
BA_ "GenSigTimeoutTime_ECM" SG_ 1458 RoboticTransmissionWarnings 0;
BA_ "GenSigTimeoutTime_EPS" SG_ 1458 RoboticTransmissionWarnings 0;
BA_ "GenSigTimeoutTime_MTA" SG_ 1458 RoboticTransmissionWarnings 0;
BA_ "GenSigTimeoutTime_ORC" SG_ 1458 RoboticTransmissionWarnings 0;
BA_ "GenSigTimeoutTime_PAM" SG_ 1458 RoboticTransmissionWarnings 0;
BA_ "GenSigSendType" SG_ 1458 ShiftModeSts 4;
BA_ "GenSigTimeoutTime_BSM" SG_ 1458 ShiftModeSts 0;
BA_ "GenSigTimeoutTime_DIAG_TEST" SG_ 1458 ShiftModeSts 0;
BA_ "GenSigTimeoutTime_ECM" SG_ 1458 ShiftModeSts 0;
BA_ "GenSigTimeoutTime_EPS" SG_ 1458 ShiftModeSts 0;
BA_ "GenSigTimeoutTime_MTA" SG_ 1458 ShiftModeSts 0;
BA_ "GenSigTimeoutTime_ORC" SG_ 1458 ShiftModeSts 0;
BA_ "GenSigTimeoutTime_PAM" SG_ 1458 ShiftModeSts 0;
BA_ "GenSigTimeoutTime_BCM" SG_ 1850 Day1 0;
BA_ "GenSigTimeoutTime_DIAG_TEST" SG_ 1850 Day1 0;
BA_ "GenSigTimeoutTime_EPS" SG_ 1850 Day1 0;
BA_ "GenSigTimeoutTime_IPC" SG_ 1850 Day1 0;
BA_ "GenSigTimeoutTime_MTA" SG_ 1850 Day1 0;
BA_ "GenSigTimeoutTime_ORC" SG_ 1850 Day1 0;
BA_ "GenSigTimeoutTime_PAM" SG_ 1850 Day1 0;
BA_ "GenSigTimeoutTime_BCM" SG_ 1850 Day2 0;
BA_ "GenSigTimeoutTime_DIAG_TEST" SG_ 1850 Day2 0;
BA_ "GenSigTimeoutTime_EPS" SG_ 1850 Day2 0;
BA_ "GenSigTimeoutTime_IPC" SG_ 1850 Day2 0;
BA_ "GenSigTimeoutTime_MTA" SG_ 1850 Day2 0;
BA_ "GenSigTimeoutTime_ORC" SG_ 1850 Day2 0;
BA_ "GenSigTimeoutTime_PAM" SG_ 1850 Day2 0;
BA_ "GenSigTimeoutTime_BCM" SG_ 1850 Hour1 0;
BA_ "GenSigTimeoutTime_DIAG_TEST" SG_ 1850 Hour1 0;
BA_ "GenSigTimeoutTime_EPS" SG_ 1850 Hour1 0;
BA_ "GenSigTimeoutTime_IPC" SG_ 1850 Hour1 0;
BA_ "GenSigTimeoutTime_MTA" SG_ 1850 Hour1 0;
BA_ "GenSigTimeoutTime_ORC" SG_ 1850 Hour1 0;
BA_ "GenSigTimeoutTime_PAM" SG_ 1850 Hour1 0;
BA_ "GenSigTimeoutTime_BCM" SG_ 1850 Hour2 0;
BA_ "GenSigTimeoutTime_DIAG_TEST" SG_ 1850 Hour2 0;
BA_ "GenSigTimeoutTime_EPS" SG_ 1850 Hour2 0;
BA_ "GenSigTimeoutTime_IPC" SG_ 1850 Hour2 0;
BA_ "GenSigTimeoutTime_MTA" SG_ 1850 Hour2 0;
BA_ "GenSigTimeoutTime_ORC" SG_ 1850 Hour2 0;
BA_ "GenSigTimeoutTime_PAM" SG_ 1850 Hour2 0;
BA_ "GenSigTimeoutTime_BCM" SG_ 1850 Minute1 0;
BA_ "GenSigTimeoutTime_DIAG_TEST" SG_ 1850 Minute1 0;
BA_ "GenSigTimeoutTime_EPS" SG_ 1850 Minute1 0;
BA_ "GenSigTimeoutTime_IPC" SG_ 1850 Minute1 0;
BA_ "GenSigTimeoutTime_MTA" SG_ 1850 Minute1 0;
BA_ "GenSigTimeoutTime_ORC" SG_ 1850 Minute1 0;
BA_ "GenSigTimeoutTime_PAM" SG_ 1850 Minute1 0;
BA_ "GenSigTimeoutTime_BCM" SG_ 1850 Minute2 0;
BA_ "GenSigTimeoutTime_DIAG_TEST" SG_ 1850 Minute2 0;
BA_ "GenSigTimeoutTime_EPS" SG_ 1850 Minute2 0;
BA_ "GenSigTimeoutTime_IPC" SG_ 1850 Minute2 0;
BA_ "GenSigTimeoutTime_MTA" SG_ 1850 Minute2 0;
BA_ "GenSigTimeoutTime_ORC" SG_ 1850 Minute2 0;
BA_ "GenSigTimeoutTime_PAM" SG_ 1850 Minute2 0;
BA_ "GenSigTimeoutTime_BCM" SG_ 1850 Month1 0;
BA_ "GenSigTimeoutTime_DIAG_TEST" SG_ 1850 Month1 0;
BA_ "GenSigTimeoutTime_EPS" SG_ 1850 Month1 0;
BA_ "GenSigTimeoutTime_IPC" SG_ 1850 Month1 0;
BA_ "GenSigTimeoutTime_MTA" SG_ 1850 Month1 0;
BA_ "GenSigTimeoutTime_ORC" SG_ 1850 Month1 0;
BA_ "GenSigTimeoutTime_PAM" SG_ 1850 Month1 0;
BA_ "GenSigTimeoutTime_BCM" SG_ 1850 Month2 0;
BA_ "GenSigTimeoutTime_DIAG_TEST" SG_ 1850 Month2 0;
BA_ "GenSigTimeoutTime_EPS" SG_ 1850 Month2 0;
BA_ "GenSigTimeoutTime_IPC" SG_ 1850 Month2 0;
BA_ "GenSigTimeoutTime_MTA" SG_ 1850 Month2 0;
BA_ "GenSigTimeoutTime_ORC" SG_ 1850 Month2 0;
BA_ "GenSigTimeoutTime_PAM" SG_ 1850 Month2 0;
BA_ "GenSigTimeoutTime_BCM" SG_ 1850 Year1 0;
BA_ "GenSigTimeoutTime_DIAG_TEST" SG_ 1850 Year1 0;
BA_ "GenSigTimeoutTime_EPS" SG_ 1850 Year1 0;
BA_ "GenSigTimeoutTime_IPC" SG_ 1850 Year1 0;
BA_ "GenSigTimeoutTime_MTA" SG_ 1850 Year1 0;
BA_ "GenSigTimeoutTime_ORC" SG_ 1850 Year1 0;
BA_ "GenSigTimeoutTime_PAM" SG_ 1850 Year1 0;
BA_ "GenSigTimeoutTime_BCM" SG_ 1850 Year2 0;
BA_ "GenSigTimeoutTime_DIAG_TEST" SG_ 1850 Year2 0;
BA_ "GenSigTimeoutTime_EPS" SG_ 1850 Year2 0;
BA_ "GenSigTimeoutTime_IPC" SG_ 1850 Year2 0;
BA_ "GenSigTimeoutTime_MTA" SG_ 1850 Year2 0;
BA_ "GenSigTimeoutTime_ORC" SG_ 1850 Year2 0;
BA_ "GenSigTimeoutTime_PAM" SG_ 1850 Year2 0;
BA_ "GenSigTimeoutTime_BCM" SG_ 1850 Year3 0;
BA_ "GenSigTimeoutTime_DIAG_TEST" SG_ 1850 Year3 0;
BA_ "GenSigTimeoutTime_EPS" SG_ 1850 Year3 0;
BA_ "GenSigTimeoutTime_IPC" SG_ 1850 Year3 0;
BA_ "GenSigTimeoutTime_MTA" SG_ 1850 Year3 0;
BA_ "GenSigTimeoutTime_ORC" SG_ 1850 Year3 0;
BA_ "GenSigTimeoutTime_PAM" SG_ 1850 Year3 0;
BA_ "GenSigTimeoutTime_BCM" SG_ 1850 Year4 0;
BA_ "GenSigTimeoutTime_DIAG_TEST" SG_ 1850 Year4 0;
BA_ "GenSigTimeoutTime_EPS" SG_ 1850 Year4 0;
BA_ "GenSigTimeoutTime_IPC" SG_ 1850 Year4 0;
BA_ "GenSigTimeoutTime_MTA" SG_ 1850 Year4 0;
BA_ "GenSigTimeoutTime_ORC" SG_ 1850 Year4 0;
BA_ "GenSigTimeoutTime_PAM" SG_ 1850 Year4 0;
BA_ "GenSigSendType" SG_ 1000 CalibrationAck 6;
BA_ "GenSigTimeoutTime_BCM" SG_ 1000 CalibrationAck 0;
BA_ "GenSigTimeoutTime_BSM" SG_ 1000 CalibrationAck 0;
BA_ "GenSigTimeoutTime_DIAG_TEST" SG_ 1000 CalibrationAck 0;
BA_ "GenSigTimeoutTime_ECM" SG_ 1000 CalibrationAck 0;
BA_ "GenSigTimeoutTime_EPS" SG_ 1000 CalibrationAck 0;
BA_ "GenSigTimeoutTime_MTA" SG_ 1000 CalibrationAck 0;
BA_ "GenSigTimeoutTime_ORC" SG_ 1000 CalibrationAck 0;
BA_ "GenSigTimeoutTime_PAM" SG_ 1000 CalibrationAck 0;
BA_ "GenSigTimeoutTime_BCM" SG_ 246 ClutchEngaged 0;
BA_ "GenSigTimeoutTime_BSM" SG_ 246 ClutchEngaged 0;
BA_ "GenSigTimeoutTime_DIAG_TEST" SG_ 246 ClutchEngaged 0;
BA_ "GenSigTimeoutTime_EPS" SG_ 246 ClutchEngaged 0;
BA_ "GenSigTimeoutTime_IPC" SG_ 246 ClutchEngaged 0;
BA_ "GenSigTimeoutTime_MTA" SG_ 246 ClutchEngaged 0;
BA_ "GenSigTimeoutTime_ORC" SG_ 246 ClutchEngaged 0;
BA_ "GenSigTimeoutTime_PAM" SG_ 246 ClutchEngaged 0;
BA_ "GenSigTimeoutTime_BCM" SG_ 246 CRC_T1 0;
BA_ "GenSigTimeoutTime_BSM" SG_ 246 CRC_T1 0;
BA_ "GenSigTimeoutTime_DIAG_TEST" SG_ 246 CRC_T1 0;
BA_ "GenSigTimeoutTime_EPS" SG_ 246 CRC_T1 0;
BA_ "GenSigTimeoutTime_IPC" SG_ 246 CRC_T1 0;
BA_ "GenSigTimeoutTime_MTA" SG_ 246 CRC_T1 0;
BA_ "GenSigTimeoutTime_ORC" SG_ 246 CRC_T1 0;
BA_ "GenSigTimeoutTime_PAM" SG_ 246 CRC_T1 0;
BA_ "GenSigTimeoutTime_BCM" SG_ 246 DriveOff 0;
BA_ "GenSigTimeoutTime_BSM" SG_ 246 DriveOff 0;
BA_ "GenSigTimeoutTime_DIAG_TEST" SG_ 246 DriveOff 0;
BA_ "GenSigTimeoutTime_EPS" SG_ 246 DriveOff 0;
BA_ "GenSigTimeoutTime_IPC" SG_ 246 DriveOff 0;
BA_ "GenSigTimeoutTime_MTA" SG_ 246 DriveOff 0;
BA_ "GenSigTimeoutTime_ORC" SG_ 246 DriveOff 0;
BA_ "GenSigTimeoutTime_PAM" SG_ 246 DriveOff 0;
BA_ "GenSigTimeoutTime_BCM" SG_ 246 EngineStopSignal 0;
BA_ "GenSigTimeoutTime_BSM" SG_ 246 EngineStopSignal 0;
BA_ "GenSigTimeoutTime_DIAG_TEST" SG_ 246 EngineStopSignal 0;
BA_ "GenSigTimeoutTime_EPS" SG_ 246 EngineStopSignal 0;
BA_ "GenSigTimeoutTime_IPC" SG_ 246 EngineStopSignal 0;
BA_ "GenSigTimeoutTime_MTA" SG_ 246 EngineStopSignal 0;
BA_ "GenSigTimeoutTime_ORC" SG_ 246 EngineStopSignal 0;
BA_ "GenSigTimeoutTime_PAM" SG_ 246 EngineStopSignal 0;
BA_ "GenSigTimeoutTime_BCM" SG_ 246 GearBoxAutomaticMode 0;
BA_ "GenSigTimeoutTime_BSM" SG_ 246 GearBoxAutomaticMode 0;
BA_ "GenSigTimeoutTime_DIAG_TEST" SG_ 246 GearBoxAutomaticMode 0;
BA_ "GenSigTimeoutTime_EPS" SG_ 246 GearBoxAutomaticMode 0;
BA_ "GenSigTimeoutTime_IPC" SG_ 246 GearBoxAutomaticMode 0;
BA_ "GenSigTimeoutTime_MTA" SG_ 246 GearBoxAutomaticMode 0;
BA_ "GenSigTimeoutTime_ORC" SG_ 246 GearBoxAutomaticMode 0;
BA_ "GenSigTimeoutTime_PAM" SG_ 246 GearBoxAutomaticMode 0;
BA_ "GenSigTimeoutTime_BCM" SG_ 246 GearEngaged 0;
BA_ "GenSigTimeoutTime_DIAG_TEST" SG_ 246 GearEngaged 0;
BA_ "GenSigTimeoutTime_EPS" SG_ 246 GearEngaged 0;
BA_ "GenSigTimeoutTime_MTA" SG_ 246 GearEngaged 0;
BA_ "GenSigTimeoutTime_ORC" SG_ 246 GearEngaged 0;
BA_ "GenSigTimeoutTime_PAM" SG_ 246 GearEngaged 0;
BA_ "GenSigStartValue" SG_ 246 LeverPosition 9;
BA_ "GenSigTimeoutTime_BCM" SG_ 246 LeverPosition 0;
BA_ "GenSigTimeoutTime_BSM" SG_ 246 LeverPosition 0;
BA_ "GenSigTimeoutTime_DIAG_TEST" SG_ 246 LeverPosition 0;
BA_ "GenSigTimeoutTime_EPS" SG_ 246 LeverPosition 0;
BA_ "GenSigTimeoutTime_IPC" SG_ 246 LeverPosition 0;
BA_ "GenSigTimeoutTime_MTA" SG_ 246 LeverPosition 0;
BA_ "GenSigTimeoutTime_ORC" SG_ 246 LeverPosition 0;
BA_ "GenSigTimeoutTime_PAM" SG_ 246 LeverPosition 0;
BA_ "GenSigTimeoutTime_BCM" SG_ 246 LimpHomeSts 0;
BA_ "GenSigTimeoutTime_BSM" SG_ 246 LimpHomeSts 0;
BA_ "GenSigTimeoutTime_DIAG_TEST" SG_ 246 LimpHomeSts 0;
BA_ "GenSigTimeoutTime_EPS" SG_ 246 LimpHomeSts 0;
BA_ "GenSigTimeoutTime_IPC" SG_ 246 LimpHomeSts 0;
BA_ "GenSigTimeoutTime_MTA" SG_ 246 LimpHomeSts 0;
BA_ "GenSigTimeoutTime_ORC" SG_ 246 LimpHomeSts 0;
BA_ "GenSigTimeoutTime_PAM" SG_ 246 LimpHomeSts 0;
BA_ "GenSigTimeoutTime_BCM" SG_ 246 MessageCounter_T1 0;
BA_ "GenSigTimeoutTime_BSM" SG_ 246 MessageCounter_T1 0;
BA_ "GenSigTimeoutTime_DIAG_TEST" SG_ 246 MessageCounter_T1 0;
BA_ "GenSigTimeoutTime_EPS" SG_ 246 MessageCounter_T1 0;
BA_ "GenSigTimeoutTime_IPC" SG_ 246 MessageCounter_T1 0;
BA_ "GenSigTimeoutTime_MTA" SG_ 246 MessageCounter_T1 0;
BA_ "GenSigTimeoutTime_ORC" SG_ 246 MessageCounter_T1 0;
BA_ "GenSigTimeoutTime_PAM" SG_ 246 MessageCounter_T1 0;
BA_ "GenSigTimeoutTime_BCM" SG_ 246 ReqTorqueValue 0;
BA_ "GenSigTimeoutTime_BSM" SG_ 246 ReqTorqueValue 0;
BA_ "GenSigTimeoutTime_DIAG_TEST" SG_ 246 ReqTorqueValue 0;
BA_ "GenSigTimeoutTime_EPS" SG_ 246 ReqTorqueValue 0;
BA_ "GenSigTimeoutTime_IPC" SG_ 246 ReqTorqueValue 0;
BA_ "GenSigTimeoutTime_MTA" SG_ 246 ReqTorqueValue 0;
BA_ "GenSigTimeoutTime_ORC" SG_ 246 ReqTorqueValue 0;
BA_ "GenSigTimeoutTime_PAM" SG_ 246 ReqTorqueValue 0;
BA_ "GenSigTimeoutTime_BCM" SG_ 246 ReqTorqueValueCost 0;
BA_ "GenSigTimeoutTime_BSM" SG_ 246 ReqTorqueValueCost 0;
BA_ "GenSigTimeoutTime_DIAG_TEST" SG_ 246 ReqTorqueValueCost 0;
BA_ "GenSigTimeoutTime_EPS" SG_ 246 ReqTorqueValueCost 0;
BA_ "GenSigTimeoutTime_IPC" SG_ 246 ReqTorqueValueCost 0;
BA_ "GenSigTimeoutTime_MTA" SG_ 246 ReqTorqueValueCost 0;
BA_ "GenSigTimeoutTime_ORC" SG_ 246 ReqTorqueValueCost 0;
BA_ "GenSigTimeoutTime_PAM" SG_ 246 ReqTorqueValueCost 0;
BA_ "GenSigTimeoutTime_BCM" SG_ 246 ReqTorqueValueDown 0;
BA_ "GenSigTimeoutTime_BSM" SG_ 246 ReqTorqueValueDown 0;
BA_ "GenSigTimeoutTime_DIAG_TEST" SG_ 246 ReqTorqueValueDown 0;
BA_ "GenSigTimeoutTime_EPS" SG_ 246 ReqTorqueValueDown 0;
BA_ "GenSigTimeoutTime_IPC" SG_ 246 ReqTorqueValueDown 0;
BA_ "GenSigTimeoutTime_MTA" SG_ 246 ReqTorqueValueDown 0;
BA_ "GenSigTimeoutTime_ORC" SG_ 246 ReqTorqueValueDown 0;
BA_ "GenSigTimeoutTime_PAM" SG_ 246 ReqTorqueValueDown 0;
BA_ "GenSigTimeoutTime_BCM" SG_ 246 ReqTorqueValueUp 0;
BA_ "GenSigTimeoutTime_BSM" SG_ 246 ReqTorqueValueUp 0;
BA_ "GenSigTimeoutTime_DIAG_TEST" SG_ 246 ReqTorqueValueUp 0;
BA_ "GenSigTimeoutTime_EPS" SG_ 246 ReqTorqueValueUp 0;
BA_ "GenSigTimeoutTime_IPC" SG_ 246 ReqTorqueValueUp 0;
BA_ "GenSigTimeoutTime_MTA" SG_ 246 ReqTorqueValueUp 0;
BA_ "GenSigTimeoutTime_ORC" SG_ 246 ReqTorqueValueUp 0;
BA_ "GenSigTimeoutTime_PAM" SG_ 246 ReqTorqueValueUp 0;
BA_ "GenSigTimeoutTime_BCM" SG_ 246 TakeOffModeReq 0;
BA_ "GenSigTimeoutTime_BSM" SG_ 246 TakeOffModeReq 0;
BA_ "GenSigTimeoutTime_DIAG_TEST" SG_ 246 TakeOffModeReq 0;
BA_ "GenSigTimeoutTime_EPS" SG_ 246 TakeOffModeReq 0;
BA_ "GenSigTimeoutTime_IPC" SG_ 246 TakeOffModeReq 0;
BA_ "GenSigTimeoutTime_MTA" SG_ 246 TakeOffModeReq 0;
BA_ "GenSigTimeoutTime_ORC" SG_ 246 TakeOffModeReq 0;
BA_ "GenSigTimeoutTime_PAM" SG_ 246 TakeOffModeReq 0;
BA_ "GenSigTimeoutTime_BCM" SG_ 246 TakeOffRPMValueReq 0;
BA_ "GenSigTimeoutTime_BSM" SG_ 246 TakeOffRPMValueReq 0;
BA_ "GenSigTimeoutTime_DIAG_TEST" SG_ 246 TakeOffRPMValueReq 0;
BA_ "GenSigTimeoutTime_EPS" SG_ 246 TakeOffRPMValueReq 0;
BA_ "GenSigTimeoutTime_IPC" SG_ 246 TakeOffRPMValueReq 0;
BA_ "GenSigTimeoutTime_MTA" SG_ 246 TakeOffRPMValueReq 0;
BA_ "GenSigTimeoutTime_ORC" SG_ 246 TakeOffRPMValueReq 0;
BA_ "GenSigTimeoutTime_PAM" SG_ 246 TakeOffRPMValueReq 0;
BA_ "GenSigTimeoutTime_BCM" SG_ 246 TorqueControl 0;
BA_ "GenSigTimeoutTime_BSM" SG_ 246 TorqueControl 0;
BA_ "GenSigTimeoutTime_DIAG_TEST" SG_ 246 TorqueControl 0;
BA_ "GenSigTimeoutTime_EPS" SG_ 246 TorqueControl 0;
BA_ "GenSigTimeoutTime_IPC" SG_ 246 TorqueControl 0;
BA_ "GenSigTimeoutTime_MTA" SG_ 246 TorqueControl 0;
BA_ "GenSigTimeoutTime_ORC" SG_ 246 TorqueControl 0;
BA_ "GenSigTimeoutTime_PAM" SG_ 246 TorqueControl 0;
BA_ "GenSigTimeoutTime_BCM" SG_ 246 UpDownShiftSel 0;
BA_ "GenSigTimeoutTime_BSM" SG_ 246 UpDownShiftSel 0;
BA_ "GenSigTimeoutTime_DIAG_TEST" SG_ 246 UpDownShiftSel 0;
BA_ "GenSigTimeoutTime_EPS" SG_ 246 UpDownShiftSel 0;
BA_ "GenSigTimeoutTime_IPC" SG_ 246 UpDownShiftSel 0;
BA_ "GenSigTimeoutTime_MTA" SG_ 246 UpDownShiftSel 0;
BA_ "GenSigTimeoutTime_ORC" SG_ 246 UpDownShiftSel 0;
BA_ "GenSigTimeoutTime_PAM" SG_ 246 UpDownShiftSel 0;
BA_ "GenSigTimeoutTime_BSM" SG_ 234 CrankEnable 0;
BA_ "GenSigTimeoutTime_DIAG_TEST" SG_ 234 CrankEnable 0;
BA_ "GenSigTimeoutTime_EPS" SG_ 234 CrankEnable 0;
BA_ "GenSigTimeoutTime_IPC" SG_ 234 CrankEnable 0;
BA_ "GenSigTimeoutTime_MTA" SG_ 234 CrankEnable 0;
BA_ "GenSigTimeoutTime_ORC" SG_ 234 CrankEnable 0;
BA_ "GenSigTimeoutTime_PAM" SG_ 234 CrankEnable 0;
BA_ "GenSigTimeoutTime_BCM" SG_ 234 HydraulicPumpActive 0;
BA_ "GenSigTimeoutTime_BSM" SG_ 234 HydraulicPumpActive 0;
BA_ "GenSigTimeoutTime_DIAG_TEST" SG_ 234 HydraulicPumpActive 0;
BA_ "GenSigTimeoutTime_EPS" SG_ 234 HydraulicPumpActive 0;
BA_ "GenSigTimeoutTime_IPC" SG_ 234 HydraulicPumpActive 0;
BA_ "GenSigTimeoutTime_MTA" SG_ 234 HydraulicPumpActive 0;
BA_ "GenSigTimeoutTime_ORC" SG_ 234 HydraulicPumpActive 0;
BA_ "GenSigTimeoutTime_PAM" SG_ 234 HydraulicPumpActive 0;
BA_ "GenSigStartValue" SG_ 234 ShiftLeverPosition 9;
BA_ "GenSigTimeoutTime_DIAG_TEST" SG_ 234 ShiftLeverPosition 0;
BA_ "GenSigTimeoutTime_EPS" SG_ 234 ShiftLeverPosition 0;
BA_ "GenSigTimeoutTime_IPC" SG_ 234 ShiftLeverPosition 0;
BA_ "GenSigTimeoutTime_MTA" SG_ 234 ShiftLeverPosition 0;
BA_ "GenSigTimeoutTime_ORC" SG_ 234 ShiftLeverPosition 0;
BA_ "GenSigTimeoutTime_PAM" SG_ 234 ShiftLeverPosition 0;
BA_ "GenSigTimeoutTime_BSM" SG_ 278 LHF_FastPulseCounter 0;
BA_ "GenSigTimeoutTime_DIAG_TEST" SG_ 278 LHF_FastPulseCounter 0;
BA_ "GenSigTimeoutTime_ECM" SG_ 278 LHF_FastPulseCounter 0;
BA_ "GenSigTimeoutTime_EPS" SG_ 278 LHF_FastPulseCounter 0;
BA_ "GenSigTimeoutTime_IPC" SG_ 278 LHF_FastPulseCounter 0;
BA_ "GenSigTimeoutTime_MTA" SG_ 278 LHF_FastPulseCounter 0;
BA_ "GenSigTimeoutTime_ORC" SG_ 278 LHF_FastPulseCounter 0;
BA_ "GenSigTimeoutTime_PAM" SG_ 278 LHF_FastPulseCounter 0;
BA_ "GenSigTimeoutTime_BSM" SG_ 278 LHF_WheelSensorFailSts 0;
BA_ "GenSigTimeoutTime_DIAG_TEST" SG_ 278 LHF_WheelSensorFailSts 0;
BA_ "GenSigTimeoutTime_ECM" SG_ 278 LHF_WheelSensorFailSts 0;
BA_ "GenSigTimeoutTime_EPS" SG_ 278 LHF_WheelSensorFailSts 0;
BA_ "GenSigTimeoutTime_IPC" SG_ 278 LHF_WheelSensorFailSts 0;
BA_ "GenSigTimeoutTime_MTA" SG_ 278 LHF_WheelSensorFailSts 0;
BA_ "GenSigTimeoutTime_ORC" SG_ 278 LHF_WheelSensorFailSts 0;
BA_ "GenSigTimeoutTime_PAM" SG_ 278 LHF_WheelSensorFailSts 0;
BA_ "GenSigTimeoutTime_BSM" SG_ 278 LHR_FastPulseCounter 0;
BA_ "GenSigTimeoutTime_DIAG_TEST" SG_ 278 LHR_FastPulseCounter 0;
BA_ "GenSigTimeoutTime_ECM" SG_ 278 LHR_FastPulseCounter 0;
BA_ "GenSigTimeoutTime_EPS" SG_ 278 LHR_FastPulseCounter 0;
BA_ "GenSigTimeoutTime_IPC" SG_ 278 LHR_FastPulseCounter 0;
BA_ "GenSigTimeoutTime_MTA" SG_ 278 LHR_FastPulseCounter 0;
BA_ "GenSigTimeoutTime_ORC" SG_ 278 LHR_FastPulseCounter 0;
BA_ "GenSigTimeoutTime_PAM" SG_ 278 LHR_FastPulseCounter 0;
BA_ "GenSigTimeoutTime_BSM" SG_ 278 LHR_WheelSensorFailSts 0;
BA_ "GenSigTimeoutTime_DIAG_TEST" SG_ 278 LHR_WheelSensorFailSts 0;
BA_ "GenSigTimeoutTime_ECM" SG_ 278 LHR_WheelSensorFailSts 0;
BA_ "GenSigTimeoutTime_EPS" SG_ 278 LHR_WheelSensorFailSts 0;
BA_ "GenSigTimeoutTime_IPC" SG_ 278 LHR_WheelSensorFailSts 0;
BA_ "GenSigTimeoutTime_MTA" SG_ 278 LHR_WheelSensorFailSts 0;
BA_ "GenSigTimeoutTime_ORC" SG_ 278 LHR_WheelSensorFailSts 0;
BA_ "GenSigTimeoutTime_PAM" SG_ 278 LHR_WheelSensorFailSts 0;
BA_ "GenSigTimeoutTime_BSM" SG_ 278 RHF_FastPulseCounter 0;
BA_ "GenSigTimeoutTime_DIAG_TEST" SG_ 278 RHF_FastPulseCounter 0;
BA_ "GenSigTimeoutTime_ECM" SG_ 278 RHF_FastPulseCounter 0;
BA_ "GenSigTimeoutTime_EPS" SG_ 278 RHF_FastPulseCounter 0;
BA_ "GenSigTimeoutTime_IPC" SG_ 278 RHF_FastPulseCounter 0;
BA_ "GenSigTimeoutTime_MTA" SG_ 278 RHF_FastPulseCounter 0;
BA_ "GenSigTimeoutTime_ORC" SG_ 278 RHF_FastPulseCounter 0;
BA_ "GenSigTimeoutTime_PAM" SG_ 278 RHF_FastPulseCounter 0;
BA_ "GenSigTimeoutTime_BSM" SG_ 278 RHF_WheelSensorFailSts 0;
BA_ "GenSigTimeoutTime_DIAG_TEST" SG_ 278 RHF_WheelSensorFailSts 0;
BA_ "GenSigTimeoutTime_ECM" SG_ 278 RHF_WheelSensorFailSts 0;
BA_ "GenSigTimeoutTime_EPS" SG_ 278 RHF_WheelSensorFailSts 0;
BA_ "GenSigTimeoutTime_IPC" SG_ 278 RHF_WheelSensorFailSts 0;
BA_ "GenSigTimeoutTime_MTA" SG_ 278 RHF_WheelSensorFailSts 0;
BA_ "GenSigTimeoutTime_ORC" SG_ 278 RHF_WheelSensorFailSts 0;
BA_ "GenSigTimeoutTime_PAM" SG_ 278 RHF_WheelSensorFailSts 0;
BA_ "GenSigTimeoutTime_BSM" SG_ 278 RHR_FastPulseCounter 0;
BA_ "GenSigTimeoutTime_DIAG_TEST" SG_ 278 RHR_FastPulseCounter 0;
BA_ "GenSigTimeoutTime_ECM" SG_ 278 RHR_FastPulseCounter 0;
BA_ "GenSigTimeoutTime_EPS" SG_ 278 RHR_FastPulseCounter 0;
BA_ "GenSigTimeoutTime_IPC" SG_ 278 RHR_FastPulseCounter 0;
BA_ "GenSigTimeoutTime_MTA" SG_ 278 RHR_FastPulseCounter 0;
BA_ "GenSigTimeoutTime_ORC" SG_ 278 RHR_FastPulseCounter 0;
BA_ "GenSigTimeoutTime_PAM" SG_ 278 RHR_FastPulseCounter 0;
BA_ "GenSigTimeoutTime_BSM" SG_ 278 RHR_WheelSensorFailSts 0;
BA_ "GenSigTimeoutTime_DIAG_TEST" SG_ 278 RHR_WheelSensorFailSts 0;
BA_ "GenSigTimeoutTime_ECM" SG_ 278 RHR_WheelSensorFailSts 0;
BA_ "GenSigTimeoutTime_EPS" SG_ 278 RHR_WheelSensorFailSts 0;
BA_ "GenSigTimeoutTime_IPC" SG_ 278 RHR_WheelSensorFailSts 0;
BA_ "GenSigTimeoutTime_MTA" SG_ 278 RHR_WheelSensorFailSts 0;
BA_ "GenSigTimeoutTime_ORC" SG_ 278 RHR_WheelSensorFailSts 0;
BA_ "GenSigTimeoutTime_PAM" SG_ 278 RHR_WheelSensorFailSts 0;
BA_ "GenSigTimeoutTime_BCM" SG_ 238 LHFWheelSpeed 0;
BA_ "GenSigTimeoutTime_BSM" SG_ 238 LHFWheelSpeed 0;
BA_ "GenSigTimeoutTime_DIAG_TEST" SG_ 238 LHFWheelSpeed 0;
BA_ "GenSigTimeoutTime_EPS" SG_ 238 LHFWheelSpeed 0;
BA_ "GenSigTimeoutTime_IPC" SG_ 238 LHFWheelSpeed 0;
BA_ "GenSigTimeoutTime_ORC" SG_ 238 LHFWheelSpeed 0;
BA_ "GenSigTimeoutTime_PAM" SG_ 238 LHFWheelSpeed 0;
BA_ "GenSigTimeoutTime_BCM" SG_ 238 LHRWheelSpeed 0;
BA_ "GenSigTimeoutTime_BSM" SG_ 238 LHRWheelSpeed 0;
BA_ "GenSigTimeoutTime_DIAG_TEST" SG_ 238 LHRWheelSpeed 0;
BA_ "GenSigTimeoutTime_EPS" SG_ 238 LHRWheelSpeed 0;
BA_ "GenSigTimeoutTime_IPC" SG_ 238 LHRWheelSpeed 0;
BA_ "GenSigTimeoutTime_ORC" SG_ 238 LHRWheelSpeed 0;
BA_ "GenSigTimeoutTime_PAM" SG_ 238 LHRWheelSpeed 0;
BA_ "GenSigTimeoutTime_BCM" SG_ 238 RHFWheelSpeed 0;
BA_ "GenSigTimeoutTime_BSM" SG_ 238 RHFWheelSpeed 0;
BA_ "GenSigTimeoutTime_DIAG_TEST" SG_ 238 RHFWheelSpeed 0;
BA_ "GenSigTimeoutTime_EPS" SG_ 238 RHFWheelSpeed 0;
BA_ "GenSigTimeoutTime_IPC" SG_ 238 RHFWheelSpeed 0;
BA_ "GenSigTimeoutTime_ORC" SG_ 238 RHFWheelSpeed 0;
BA_ "GenSigTimeoutTime_PAM" SG_ 238 RHFWheelSpeed 0;
BA_ "GenSigTimeoutTime_BCM" SG_ 238 RHRWheelSpeed 0;
BA_ "GenSigTimeoutTime_BSM" SG_ 238 RHRWheelSpeed 0;
BA_ "GenSigTimeoutTime_DIAG_TEST" SG_ 238 RHRWheelSpeed 0;
BA_ "GenSigTimeoutTime_EPS" SG_ 238 RHRWheelSpeed 0;
BA_ "GenSigTimeoutTime_IPC" SG_ 238 RHRWheelSpeed 0;
BA_ "GenSigTimeoutTime_ORC" SG_ 238 RHRWheelSpeed 0;
BA_ "GenSigTimeoutTime_PAM" SG_ 238 RHRWheelSpeed 0;
VAL_ 2654339098 CurrentFailSts_ORC 0 "No_Fail_Present" 1 "Fail_Present" ;
VAL_ 2654339098 DES_ORC 0 "No_Busoff" 1 "Busoff_Occurred" ;
VAL_ 2654339098 EOL_ORC 0 "No_EOL_Programming" 1 "EOL_Programming" ;
VAL_ 2654339098 GenericFailSts_ORC 0 "No_Fail_Present" 1 "Fail_Present" ;
VAL_ 2654339098 StayActiveSource_ORC_0 0 "Active" 1 "NotActive" ;
VAL_ 2654339098 StayActiveSource_ORC_1 0 "Active" 1 "NotActive" ;
VAL_ 2654339098 StayActiveSource_ORC_10 0 "Active" 1 "NotActive" ;
VAL_ 2654339098 StayActiveSource_ORC_11 0 "Active" 1 "NotActive" ;
VAL_ 2654339098 StayActiveSource_ORC_12 0 "Active" 1 "NotActive" ;
VAL_ 2654339098 StayActiveSource_ORC_13 0 "Active" 1 "NotActive" ;
VAL_ 2654339098 StayActiveSource_ORC_14 0 "Active" 1 "NotActive" ;
VAL_ 2654339098 StayActiveSource_ORC_15 0 "Active" 1 "NotActive" ;
VAL_ 2654339098 StayActiveSource_ORC_2 0 "Active" 1 "NotActive" ;
VAL_ 2654339098 StayActiveSource_ORC_3 0 "Active" 1 "NotActive" ;
VAL_ 2654339098 StayActiveSource_ORC_4 0 "Active" 1 "NotActive" ;
VAL_ 2654339098 StayActiveSource_ORC_5 0 "Active" 1 "NotActive" ;
VAL_ 2654339098 StayActiveSource_ORC_6 0 "Active" 1 "NotActive" ;
VAL_ 2654339098 StayActiveSource_ORC_7 0 "Active" 1 "NotActive" ;
VAL_ 2654339098 StayActiveSource_ORC_8 0 "Active" 1 "NotActive" ;
VAL_ 2654339098 StayActiveSource_ORC_9 0 "Active" 1 "NotActive" ;
VAL_ 2654339096 CurrentFailSts_PAM 0 "No_Fail_Present" 1 "Fail_Present" ;
VAL_ 2654339096 DES_PAM 0 "No_Busoff" 1 "Busoff_Occurred" ;
VAL_ 2654339096 EOL_PAM 0 "No_EOL_Programming" 1 "EOL_Programming" ;
VAL_ 2654339096 GenericFailSts_PAM 0 "No_Fail_Present" 1 "Fail_Present" ;
VAL_ 2654339096 StayActiveSource_PAM_0 0 "Active" 1 "NotActive" ;
VAL_ 2654339096 StayActiveSource_PAM_1 0 "Active" 1 "NotActive" ;
VAL_ 2654339096 StayActiveSource_PAM_10 0 "Active" 1 "NotActive" ;
VAL_ 2654339096 StayActiveSource_PAM_11 0 "Active" 1 "NotActive" ;
VAL_ 2654339096 StayActiveSource_PAM_12 0 "Active" 1 "NotActive" ;
VAL_ 2654339096 StayActiveSource_PAM_13 0 "Active" 1 "NotActive" ;
VAL_ 2654339096 StayActiveSource_PAM_14 0 "Active" 1 "NotActive" ;
VAL_ 2654339096 StayActiveSource_PAM_15 0 "Active" 1 "NotActive" ;
VAL_ 2654339096 StayActiveSource_PAM_2 0 "Active" 1 "NotActive" ;
VAL_ 2654339096 StayActiveSource_PAM_3 0 "Active" 1 "NotActive" ;
VAL_ 2654339096 StayActiveSource_PAM_4 0 "Active" 1 "NotActive" ;
VAL_ 2654339096 StayActiveSource_PAM_5 0 "Active" 1 "NotActive" ;
VAL_ 2654339096 StayActiveSource_PAM_6 0 "Active" 1 "NotActive" ;
VAL_ 2654339096 StayActiveSource_PAM_7 0 "Active" 1 "NotActive" ;
VAL_ 2654339096 StayActiveSource_PAM_8 0 "Active" 1 "NotActive" ;
VAL_ 2654339096 StayActiveSource_PAM_9 0 "Active" 1 "NotActive" ;
VAL_ 2654339083 CurrentFailSts_TRANSM 0 "No_Fail_Present" 1 "Fail_Present" ;
VAL_ 2654339083 DES_TRANSM 0 "No_Busoff" 1 "Busoff_Occurred" ;
VAL_ 2654339083 EOL_TRANSM 0 "No_EOL_Programming" 1 "EOL_Programming" ;
VAL_ 2654339083 GenericFailSts_TRANSM 0 "No_Fail_Present" 1 "Fail_Present" ;
VAL_ 2654339083 StayActiveSource_TRANSM_0 0 "Active" 1 "NotActive" ;
VAL_ 2654339083 StayActiveSource_TRANSM_1 0 "Active" 1 "NotActive" ;
VAL_ 2654339083 StayActiveSource_TRANSM_10 0 "Active" 1 "NotActive" ;
VAL_ 2654339083 StayActiveSource_TRANSM_11 0 "Active" 1 "NotActive" ;
VAL_ 2654339083 StayActiveSource_TRANSM_12 0 "Active" 1 "NotActive" ;
VAL_ 2654339083 StayActiveSource_TRANSM_13 0 "Active" 1 "NotActive" ;
VAL_ 2654339083 StayActiveSource_TRANSM_14 0 "Active" 1 "NotActive" ;
VAL_ 2654339083 StayActiveSource_TRANSM_15 0 "Active" 1 "NotActive" ;
VAL_ 2654339083 StayActiveSource_TRANSM_2 0 "Active" 1 "NotActive" ;
VAL_ 2654339083 StayActiveSource_TRANSM_3 0 "Active" 1 "NotActive" ;
VAL_ 2654339083 StayActiveSource_TRANSM_4 0 "Active" 1 "NotActive" ;
VAL_ 2654339083 StayActiveSource_TRANSM_5 0 "Active" 1 "NotActive" ;
VAL_ 2654339083 StayActiveSource_TRANSM_6 0 "Active" 1 "NotActive" ;
VAL_ 2654339083 StayActiveSource_TRANSM_7 0 "Active" 1 "NotActive" ;
VAL_ 2654339083 StayActiveSource_TRANSM_8 0 "Active" 1 "NotActive" ;
VAL_ 2654339083 StayActiveSource_TRANSM_9 0 "Active" 1 "NotActive" ;
VAL_ 249 CreepingClutchTargetTorque 255 "SNA" ;
VAL_ 249 CreepingClutchTorque 255 "SNA" ;
VAL_ 249 CreepingEnable 0 "Not_Active" 1 "Active" ;
VAL_ 1200 ABSFailSts 0 "Fail_Not_Present" 1 "Fail_Present" ;
VAL_ 1200 EBDFailSts 0 "Fail_Not_Present" 1 "Fail_Present" ;
VAL_ 1200 ESCFailSts 0 "Fail_Not_Present" 1 "Fail_Present" ;
VAL_ 1200 ESCIntervention 0 "No_intervention" 1 "Intervention_blinking_lamp" ;
VAL_ 1200 FunctionFailSts 0 "Fail_Not_Present" 1 "Fail_Present" ;
VAL_ 1200 FunctionIntervention 0 "No_intervention" 1 "Intervention_blinking_lamp" ;
VAL_ 1200 FunctionSts 0 "Not_Pressed" 1 "Pressed" ;
VAL_ 1200 HillHolderFailSts 0 "Fail_not_present" 1 "Fail_present" ;
VAL_ 1200 TPMActivitySts 0 "TPM_Enabled" 1 "TPM_Disabled" ;
VAL_ 1200 TravelDistance 255 "SNA" ;
VAL_ 1200 TyreInflationState_LHF_Tyre 0 "Normal_Tyre_Pressure" 1 "Under_Inflated_Tyre" 2 "Significantly_Under_Inflated_Tyre" 3 "Over_Inflated_Tyre" ;
VAL_ 1200 TyreInflationState_LHR_Tyre 0 "Normal_Tyre_Pressure" 1 "Under_Inflated_Tyre" 2 "Significantly_Under_Inflated_Tyre" 3 "Over_Inflated_Tyre" ;
VAL_ 1200 TyreInflationState_RHF_Tyre 0 "Normal_Tyre_Pressure" 1 "Under_Inflated_Tyre" 2 "Significantly_Under_Inflated_Tyre" 3 "Over_Inflated_Tyre" ;
VAL_ 1200 TyreInflationState_RHR_Tyre 0 "Normal_Tyre_Pressure" 1 "Under_Inflated_Tyre" 2 "Significantly_Under_Inflated_Tyre" 3 "Over_Inflated_Tyre" ;
VAL_ 1200 TyrePressureSystemFailSts 0 "Fail_Not_Present" 1 "Fail_Present" ;
VAL_ 1350 BatteryChargeSts 15 "SNA" ;
VAL_ 1350 BCMAutoCrankSts 0 "Auto_Crank_Disabled" 1 "Auto_Crank_Enabled" ;
VAL_ 1350 BCMAutoStopEnabledSts 0 "False" 1 "True" ;
VAL_ 1350 BCMAutoStopStaySts 0 "Remain_In_Stop" 1 "Recrank_Engine" ;
VAL_ 1350 BCMStopStartButtonSts 0 "S_S_Off" 1 "S_S_On" ;
VAL_ 1350 ChkFuelLevelSts 0 "Fault_Not_Present" 1 "Chk_Code_1" 2 "Chk_Code_2" 3 "Chk_Code_3" 4 "Chk_Code_4" 5 "Not_Used" 6 "Not_Used" 7 "Not_Used" ;
VAL_ 1350 ExternalTemperature 511 "SNA" ;
VAL_ 1350 ExternalTemperatureFailSts 0 "Fail_not_present" 1 "Fail_present" ;
VAL_ 1350 FpsNotAvailable 0 "FPS_Available" 1 "FPS_Not_Available" ;
VAL_ 1350 FuelLevel 255 "SNA" ;
VAL_ 1350 FuelLevelFailSts 0 "Fail_Not_Present" 1 "Fail_Present" ;
VAL_ 1350 NotFilteredExternalTemp 511 "SNA" ;
VAL_ 1350 NotFilteredFuelLevel 255 "SNA" ;
VAL_ 1350 PowerModeSts 0 "Standard_Power" 1 "Logistic_Mode_ON" 2 "Logistic_Mode_PR" 3 "LogisticModeON_and_EngineON" ;
VAL_ 1204 BrakeFluidLevelSts 0 "OK" 1 "Low_Level" ;
VAL_ 1204 CityModeSts 0 "Normal" 1 "City" ;
VAL_ 1204 CmdIgn_FailSts 0 "Fail_Not_Present" 1 "Fail_Present" 3 "SNA" ;
VAL_ 1204 CmdIgnSts 0 "Initialization" 1 "IGN_LK" 3 "ACC" 4 "RUN" 5 "START" 7 "SNA" ;
VAL_ 1204 CompressorACReqSts 0 "Not_Active" 1 "Active" ;
VAL_ 1204 DriverDoorSts 0 "Closed" 1 "Open" ;
VAL_ 1204 FHeatedWindowSts 0 "OFF" 1 "ON" ;
VAL_ 1204 HandBrakeSts 0 "OFF" 1 "ON" ;
VAL_ 1204 HCSS_Req 0 "Not_Requested" 1 "Requested" ;
VAL_ 1204 RHeatedWindowSts 0 "OFF" 1 "ON" ;
VAL_ 1049 ABSLamp_FailSts 0 "OFF_Fail_not_present" 1 "OFF_Fail_present" 2 "ON_Fail_not_present" 3 "Not_used" ;
VAL_ 1049 AirBagLamp_FailSts 0 "OFF_Fail_not_present" 1 "OFF_Fail_present" 2 "ON_Fail_not_present" 3 "BLINKING_Fail_not_present" ;
VAL_ 1049 EBDLamp_FailSts 0 "OFF_Fail_not_present" 1 "OFF_Fail_present" 2 "ON_Fail_not_present" 3 "Not_used" ;
VAL_ 1049 ElectricSteeringLamp_FailSts 0 "OFF_Fail_not_present" 1 "OFF_Fail_present" 2 "ON_Fail_not_present" 3 "Not_used" ;
VAL_ 1049 ESCLamp_FailSts 0 "OFF_Fail_not_present" 1 "OFF_Fail_present" 2 "ON_Fail_not_present" 3 "Not_used" ;
VAL_ 1049 HHDisablingCommandSts 0 "Enabled" 1 "Disabled" ;
VAL_ 1049 InternalLightLevel 0 "Level_1" 1 "Level_2" 2 "Level_3" 3 "Level_4" 4 "Level_5" 5 "Level_6" 6 "Level_7" 7 "Level_8" 8 "Level_9" 9 "Level_10" 10 "Level_11" 11 "Level_12" 12 "Level_13" 13 "Level_14" 14 "Level_15" 15 "Level_16" ;
VAL_ 1049 InternalLightSts 0 "Not_Active" 1 "Active" ;
VAL_ 1049 PowerModeSts_IPC 0 "Standard_Power" 1 "Logistic_Mode_ON" 2 "Logistic_Mode_PR" 3 "Not_Used" ;
VAL_ 1049 PsngrBagLamp_FailSts 0 "OFF_Fail_not_present" 1 "OFF_Fail_present" 2 "ON_Fail_not_present" 3 "BLINKING_Fail_not_present" ;
VAL_ 1049 PsngrBagRequestSts 0 "Not_Request" 1 "Enable" 2 "Disable" 3 "Not_Used" ;
VAL_ 1049 SeatBeltLamp_FailSts 0 "OFF_Fail_not_present" 1 "OFF_Fail_present" 2 "ON_Fail_not_present" 3 "Not_used" ;
VAL_ 1049 TPMCalibrationReqSts 0 "Not_Active" 1 "Active" ;
VAL_ 1454 CompressorSts 0 "Not_Used" 1 "Not_inserted_by_NCM" 2 "Not_insrtd_by_driver_or_security" 3 "Inserted" ;
VAL_ 1454 DrivelineSts 0 "Open" 1 "Closed" 3 "SNA" ;
VAL_ 1454 EMSFailSts 0 "Fail_Not_Present" 1 "Fail_Flash_Light_Indication" 2 "Fail_Fix_Light_Indication" 3 "Flash_For_Service" ;
VAL_ 1454 EngineWaterTempWarningLightSts 0 "OFF" 1 "ON" ;
VAL_ 1454 GlowPlugFailSts 0 "Fail_Not_Present" 1 "Fail_Present" ;
VAL_ 1454 GlowPlugLampSts 0 "OFF" 1 "ON" ;
VAL_ 1454 HCSS_Sts 0 "Off" 1 "Heating" 2 "Complete" 3 "WarmUp" 4 "PostWarmUp" 5 "Fault" ;
VAL_ 1454 OilPressureFailSts 0 "Fail_Not_Present" 1 "Fail_Present" ;
VAL_ 1454 OilPressureSts 0 "Normal_Pressure" 1 "Low_Pressure" ;
VAL_ 600 AirBagFailSts 0 "Fail_Not_Present_Lamp_Off" 1 "Fail_Not_Present_Lamp_Flashing" 2 "Fail_Present_Lamp_On" 3 "Not_Used" ;
VAL_ 600 PsngrBagChargeSts 0 "Active" 1 "Not_Active" 2 "Not_Present" 3 "SNA" ;
VAL_ 600 PsngrBagLightReqSts 0 "Lamp_Off" 1 "Lamp_Flashing" 2 "Lamp_On" 3 "SNA" ;
VAL_ 600 SBR1RowDriverSeatConfigSts 0 "Seat_Not_Checked" 1 "Seat_Checked" ;
VAL_ 600 SBR1RowDriverSeatSts 0 "Seat_Belt_Fasten" 1 "Seat_Belt_Not_Fasten" 3 "SNA" ;
VAL_ 1354 PAMSystemFault 0 "False" 1 "Front_Failure" 2 "Rear_Failure" 3 "System_Failure" ;
VAL_ 1354 PAMSystemSts 0 "OFF" 1 "ON_Active" 2 "ON_Inactive" 3 "ON_Disabled" ;
VAL_ 1458 BuzzerReqSts 0 "OFF" 1 "Reverse_Gear_Sound_ON" 2 "Others_case_Sound_ON" 3 "Not_used" ;
VAL_ 1458 DriveModeSts 0 "No_programs_available_selected" 1 "Eco" 2 "Sport" 3 "Not_used" 4 "Ice_Winter" 5 "Tow_Haul" 6 "Overdrive" 7 "Not_used" ;
VAL_ 1458 GearIndicationSts 0 "Normal" 1 "Blinking" ;
VAL_ 1458 RoboticTransmissionFailCodes 0 "Fail_NotPresent" 1 "TCM_Warnig_Present" 2 "TCMVehicleInterface_Fail_Present" 3 "TCMInternal_Fail_Present" ;
VAL_ 1458 RoboticTransmissionWarnings 0 "No_Warning" 1 "Press_Brake_Pedal" 2 "Tip_Not_Available" 3 "Lower_Gear_Shifts" 4 "Manual_Mode_Not_Available" 5 "Insert_N" 6 "Automatic_Mode_Not_Available" 7 "Press_Brake_Delayed_Startup" 8 "Clutch_Overtemperature" 9 "Manoeuvre_Not_Allowed" 10 "Press_Brake_Pedal_Repeat" 11 "Gear_Not_Available" 12 "Shift_Not_Allowed" 13 "Shift_to_Neutral_Then_DR" 14 "Reduce_Gear_Changes" 15 "Clutch_Overheater_Must_Cool" 16 "Service_Transmission" 17 "Service_Shifter" 18 "Engage_Park_Brake" 19 "Trans_Too_Cold_Pls_Wait" 20 "Push_Button_to_Shift" 21 "Return_Shifter_To_Home" 22 "Press_Brake_Push_Button_Shift" 23 "Service_Trans_Shut_Off" 24 "Already_in_Des_Gear" 25 "Start_Engine_to_Shift" 26 "Service_Trans_Use_Pk_Brk" 27 "Vehicle_Speed_Too_High" 28 "Tow_Haul_Not_available" 29 "Tow_Haul_Disengaged" 30 "not_used" 31 "not_used" 32 "not_used" 33 "not_used" 34 "not_used" 35 "not_used" 36 "not_used" 37 "not_used" 38 "not_used" 39 "not_used" 40 "not_used" 41 "not_used" 42 "not_used" 43 "not_used" 44 "not_used" 45 "not_used" 46 "not_used" 47 "not_used" 48 "not_used" 49 "not_used" 50 "not_used" 51 "not_used" 52 "not_used" 53 "not_used" 54 "not_used" 55 "not_used" 56 "not_used" 57 "not_used" 58 "not_used" 59 "not_used" 60 "not_used" 61 "not_used" 62 "not_used" 63 "not_used" ;
VAL_ 1458 ShiftModeSts 0 "Manual" 1 "Automatic" ;
VAL_ 1000 CalibrationAck 0 "Idle" 1 "Accepted " 2 "Rejected" 3 "Not_Used" ;
VAL_ 246 ClutchEngaged 0 "ClutchEngaged" 1 "ClutchSlipping_BeforeEngage" 2 "ClutchSlipping_AfterDisengage" 3 "ClutchDisengaged" ;
VAL_ 246 DriveOff 0 "ON" 1 "OFF" ;
VAL_ 246 EngineStopSignal 0 "NoChange" 1 "Stop" ;
VAL_ 246 GearBoxAutomaticMode 0 "NotActive" 1 "Active" ;
VAL_ 246 GearEngaged 0 "Neutral" 1 "ForwardGear_1" 2 "ForwardGear_2" 3 "ForwardGear_3" 4 "ForwardGear_4" 5 "ForwardGear_5" 6 "ForwardGear_6" 7 "ReverseGear" 8 "ForwardGear_7" 9 "ForwardGear_8" 10 "ForwardGear_9" 15 "SNA" ;
VAL_ 246 LeverPosition 0 "No_Selection_Active_Or_Available" 1 "P" 2 "R" 3 "N" 4 "D" 5 "L" 6 "TIP_Autostick" 7 "Plus" 8 "Minus" 9 "SNA" 10 "Not_Used" 11 "Not_Used" 12 "Not_Used" 13 "Not_Used" 14 "Not_Used" 15 "Not_Used" ;
VAL_ 246 LimpHomeSts 0 "NotActive" 1 "Active" ;
VAL_ 246 ReqTorqueValue 2047 "SNA" ;
VAL_ 246 ReqTorqueValueCost 0 "NotActive" 1 "Active" ;
VAL_ 246 ReqTorqueValueDown 0 "NotActive" 1 "Active" ;
VAL_ 246 ReqTorqueValueUp 0 "NotActive" 1 "Active" ;
VAL_ 246 TakeOffModeReq 0 "No_Request" 1 "Torque_Request" 2 "RPM_Request" 3 "TorqueRPMRequest" ;
VAL_ 246 TorqueControl 0 "NoControl" 1 "Control" ;
VAL_ 246 UpDownShiftSel 0 "Up" 1 "Down" ;
VAL_ 234 CrankEnable 0 "Disabled" 1 "Enabled" ;
VAL_ 234 HydraulicPumpActive 0 "NotActive" 1 "Active" ;
VAL_ 234 ShiftLeverPosition 0 "No_Selection_Active_Or_Available" 1 "P" 2 "R" 3 "N" 4 "D" 5 "L" 6 "TIP_Autostick" 7 "Plus" 8 "Minus" 9 "SNA" 10 "Not_Used" 11 "Not_Used" 12 "Not_Used" 13 "Not_Used" 14 "Not_Used" 15 "Not_Used" ;
VAL_ 278 LHF_FastPulseCounter 255 "SNA" ;
VAL_ 278 LHF_WheelSensorFailSts 0 "Fail_Not_Present" 1 "Fail_Present" ;
VAL_ 278 LHR_FastPulseCounter 255 "SNA" ;
VAL_ 278 LHR_WheelSensorFailSts 0 "Fail_Not_Present" 1 "Fail_Present" ;
VAL_ 278 RHF_FastPulseCounter 255 "SNA" ;
VAL_ 278 RHF_WheelSensorFailSts 0 "Fail_Not_Present" 1 "Fail_Present" ;
VAL_ 278 RHR_FastPulseCounter 255 "SNA" ;
VAL_ 278 RHR_WheelSensorFailSts 0 "Fail_Not_Present" 1 "Fail_Present" ;
VAL_ 238 LHFWheelSpeed 8191 "SNA" ;
VAL_ 238 LHRWheelSpeed 8191 "SNA" ;
VAL_ 238 RHFWheelSpeed 8191 "SNA" ;
VAL_ 238 RHRWheelSpeed 8191 "SNA" ;
